VERSION ""

NS_ :

BS_:

BU_: VMCU TPM RCIOM FCIOM FAS ECUspare4 EBS EAS CCIOM BPMU APM

BO_ 1995 XCP_FA_22_Chassi: 8 RCIOM
 SG_ XCP_FA_22 : 0|64@1+ (1,0) [0|0] "" Vector__XXX

BO_ 1994 XCP_FA_21_Chassi: 8 FCIOM
 SG_ XCP_FA_21 : 0|64@1+ (1,0) [0|0] "" Vector__XXX

BO_ 1993 XCP_FA_20_Chassi: 8 CCIOM
 SG_ XCP_FA_20 : 0|64@1+ (1,0) [0|0] "" Vector__XXX

BO_ 1991 XCP_22_FA_Chassi: 8 Vector__XXX
 SG_ XCP_22_FA : 0|64@1+ (1,0) [0|0] ""  RCIOM

BO_ 1990 XCP_21_FA_Chassi: 8 Vector__XXX
 SG_ XCP_21_FA : 0|64@1+ (1,0) [0|0] ""  FCIOM

BO_ 1989 XCP_20_FA_Chassi: 8 Vector__XXX
 SG_ XCP_20_FA : 0|64@1+ (1,0) [0|0] ""  CCIOM

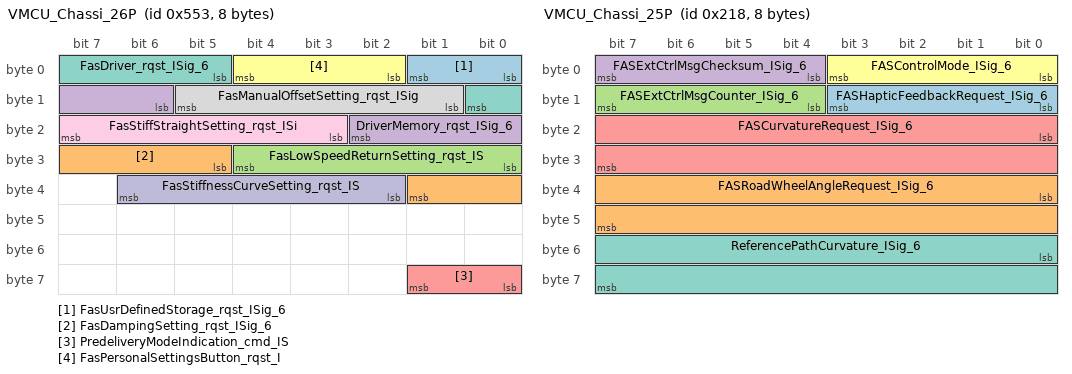
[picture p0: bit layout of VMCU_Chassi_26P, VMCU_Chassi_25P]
BO_ 1363 VMCU_Chassi_26P: 8 VMCU
 SG_ FasUsrDefinedStorage_rqst_ISig_6 : 0|2@1+ (1,0) [0|0] ""  FAS
 SG_ FasDampingSetting_rqst_ISig_6 : 29|5@1+ (1,-10) [-10|21] ""  FAS
 SG_ FasLowSpeedReturnSetting_rqst_IS : 24|5@1+ (1,-10) [-10|21] ""  FAS
 SG_ DriverMemory_rqst_ISig_6 : 14|5@1+ (1,0) [0|0] ""  FAS
 SG_ PredeliveryModeIndication_cmd_IS : 56|2@1+ (1,0) [0|0] ""  BPMU
 SG_ FasPersonalSettingsButton_rqst_I : 2|3@1+ (1,0) [0|0] ""  FAS
 SG_ FasDriver_rqst_ISig_6 : 5|4@1+ (1,0) [0|0] ""  FAS
 SG_ FasManualOffsetSetting_rqst_ISig : 9|5@1+ (1,-10) [-10|21] ""  FAS
 SG_ FasStiffStraightSetting_rqst_ISi : 19|5@1+ (1,-10) [-10|21] ""  FAS
 SG_ FasStiffnessCurveSetting_rqst_IS : 34|5@1+ (1,-10) [-10|21] ""  FAS

BO_ 536 VMCU_Chassi_25P: 8 VMCU
 SG_ FASHapticFeedbackRequest_ISig_6 : 8|4@1+ (1,0) [0|0] ""  FAS
 SG_ FASRoadWheelAngleRequest_ISig_6 : 32|16@1+ (5E-005,-1.6) [-1.6|1.67675] "rad"  FAS
 SG_ FASExtCtrlMsgCounter_ISig_6 : 12|4@1+ (1,0) [0|0] ""  FAS
 SG_ FASExtCtrlMsgChecksum_ISig_6 : 4|4@1+ (1,0) [0|0] ""  FAS
 SG_ FASCurvatureRequest_ISig_6 : 16|16@1+ (7.62939E-006,-0.2472) [-0.2472|0.25279207365] "per_meter"  FAS
 SG_ FASControlMode_ISig_6 : 0|4@1+ (0.1,0) [0|1.5] ""  FAS
 SG_ ReferencePathCurvature_ISig_6 : 48|16@1+ (7.62939E-006,-0.2472) [-0.2472|0.25279207365] "per_meter"  FAS

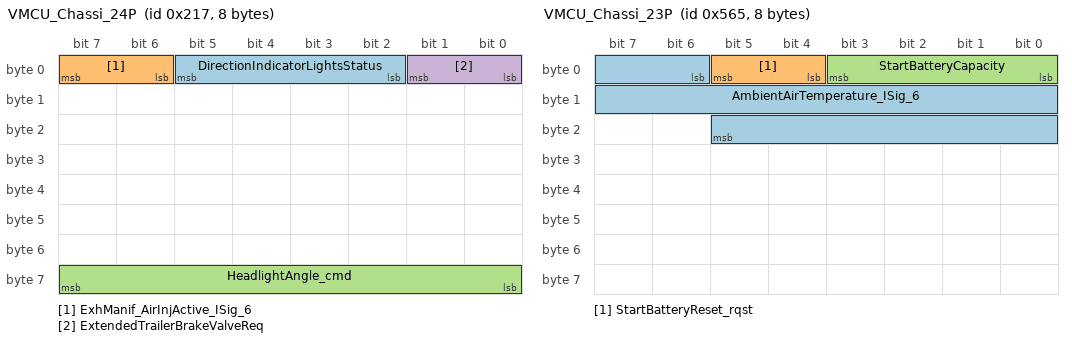
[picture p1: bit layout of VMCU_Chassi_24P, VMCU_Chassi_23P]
BO_ 535 VMCU_Chassi_24P: 8 VMCU
 SG_ DirectionIndicatorLightsStatus : 2|4@1+ (1,0) [0|0] ""  RCIOM,FCIOM
 SG_ ExhManif_AirInjActive_ISig_6 : 6|2@1+ (1,0) [0|0] ""  APM
 SG_ HeadlightAngle_cmd : 56|8@1+ (0.025,-4) [-4|2.375] "deg"  FCIOM
 SG_ ExtendedTrailerBrakeValveReq : 0|2@1+ (1,0) [0|0] ""  CCIOM

BO_ 1381 VMCU_Chassi_23P: 8 VMCU
 SG_ AmbientAirTemperature_ISig_6 : 6|16@1+ (0.03125,-273) [-273|1774.96875] "DegreeC"  BPMU,EAS,FCIOM,CCIOM,FAS,APM,TPM,RCIOM
 SG_ StartBatteryReset_rqst : 4|2@1+ (1,0) [0|0] ""  BPMU
 SG_ StartBatteryCapacity : 0|4@1+ (1,0) [0|0] ""  BPMU

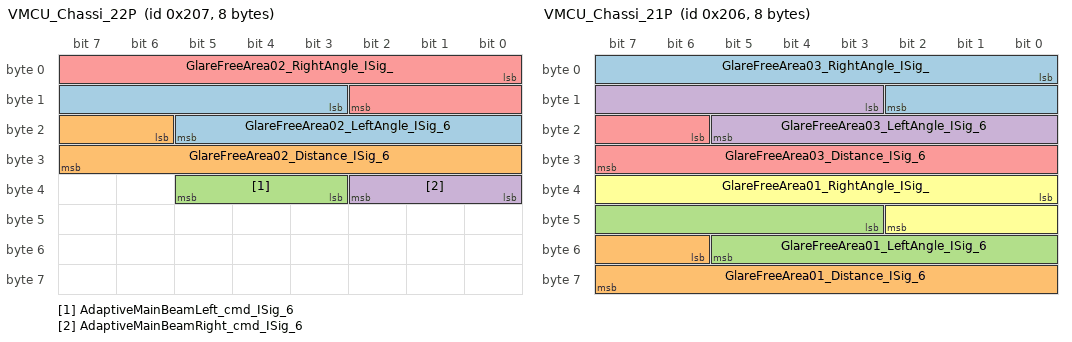
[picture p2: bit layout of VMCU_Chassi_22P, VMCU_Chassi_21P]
BO_ 519 VMCU_Chassi_22P: 8 VMCU
 SG_ GlareFreeArea02_LeftAngle_ISig_6 : 11|11@1+ (0.0494,-31.65) [-31.65|69.4718] "deg"  FCIOM
 SG_ GlareFreeArea02_Distance_ISig_6 : 22|10@1+ (0.5,0) [0|511.5] "m"  FCIOM
 SG_ AdaptiveMainBeamLeft_cmd_ISig_6 : 35|3@1+ (1,0) [0|0] ""  FCIOM
 SG_ AdaptiveMainBeamRight_cmd_ISig_6 : 32|3@1+ (1,0) [0|0] ""  FCIOM
 SG_ GlareFreeArea02_RightAngle_ISig_ : 0|11@1+ (0.0494,-31.65) [-31.65|69.4718] "deg"  FCIOM

BO_ 518 VMCU_Chassi_21P: 8 VMCU
 SG_ GlareFreeArea03_RightAngle_ISig_ : 0|11@1+ (0.0494,-31.65) [-31.65|69.4718] "deg"  FCIOM
 SG_ GlareFreeArea01_Distance_ISig_6 : 54|10@1+ (0.5,0) [0|511.5] "m"  FCIOM
 SG_ GlareFreeArea01_LeftAngle_ISig_6 : 43|11@1+ (0.0494,-31.65) [-31.65|69.4718] "deg"  FCIOM
 SG_ GlareFreeArea03_LeftAngle_ISig_6 : 11|11@1+ (0.0494,-31.65) [-31.65|69.4718] "deg"  FCIOM
 SG_ GlareFreeArea03_Distance_ISig_6 : 22|10@1+ (0.5,0) [0|511.5] "m"  FCIOM
 SG_ GlareFreeArea01_RightAngle_ISig_ : 32|11@1+ (0.0494,-31.65) [-31.65|69.4718] "deg"  FCIOM

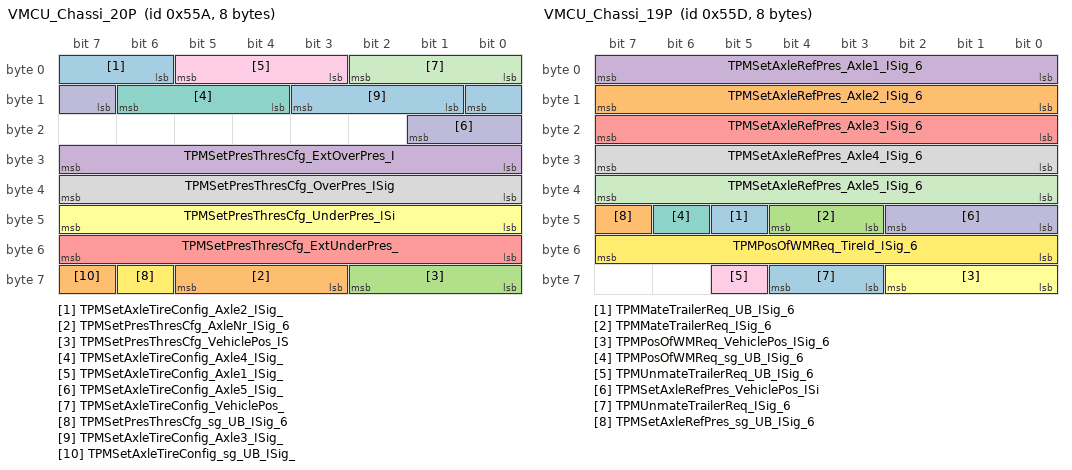
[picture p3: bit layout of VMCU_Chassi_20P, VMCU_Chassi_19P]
BO_ 1370 VMCU_Chassi_20P: 8 VMCU
 SG_ TPMSetAxleTireConfig_Axle2_ISig_ : 6|3@1+ (1,0) [0|0] ""  TPM
 SG_ TPMSetPresThresCfg_AxleNr_ISig_6 : 59|3@1+ (1,0) [0|0] ""  TPM
 SG_ TPMSetPresThresCfg_VehiclePos_IS : 56|3@1+ (1,0) [0|0] ""  TPM
 SG_ TPMSetPresThresCfg_ExtOverPres_I : 24|8@1+ (1,-125) [-125|130] "Percent"  TPM
 SG_ TPMSetPresThresCfg_ExtUnderPres_ : 48|8@1+ (1,-125) [-125|130] "Percent"  TPM
 SG_ TPMSetPresThresCfg_UnderPres_ISi : 40|8@1+ (1,-125) [-125|130] "Percent"  TPM
 SG_ TPMSetAxleTireConfig_Axle4_ISig_ : 12|3@1+ (1,0) [0|0] ""  TPM
 SG_ TPMSetPresThresCfg_OverPres_ISig : 32|8@1+ (1,-125) [-125|130] "Percent"  TPM
 SG_ TPMSetAxleTireConfig_Axle1_ISig_ : 3|3@1+ (1,0) [0|0] ""  TPM
 SG_ TPMSetAxleTireConfig_Axle5_ISig_ : 15|3@1+ (1,0) [0|0] ""  TPM
 SG_ TPMSetAxleTireConfig_VehiclePos_ : 0|3@1+ (1,0) [0|0] ""  TPM
 SG_ TPMSetPresThresCfg_sg_UB_ISig_6 : 62|1@1+ (1,0) [0|0] ""  TPM
 SG_ TPMSetAxleTireConfig_Axle3_ISig_ : 9|3@1+ (1,0) [0|0] ""  TPM
 SG_ TPMSetAxleTireConfig_sg_UB_ISig_ : 63|1@1+ (1,0) [0|0] ""  TPM

BO_ 1373 VMCU_Chassi_19P: 8 VMCU
 SG_ TPMMateTrailerReq_UB_ISig_6 : 45|1@1+ (1,0) [0|0] ""  TPM
 SG_ TPMSetAxleRefPres_Axle2_ISig_6 : 8|8@1+ (10,0) [0|2550] "kPa"  TPM
 SG_ TPMMateTrailerReq_ISig_6 : 43|2@1+ (1,0) [0|0] ""  TPM
 SG_ TPMSetAxleRefPres_Axle1_ISig_6 : 0|8@1+ (10,0) [0|2550] "kPa"  TPM
 SG_ TPMSetAxleRefPres_Axle3_ISig_6 : 16|8@1+ (10,0) [0|2550] "kPa"  TPM
 SG_ TPMPosOfWMReq_VehiclePos_ISig_6 : 56|3@1+ (1,0) [0|0] ""  TPM
 SG_ TPMPosOfWMReq_sg_UB_ISig_6 : 46|1@1+ (1,0) [0|0] ""  TPM
 SG_ TPMSetAxleRefPres_Axle4_ISig_6 : 24|8@1+ (10,0) [0|2550] "kPa"  TPM
 SG_ TPMUnmateTrailerReq_UB_ISig_6 : 61|1@1+ (1,0) [0|0] ""  TPM
 SG_ TPMSetAxleRefPres_VehiclePos_ISi : 40|3@1+ (1,0) [0|0] ""  TPM
 SG_ TPMSetAxleRefPres_Axle5_ISig_6 : 32|8@1+ (10,0) [0|2550] "kPa"  TPM
 SG_ TPMPosOfWMReq_TireId_ISig_6 : 48|8@1+ (1,0) [0|255] "NotApplicable"  TPM
 SG_ TPMUnmateTrailerReq_ISig_6 : 59|2@1+ (1,0) [0|0] ""  TPM
 SG_ TPMSetAxleRefPres_sg_UB_ISig_6 : 47|1@1+ (1,0) [0|0] ""  TPM

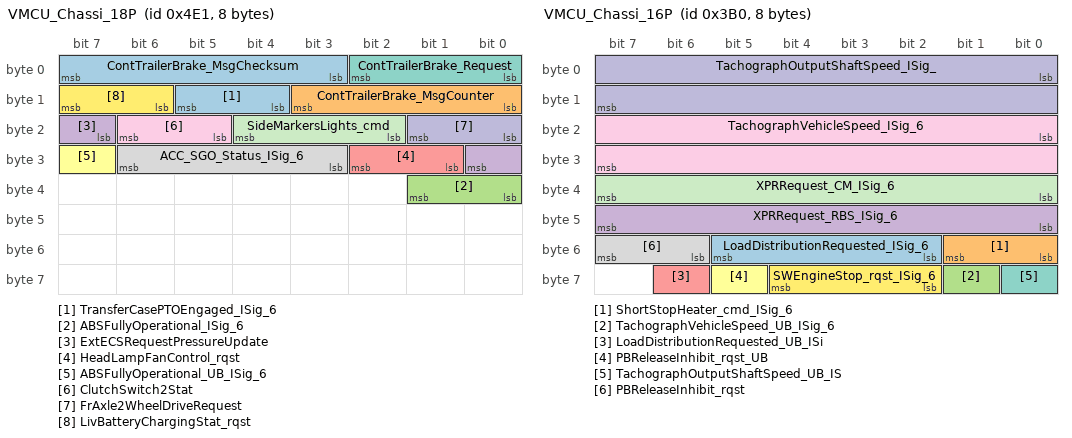
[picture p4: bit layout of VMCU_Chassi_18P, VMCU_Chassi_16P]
BO_ 1249 VMCU_Chassi_18P: 8 VMCU
 SG_ TransferCasePTOEngaged_ISig_6 : 12|2@1+ (1,0) [0|0] ""  RCIOM
 SG_ ContTrailerBrake_MsgCounter : 8|4@1+ (1,0) [0|15] "Count"  EBS
 SG_ ABSFullyOperational_ISig_6 : 32|2@1+ (1,0) [0|0] ""  APM
 SG_ ExtECSRequestPressureUpdate : 23|2@1+ (1,0) [0|0] ""  RCIOM
 SG_ HeadLampFanControl_rqst : 25|2@1+ (1,0) [0|0] ""  FCIOM
 SG_ ABSFullyOperational_UB_ISig_6 : 31|1@1+ (1,0) [0|0] ""  APM
 SG_ ContTrailerBrake_Request : 0|3@1+ (1,0) [0|0] ""  EBS
 SG_ ACC_SGO_Status_ISig_6 : 27|4@1+ (1,0) [0|0] ""  FAS
 SG_ ClutchSwitch2Stat : 21|2@1+ (1,0) [0|0] ""  CCIOM
 SG_ FrAxle2WheelDriveRequest : 16|2@1+ (1,0) [0|0] ""  CCIOM
 SG_ SideMarkersLights_cmd : 18|3@1+ (1,0) [0|0] ""  CCIOM
 SG_ LivBatteryChargingStat_rqst : 14|2@1+ (1,0) [0|0] ""  CCIOM
 SG_ ContTrailerBrake_MsgChecksum : 3|5@1+ (1,0) [0|31] ""  EBS

BO_ 1338 VMCU_Chassi_17S: 8 VMCU
 SG_ TransmEngineCrankEnable2_ISig_6 : 2|2@1+ (1,0) [0|0] ""  CCIOM
 SG_ TransmEngineCrankEnable_ISig_6 : 0|2@1+ (1,0) [0|0] ""  CCIOM

BO_ 944 VMCU_Chassi_16P: 8 VMCU
 SG_ LoadDistributionRequested_ISig_6 : 50|4@1+ (1,0) [0|0] ""  RCIOM
 SG_ ShortStopHeater_cmd_ISig_6 : 48|2@1+ (1,0) [0|0] ""  CCIOM
 SG_ TachographVehicleSpeed_UB_ISig_6 : 57|1@1+ (1,0) [0|0] ""  APM
 SG_ XPRRequest_RBS_ISig_6 : 40|8@1+ (1,0) [0|255] "NotApplicable"  APM
 SG_ LoadDistributionRequested_UB_ISi : 62|1@1+ (1,0) [0|0] ""  RCIOM
 SG_ PBReleaseInhibit_rqst_UB : 61|1@1+ (1,0) [0|0] ""  APM
 SG_ TachographOutputShaftSpeed_UB_IS : 56|1@1+ (1,0) [0|0] ""  APM
 SG_ PBReleaseInhibit_rqst : 54|2@1+ (1,0) [0|0] ""  APM
 SG_ TachographVehicleSpeed_ISig_6 : 16|16@1+ (0.00390625,0) [0|255.99609375] "Km_per_h"  APM
 SG_ TachographOutputShaftSpeed_ISig_ : 0|16@1+ (0.125,0) [0|8191.875] "rpm"  APM
 SG_ XPRRequest_CM_ISig_6 : 32|8@1+ (1,0) [0|255] "NotApplicable"  APM
 SG_ SWEngineStop_rqst_ISig_6 : 58|3@1+ (1,0) [0|0] ""  APM

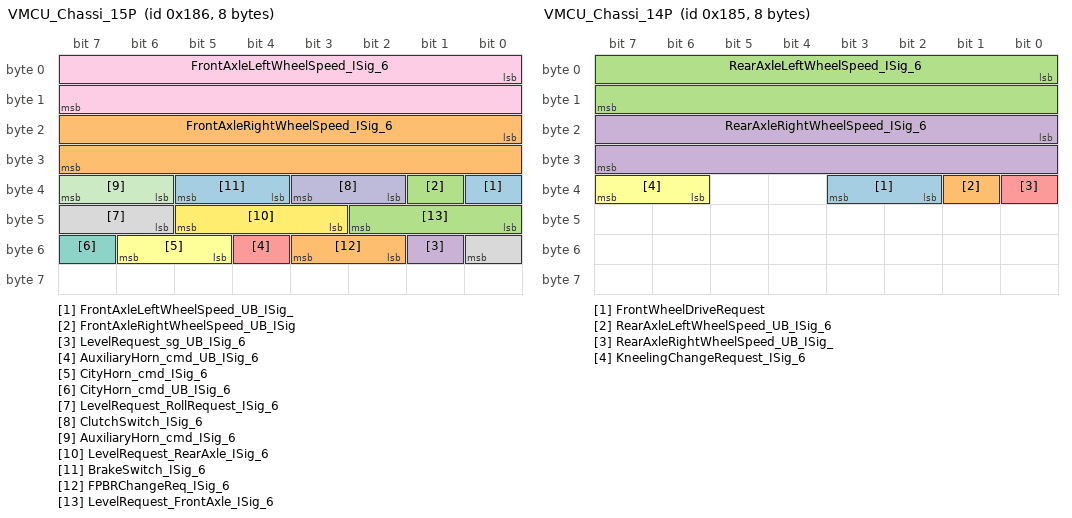
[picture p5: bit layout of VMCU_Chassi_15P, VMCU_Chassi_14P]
BO_ 390 VMCU_Chassi_15P: 8 VMCU
 SG_ FrontAxleLeftWheelSpeed_UB_ISig_ : 32|1@1+ (1,0) [0|0] ""  FAS,EAS,CCIOM
 SG_ FrontAxleRightWheelSpeed_ISig_6 : 16|16@1+ (0.00390625,0) [0|255.99609375] "Km_per_h"  CCIOM,EAS,FAS
 SG_ FrontAxleRightWheelSpeed_UB_ISig : 33|1@1+ (1,0) [0|0] ""  EAS,FAS,CCIOM
 SG_ LevelRequest_sg_UB_ISig_6 : 49|1@1+ (1,0) [0|0] ""  RCIOM
 SG_ AuxiliaryHorn_cmd_UB_ISig_6 : 52|1@1+ (1,0) [0|0] ""  FCIOM
 SG_ CityHorn_cmd_ISig_6 : 53|2@1+ (1,0) [0|0] ""  FCIOM
 SG_ CityHorn_cmd_UB_ISig_6 : 55|1@1+ (1,0) [0|0] ""  FCIOM
 SG_ LevelRequest_RollRequest_ISig_6 : 46|3@1+ (1,0) [0|0] ""  RCIOM
 SG_ FrontAxleLeftWheelSpeed_ISig_6 : 0|16@1+ (0.00390625,0) [0|255.99609375] "Km_per_h"  EAS,FAS,CCIOM
 SG_ ClutchSwitch_ISig_6 : 34|2@1+ (1,0) [0|0] ""  APM
 SG_ AuxiliaryHorn_cmd_ISig_6 : 38|2@1+ (1,0) [0|0] ""  FCIOM
 SG_ LevelRequest_RearAxle_ISig_6 : 43|3@1+ (1,0) [0|0] ""  RCIOM
 SG_ BrakeSwitch_ISig_6 : 36|2@1+ (1,0) [0|0] ""  CCIOM,APM
 SG_ FPBRChangeReq_ISig_6 : 50|2@1+ (1,0) [0|0] ""  RCIOM
 SG_ LevelRequest_FrontAxle_ISig_6 : 40|3@1+ (1,0) [0|0] ""  RCIOM

BO_ 389 VMCU_Chassi_14P: 8 VMCU
 SG_ FrontWheelDriveRequest : 34|2@1+ (1,0) [0|0] ""  CCIOM
 SG_ RearAxleLeftWheelSpeed_UB_ISig_6 : 33|1@1+ (1,0) [0|0] ""  RCIOM,CCIOM,EAS
 SG_ RearAxleLeftWheelSpeed_ISig_6 : 0|16@1+ (0.00390625,0) [0|255.99609375] "Km_per_h"  CCIOM,EAS,RCIOM
 SG_ RearAxleRightWheelSpeed_ISig_6 : 16|16@1+ (0.00390625,0) [0|255.99609375] "Km_per_h"  CCIOM,EAS,RCIOM
 SG_ RearAxleRightWheelSpeed_UB_ISig_ : 32|1@1+ (1,0) [0|0] ""  RCIOM,EAS,CCIOM
 SG_ KneelingChangeRequest_ISig_6 : 38|2@1+ (1,0) [0|0] ""  RCIOM

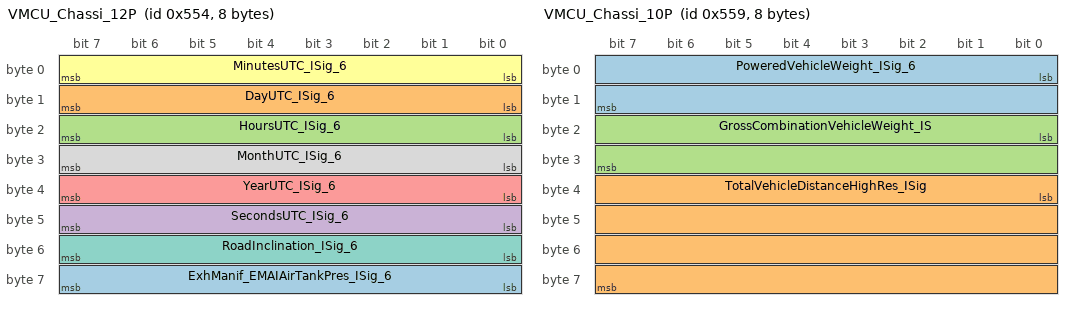
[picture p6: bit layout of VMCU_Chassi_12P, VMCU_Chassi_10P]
BO_ 1364 VMCU_Chassi_12P: 8 VMCU
 SG_ ExhManif_EMAIAirTankPres_ISig_6 : 56|8@1+ (8,0) [0|2040] "kPa"  APM
 SG_ DayUTC_ISig_6 : 8|8@1+ (0.25,0) [0|63.75] "Days"  APM,RCIOM,EAS,FAS,BPMU,FCIOM,TPM,CCIOM
 SG_ HoursUTC_ISig_6 : 16|8@1+ (1,0) [0|255] "h"  FAS,EAS,TPM,RCIOM,BPMU,CCIOM,APM,FCIOM
 SG_ SecondsUTC_ISig_6 : 40|8@1+ (0.25,0) [0|63.75] "s"  FAS,FCIOM,APM,BPMU,CCIOM,RCIOM,EAS,TPM
 SG_ YearUTC_ISig_6 : 32|8@1+ (1,1985) [1985|2240] "Years"  FAS,CCIOM,APM,RCIOM,EAS,BPMU,TPM,FCIOM
 SG_ MinutesUTC_ISig_6 : 0|8@1+ (1,0) [0|255] "min"  EAS,CCIOM,TPM,APM,RCIOM,BPMU,FCIOM,FAS
 SG_ RoadInclination_ISig_6 : 48|8@1+ (0.2,-25) [-25|26] "Percent"  RCIOM
 SG_ MonthUTC_ISig_6 : 24|8@1+ (1,0) [0|255] "Months"  CCIOM,EAS,TPM,FAS,APM,FCIOM,RCIOM,BPMU

BO_ 826 VMCU_Chassi_11P: 8 VMCU
 SG_ LampCheck_rqst_ISig_6 : 51|2@1+ (1,0) [0|0] ""  RCIOM
 SG_ PercentClutchSlip_ISig_6 : 32|8@1+ (0.4,0) [0|102] "Percent"  APM
 SG_ ChassisInstepLight_cmd : 8|2@1+ (1,0) [0|0] ""  FCIOM
 SG_ LiftAxle1DirectControl_UB_ISig_6 : 63|1@1+ (1,0) [0|0] ""  RCIOM
 SG_ RangeInhibit : 14|2@1+ (1,0) [0|0] ""  CCIOM
 SG_ ActualDrvlnRetdrPercentTorque_IS : 24|8@1+ (1,-125) [-125|130] "Percent"  APM,RCIOM
 SG_ LiftAxle1DirectControl_ISig_6 : 60|3@1+ (1,0) [0|0] ""  RCIOM
 SG_ TrailerBrakeNoEbs_stat : 22|2@1+ (1,0) [0|0] ""  RCIOM
 SG_ LEDAnimation_cmd : 53|3@1+ (1,0) [0|0] ""  FCIOM
 SG_ DoorsAjar_stat_ISig_6 : 43|3@1+ (1,0) [0|0] ""  CCIOM,APM
 SG_ BBSlidable5thWheelCmd : 1|2@1+ (1,0) [0|0] ""  CCIOM
 SG_ LampCheck_cmd_ISig_6 : 46|2@1+ (1,0) [0|0] ""  FCIOM
 SG_ BlackOutandConvoyMode_rqst_ISig_ : 40|3@1+ (1,0) [0|0] ""  CCIOM,RCIOM
 SG_ AreaInhibit : 10|2@1+ (1,0) [0|0] ""  CCIOM
 SG_ MaintBatteryReset : 20|2@1+ (1,0) [0|0] ""  CCIOM
 SG_ ECSStandByRequest_ISig_6 : 48|3@1+ (1,0) [0|0] ""  RCIOM
 SG_ DoorsAjar_stat_UB_ISig_6 : 7|1@1+ (1,0) [0|0] ""  CCIOM,APM
 SG_ PloughLampModeStatus_ISig_6 : 56|2@1+ (1,0) [0|0] ""  FCIOM
 SG_ VIN_rqst_ISig_6 : 0|1@1+ (1,0) [0|0] ""  APM
 SG_ BBContUnlockCmd : 12|2@1+ (1,0) [0|0] ""  CCIOM
 SG_ EngineActiveStatus_ISig_6 : 3|4@1+ (1,0) [0|0] ""  CCIOM
 SG_ BatteryCapacity_ISig_6 : 16|4@1+ (1,0) [0|0] ""  CCIOM

BO_ 1369 VMCU_Chassi_10P: 8 VMCU
 SG_ PoweredVehicleWeight_ISig_6 : 0|16@1+ (10,0) [0|655350] "kg"  APM
 SG_ TotalVehicleDistanceHighRes_ISig : 32|32@1+ (5,0) [0|21474836475] "m"  TPM,RCIOM,APM,BPMU,EAS,FAS,FCIOM,CCIOM
 SG_ GrossCombinationVehicleWeight_IS : 16|16@1+ (10,0) [0|655350] "kg"  APM

BO_ 946 VMCU_Chassi_09P: 8 VMCU
 SG_ TransferCaseOrSplitboxPTOMode_IS : 2|2@1+ (1,0) [0|0] ""  RCIOM
 SG_ EPBHillHolderMode_ISig_6 : 32|3@1+ (1,0) [0|0] ""  APM
 SG_ VehicleDistanceRollingCounter : 40|16@1+ (0.03125,0) [0|2047.96875] "m"  RCIOM,EBS
 SG_ RrInterAxlDiffLockActvnDrvrReq_U : 62|1@1+ (1,0) [0|0] ""  RCIOM
 SG_ Pto4Status_ISig_6 : 10|2@1+ (1,0) [0|0] ""  RCIOM
 SG_ CartridgeChangedDrvrReset_rqst : 4|2@1+ (1,0) [0|0] ""  CCIOM,APM
 SG_ Pto2Status_ISig_6 : 24|2@1+ (1,0) [0|0] ""  RCIOM
 SG_ AcceleratorPedalQuality_ISig_6 : 28|2@1+ (1,0) [0|0] ""  APM
 SG_ Pto2DrivingRequest : 6|2@1+ (1,0) [0|0] ""  CCIOM
 SG_ Pto3Status_ISig_6 : 14|2@1+ (1,0) [0|0] ""  RCIOM
 SG_ ReducedLoadMode_stat_ISig_6 : 30|2@1+ (1,0) [0|0] ""  CCIOM
 SG_ RearAxleDiffLockActvnDrvrReq_UB_ : 61|1@1+ (1,0) [0|0] ""  RCIOM
 SG_ RearAxleDiffLockActvnDrvrReq_ISi : 18|2@1+ (1,0) [0|0] ""  RCIOM
 SG_ RrInterAxlDiffLockActvnFuncReq : 26|2@1+ (1,0) [0|0] ""  RCIOM
 SG_ Pto1DrivingRequest : 12|2@1+ (1,0) [0|0] ""  CCIOM
 SG_ EngineStopRequest_ISig_6 : 56|2@1+ (1,0) [0|0] ""  APM
 SG_ AcceleratorPedalStatus_ISig_6 : 37|3@1+ (1,0) [0|0] ""  APM
 SG_ XBRActiveControlMode_ISig_6 : 20|4@1+ (1,0) [0|0] ""  APM
 SG_ RearAxleDiffLockActvnFuncReq_ISi : 16|2@1+ (1,0) [0|0] ""  RCIOM
 SG_ RrInterAxlDiffLockActvnDrvrReq_I : 8|2@1+ (1,0) [0|0] ""  RCIOM
 SG_ KeyPosition_ISig_6 : 58|3@1+ (1,0) [0|0] ""  APM
 SG_ RearAxleDiffLockActvnFuncReq_UB_ : 63|1@1+ (1,0) [0|0] ""  RCIOM
 SG_ Pto1Status_ISig_6 : 0|2@1+ (1,0) [0|0] ""  RCIOM

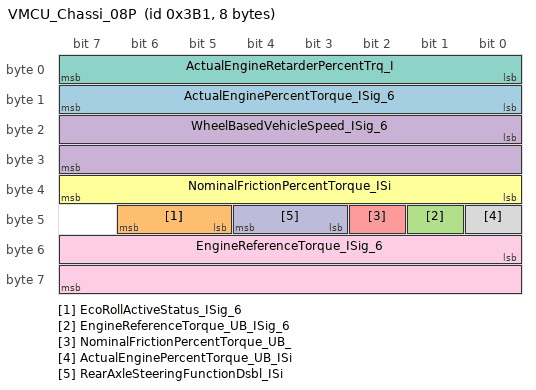
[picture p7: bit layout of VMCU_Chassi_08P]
BO_ 945 VMCU_Chassi_08P: 8 VMCU
 SG_ ActualEnginePercentTorque_ISig_6 : 8|8@1+ (1,-125) [-125|130] "Percent"  RCIOM,APM,FAS,CCIOM
 SG_ EcoRollActiveStatus_ISig_6 : 45|2@1+ (1,0) [0|0] ""  CCIOM
 SG_ EngineReferenceTorque_UB_ISig_6 : 41|1@1+ (1,0) [0|0] ""  FAS
 SG_ WheelBasedVehicleSpeed_ISig_6 : 16|16@1+ (0.00390625,0) [0|255.99609375] "Km_per_h"  CCIOM,FAS,TPM,EAS,RCIOM,APM
 SG_ NominalFrictionPercentTorque_UB_ : 42|1@1+ (1,0) [0|0] ""  APM
 SG_ NominalFrictionPercentTorque_ISi : 32|8@1+ (1,-125) [-125|130] "Percent"  APM
 SG_ ActualEngineRetarderPercentTrq_I : 0|8@1+ (1,-125) [-125|130] "Percent"  RCIOM
 SG_ ActualEnginePercentTorque_UB_ISi : 40|1@1+ (1,0) [0|0] ""  APM,FAS,RCIOM,CCIOM
 SG_ EngineReferenceTorque_ISig_6 : 48|16@1+ (1,0) [0|65535] "Nm"  FAS
 SG_ RearAxleSteeringFunctionDsbl_ISi : 43|2@1+ (1,0) [0|0] ""  EAS

CM_ "COM_MATRIX_T2_1.9.0";
CM_ BO_ 1995 "XCP interface RCIOM";
CM_ BO_ 1994 "XCP interface FCIOM";
CM_ BO_ 1993 "XCP interface CCIOM";
CM_ BO_ 1991 "XCP interface RCIOM";
CM_ BO_ 1990 "XCP interface FCIOM";
CM_ BO_ 1989 "XCP interface CCIOM";
CM_ SG_ 1363 FasDampingSetting_rqst_ISig_6 "21-29 spare
30 Error
31 NotAvailbale";
CM_ SG_ 1363 FasLowSpeedReturnSetting_rqst_IS "21-29 spare
30 Error
31 NotAvailbale";
CM_ SG_ 1363 FasManualOffsetSetting_rqst_ISig "21-29 spare
30 Error
31 NotAvailbale";
CM_ SG_ 1363 FasStiffStraightSetting_rqst_ISi "21-29 spare
30 Error
31 NotAvailbale";
CM_ SG_ 1363 FasStiffnessCurveSetting_rqst_IS "21-29 spare
30 Error
31 NotAvailbale";
CM_ SG_ 1381 AmbientAirTemperature_ISig_6 "65024 - 65279 Error ; 65280 - 65535 Not available";
CM_ BO_ 519 "Sporadic defined on this net, but periodic in reality since triggered every 20ms due to cyclic on BB2";
CM_ BO_ 518 "Sporadic defined on this net, but periodic in reality since triggered every 20ms due to cyclic on BB2";
CM_ SG_ 944 TachographVehicleSpeed_ISig_6 "65024 - 65279 Error ; 65280 - 65535 Not available";
CM_ SG_ 944 TachographOutputShaftSpeed_ISig_ "65024 - 65279 Error ; 65280 - 65535 Not available";
CM_ SG_ 390 FrontAxleRightWheelSpeed_ISig_6 "65024 - 65279 Error ; 65280 - 65535 Not available";
CM_ SG_ 390 FrontAxleLeftWheelSpeed_ISig_6 "65024 - 65279 Error ; 65280 - 65535 Not available";
CM_ SG_ 389 RearAxleLeftWheelSpeed_ISig_6 "65024 - 65279 Error ; 65280 - 65535 Not available";
CM_ SG_ 389 RearAxleRightWheelSpeed_ISig_6 "65024 - 65279 Error ; 65280 - 65535 Not available";
CM_ SG_ 1364 DayUTC_ISig_6 "254 Error ; 255 Not available";
CM_ SG_ 1364 HoursUTC_ISig_6 "254 Error ; 255 Not available";
CM_ SG_ 1364 SecondsUTC_ISig_6 "254 Error ; 255 Not available";
CM_ SG_ 1364 YearUTC_ISig_6 "254 Error ; 255 Not available";
CM_ SG_ 1364 MinutesUTC_ISig_6 "254 Error ; 255 Not available";
CM_ SG_ 1364 RoadInclination_ISig_6 "254 Error ; 255 Not available";
CM_ SG_ 1364 MonthUTC_ISig_6 "254 Error ; 255 Not available";
CM_ SG_ 826 PercentClutchSlip_ISig_6 "254 Error ; 255 Not available";
CM_ SG_ 826 ActualDrvlnRetdrPercentTorque_IS "254 Error ; 255 Not available";
CM_ SG_ 1369 PoweredVehicleWeight_ISig_6 "65024 - 65279 Error ; 65280 - 65535 Not available";
CM_ SG_ 1369 TotalVehicleDistanceHighRes_ISig "4261412864 - 4278190079 Error ; 4278190080 - 4294967295 Not available";
CM_ SG_ 1369 GrossCombinationVehicleWeight_IS "65024 - 65279 Error ; 65280 - 65535 Not available";
CM_ SG_ 945 ActualEnginePercentTorque_ISig_6 "254 Error ; 255 Not available";
CM_ SG_ 945 WheelBasedVehicleSpeed_ISig_6 "65024 - 65279 Error ; 65280 - 65535 Not available";
CM_ SG_ 945 NominalFrictionPercentTorque_ISi "254 Error ; 255 Not available";
CM_ SG_ 945 ActualEngineRetarderPercentTrq_I "254 Error ; 255 Not available";
CM_ SG_ 945 EngineReferenceTorque_ISig_6 "65024 - 65279 Error ; 65280 - 65535 Not available";
BA_DEF_ BO_  "GenMsgStartDelayTime" INT 0 0;
BA_DEF_ BO_  "GenMsgDelayTime" INT 0 0;
BA_DEF_ BO_  "GenMsgCycleTime" INT 0 0;
BA_DEF_ BO_  "GenMsgSendType" ENUM  "Cyclic","NotUsed","NotUsed","NotUsed","NotUsed","NotUsed","NotUsed","IfActive","NoMsgSendType","NotUsed";
BA_DEF_ SG_  "GenSigStartValue" INT 0 0;
BA_DEF_ SG_  "GenSigInactiveValue" INT 0 0;
BA_DEF_ SG_  "GenSigCycleTimeActive" INT 0 0;
BA_DEF_ SG_  "GenSigCycleTime" INT 0 0;
BA_DEF_ SG_  "GenSigSendType" ENUM  "Cyclic","OnWrite","OnWriteWithRepetition","OnChange","OnChangeWithRepetition","IfActive","IfActiveWithRepetition","NoSigSendType","NotUsed","NotUsed","NotUsed","NotUsed","NotUsed";
BA_DEF_  "Baudrate" INT 0 1000000;
BA_DEF_  "BusType" STRING ;
BA_DEF_  "NmType" STRING ;
BA_DEF_  "Manufacturer" STRING ;
BA_DEF_  "VersionYear" INT 0 99;
BA_DEF_  "VersionNumber" INT 0 99;
BA_DEF_  "VersionMonth" INT 1 12;
BA_DEF_  "VersionDay" INT 1 31;
BA_DEF_ BO_  "VFrameFormat" ENUM  "StandardCAN","ExtendedCAN","reserved","J1939PG";
BA_DEF_ BU_  "TpOwnSystemEcuNumber" HEX 0 255;
BA_DEF_ SG_  "SigType" ENUM  "Default","Range","RangeSigned","ASCII","Discrete","Control","ReferencePGN","DTC","StringDelimiter","StringLength","StringLengthControl";
BA_DEF_ SG_  "SeToolVersion_SIGNAL" STRING ;
BA_DEF_ SG_  "SeToolUniqueID_SIGNAL" STRING ;
BA_DEF_ SG_  "SeToolName_SIGNAL" STRING ;
BA_DEF_ SG_  "SeToolItemID_SIGNAL" STRING ;
BA_DEF_ SG_  "SeToolAncestorID_SIGNAL" STRING ;
BA_DEF_ SG_  "Platform_VMCU1_Sig" ENUM  "No","Yes";
BA_DEF_ BU_  "NmStationAddress" INT 0 255;
BA_DEF_  "NmAsrWaitBusSleepTime" INT 0 65535;
BA_DEF_  "NmAsrTimeoutTime" INT 0 65535;
BA_DEF_  "NmAsrRepeatMessageTime" INT 0 65535;
BA_DEF_ BU_  "NmAsrNodeIdentifier" HEX 0 253;
BA_DEF_ BU_  "NmAsrNode" ENUM  "No","Yes";
BA_DEF_  "NmAsrMessageCount" INT 1 256;
BA_DEF_ BO_  "NmAsrMessage" ENUM  "No","Yes";
BA_DEF_  "NmAsrCanMsgCycleTime" INT 0 65535;
BA_DEF_  "NmAsrBaseAddress" HEX 0 536870911;
BA_DEF_ SG_  "NeedsUpdateBit" ENUM  "No","Yes";
BA_DEF_ SG_  "MmAnSignal" ENUM  "No","Yes";
BA_DEF_ BU_  "IsOBDrelevant" ENUM  "No","Yes";
BA_DEF_ SG_  "GenSigMaxLatency" INT 0 65535;
BA_DEF_ SG_  "GenSigILSupport" ENUM  "Yes","No";
BA_DEF_ BO_  "GenMsgRequestable" INT 0 1;
BA_DEF_ BO_  "GenMsgILSupport" ENUM  "No","Yes";
BA_DEF_ BO_  "DiagUUDTResponse" ENUM  "No","Yes";
BA_DEF_ BO_  "DiagState" ENUM  "No","Yes";
BA_DEF_ BO_  "DiagResponse" ENUM  "No","Yes";
BA_DEF_ BO_  "DiagRequest" ENUM  "No","Yes";
BA_DEF_ BO_  "DiagConnection" HEX 0 65535;
BA_DEF_  "DBName" STRING ;
BA_DEF_ BO_  "CanTpFcFrameId" HEX 0 2147483647;
BA_DEF_ BO_  "CanTpBs" INT 0 255;
BA_DEF_ SG_  "SystemSignalLongSymbol" STRING ;
BA_DEF_REL_ BU_SG_REL_  "GenSigTimeoutTime" INT 0 65535;
BA_DEF_REL_ BU_SG_REL_  "GenSigFirstTimeoutTime" INT 0 65535;
BA_DEF_DEF_  "GenMsgStartDelayTime" 0;
BA_DEF_DEF_  "GenMsgDelayTime" 0;
BA_DEF_DEF_  "GenMsgCycleTime" 0;
BA_DEF_DEF_  "GenMsgSendType" "Cyclic";
BA_DEF_DEF_  "GenSigStartValue" 0;
BA_DEF_DEF_  "GenSigInactiveValue" 0;
BA_DEF_DEF_  "GenSigCycleTimeActive" 0;
BA_DEF_DEF_  "GenSigCycleTime" 0;
BA_DEF_DEF_  "GenSigSendType" "Cyclic";
BA_DEF_DEF_  "Baudrate" 500000;
BA_DEF_DEF_  "BusType" "";
BA_DEF_DEF_  "NmType" "";
BA_DEF_DEF_  "Manufacturer" "VOLVO_AB";
BA_DEF_DEF_  "VersionYear" 0;
BA_DEF_DEF_  "VersionNumber" 0;
BA_DEF_DEF_  "VersionMonth" 1;
BA_DEF_DEF_  "VersionDay" 1;
BA_DEF_DEF_  "VFrameFormat" "ExtendedCAN";
BA_DEF_DEF_  "TpOwnSystemEcuNumber" 0;
BA_DEF_DEF_  "SigType" "Default";
BA_DEF_DEF_  "SeToolVersion_SIGNAL" "";
BA_DEF_DEF_  "SeToolUniqueID_SIGNAL" "";
BA_DEF_DEF_  "SeToolName_SIGNAL" "";
BA_DEF_DEF_  "SeToolItemID_SIGNAL" "";
BA_DEF_DEF_  "SeToolAncestorID_SIGNAL" "";
BA_DEF_DEF_  "Platform_VMCU1_Sig" "No";
BA_DEF_DEF_  "NmStationAddress" 254;
BA_DEF_DEF_  "NmAsrWaitBusSleepTime" 750;
BA_DEF_DEF_  "NmAsrTimeoutTime" 5000;
BA_DEF_DEF_  "NmAsrRepeatMessageTime" 300;
BA_DEF_DEF_  "NmAsrNodeIdentifier" 0;
BA_DEF_DEF_  "NmAsrNode" "Yes";
BA_DEF_DEF_  "NmAsrMessageCount" 256;
BA_DEF_DEF_  "NmAsrMessage" "No";
BA_DEF_DEF_  "NmAsrCanMsgCycleTime" 200;
BA_DEF_DEF_  "NmAsrBaseAddress" 486506496;
BA_DEF_DEF_  "NeedsUpdateBit" "No";
BA_DEF_DEF_  "MmAnSignal" "No";
BA_DEF_DEF_  "IsOBDrelevant" "No";
BA_DEF_DEF_  "GenSigMaxLatency" 0;
BA_DEF_DEF_  "GenSigILSupport" "Yes";
BA_DEF_DEF_  "GenMsgRequestable" 1;
BA_DEF_DEF_  "GenMsgILSupport" "Yes";
BA_DEF_DEF_  "DiagUUDTResponse" "No";
BA_DEF_DEF_  "DiagState" "No";
BA_DEF_DEF_  "DiagResponse" "No";
BA_DEF_DEF_  "DiagRequest" "No";
BA_DEF_DEF_  "DiagConnection" 0;
BA_DEF_DEF_  "DBName" "";
BA_DEF_DEF_  "CanTpFcFrameId" 2147483647;
BA_DEF_DEF_  "CanTpBs" 255;
BA_DEF_DEF_REL_ "GenSigTimeoutTime" 0;
BA_DEF_DEF_REL_ "GenSigFirstTimeoutTime" 0;
BA_DEF_DEF_  "SystemSignalLongSymbol" "";
BA_ "NmType" "NmAsr";
BA_ "BusType" "CAN";
BA_ "VersionDay" 21;
BA_ "VersionMonth" 8;
BA_ "VersionNumber" 1;
BA_ "VersionYear" 18;
BA_ "DBName" "ChassisSubnet";
BA_ "IsOBDrelevant" BU_ VMCU 1;
BA_ "TpOwnSystemEcuNumber" BU_ VMCU 36;
BA_ "NmAsrNodeIdentifier" BU_ VMCU 36;
BA_ "TpOwnSystemEcuNumber" BU_ TPM 37;
BA_ "NmAsrNodeIdentifier" BU_ TPM 37;
BA_ "TpOwnSystemEcuNumber" BU_ RCIOM 34;
BA_ "NmAsrNodeIdentifier" BU_ RCIOM 34;
BA_ "TpOwnSystemEcuNumber" BU_ FCIOM 33;
BA_ "NmAsrNodeIdentifier" BU_ FCIOM 33;
BA_ "TpOwnSystemEcuNumber" BU_ FAS 48;
BA_ "NmAsrNodeIdentifier" BU_ FAS 48;
BA_ "TpOwnSystemEcuNumber" BU_ EBS 40;
BA_ "NmAsrNodeIdentifier" BU_ EBS 40;
BA_ "TpOwnSystemEcuNumber" BU_ EAS 49;
BA_ "NmAsrNodeIdentifier" BU_ EAS 49;
BA_ "TpOwnSystemEcuNumber" BU_ CCIOM 32;
BA_ "NmAsrNodeIdentifier" BU_ CCIOM 32;
BA_ "TpOwnSystemEcuNumber" BU_ BPMU 26;
BA_ "NmAsrNodeIdentifier" BU_ BPMU 26;
BA_ "TpOwnSystemEcuNumber" BU_ APM 35;
BA_ "NmAsrNodeIdentifier" BU_ APM 35;
BA_ "GenMsgILSupport" BO_ 1995 0;
BA_ "VFrameFormat" BO_ 1995 0;
BA_ "GenMsgSendType" BO_ 1995 8;
BA_ "GenMsgILSupport" BO_ 1994 0;
BA_ "VFrameFormat" BO_ 1994 0;
BA_ "GenMsgSendType" BO_ 1994 8;
BA_ "GenMsgILSupport" BO_ 1993 0;
BA_ "VFrameFormat" BO_ 1993 0;
BA_ "GenMsgSendType" BO_ 1993 8;
BA_ "GenMsgILSupport" BO_ 1991 0;
BA_ "VFrameFormat" BO_ 1991 0;
BA_ "GenMsgILSupport" BO_ 1990 0;
BA_ "VFrameFormat" BO_ 1990 0;
BA_ "GenMsgILSupport" BO_ 1989 0;
BA_ "VFrameFormat" BO_ 1989 0;
BA_ "VFrameFormat" BO_ 1363 0;
BA_ "GenMsgCycleTime" BO_ 1363 1000;
BA_ "GenMsgStartDelayTime" BO_ 1363 55;
BA_ "VFrameFormat" BO_ 536 0;
BA_ "GenMsgCycleTime" BO_ 536 20;
BA_ "GenMsgStartDelayTime" BO_ 536 10;
BA_ "VFrameFormat" BO_ 535 0;
BA_ "GenMsgCycleTime" BO_ 535 30;
BA_ "GenMsgStartDelayTime" BO_ 535 20;
BA_ "VFrameFormat" BO_ 1381 0;
BA_ "GenMsgCycleTime" BO_ 1381 500;
BA_ "GenMsgStartDelayTime" BO_ 1381 65;
BA_ "VFrameFormat" BO_ 519 0;
BA_ "GenMsgSendType" BO_ 519 8;
BA_ "VFrameFormat" BO_ 518 0;
BA_ "GenMsgSendType" BO_ 518 8;
BA_ "VFrameFormat" BO_ 1370 0;
BA_ "GenMsgCycleTime" BO_ 1370 500;
BA_ "GenMsgStartDelayTime" BO_ 1370 180;
BA_ "VFrameFormat" BO_ 1373 0;
BA_ "GenMsgCycleTime" BO_ 1373 500;
BA_ "GenMsgStartDelayTime" BO_ 1373 165;
BA_ "VFrameFormat" BO_ 1249 0;
BA_ "GenMsgCycleTime" BO_ 1249 100;
BA_ "GenMsgStartDelayTime" BO_ 1249 10;
BA_ "VFrameFormat" BO_ 1338 0;
BA_ "GenMsgSendType" BO_ 1338 8;
BA_ "GenMsgDelayTime" BO_ 1338 80;
BA_ "VFrameFormat" BO_ 944 0;
BA_ "GenMsgCycleTime" BO_ 944 50;
BA_ "VFrameFormat" BO_ 390 0;
BA_ "GenMsgCycleTime" BO_ 390 10;
BA_ "GenMsgStartDelayTime" BO_ 390 5;
BA_ "VFrameFormat" BO_ 389 0;
BA_ "GenMsgCycleTime" BO_ 389 10;
BA_ "GenMsgStartDelayTime" BO_ 389 5;
BA_ "VFrameFormat" BO_ 1364 0;
BA_ "GenMsgCycleTime" BO_ 1364 250;
BA_ "GenMsgStartDelayTime" BO_ 1364 50;
BA_ "VFrameFormat" BO_ 826 0;
BA_ "GenMsgCycleTime" BO_ 826 30;
BA_ "GenMsgStartDelayTime" BO_ 826 5;
BA_ "VFrameFormat" BO_ 1369 0;
BA_ "GenMsgCycleTime" BO_ 1369 500;
BA_ "GenMsgStartDelayTime" BO_ 1369 135;
BA_ "VFrameFormat" BO_ 946 0;
BA_ "GenMsgCycleTime" BO_ 946 50;
BA_ "GenMsgStartDelayTime" BO_ 946 40;
BA_ "VFrameFormat" BO_ 945 0;
BA_ "GenMsgCycleTime" BO_ 945 50;
BA_ "GenMsgStartDelayTime" BO_ 945 15;
BA_ "GenSigSendType" SG_ 1995 XCP_FA_22 7;
BA_ "GenSigSendType" SG_ 1994 XCP_FA_21 7;
BA_ "GenSigSendType" SG_ 1993 XCP_FA_20 7;
BA_ "GenSigSendType" SG_ 1991 XCP_22_FA 7;
BA_ "GenSigSendType" SG_ 1990 XCP_21_FA 7;
BA_ "GenSigSendType" SG_ 1989 XCP_20_FA 7;
BA_ "GenSigCycleTime" SG_ 1363 FasUsrDefinedStorage_rqst_ISig_6 100;
BA_ "GenSigCycleTimeActive" SG_ 1363 FasUsrDefinedStorage_rqst_ISig_6 100;
BA_ "GenSigStartValue" SG_ 1363 FasUsrDefinedStorage_rqst_ISig_6 3;
BA_ "GenSigMaxLatency" SG_ 1363 FasUsrDefinedStorage_rqst_ISig_6 998;
BA_ "GenSigCycleTime" SG_ 1363 FasDampingSetting_rqst_ISig_6 100;
BA_ "GenSigCycleTimeActive" SG_ 1363 FasDampingSetting_rqst_ISig_6 100;
BA_ "GenSigStartValue" SG_ 1363 FasDampingSetting_rqst_ISig_6 31;
BA_ "GenSigMaxLatency" SG_ 1363 FasDampingSetting_rqst_ISig_6 998;
BA_ "GenSigCycleTime" SG_ 1363 FasLowSpeedReturnSetting_rqst_IS 100;
BA_ "GenSigCycleTimeActive" SG_ 1363 FasLowSpeedReturnSetting_rqst_IS 100;
BA_ "GenSigStartValue" SG_ 1363 FasLowSpeedReturnSetting_rqst_IS 31;
BA_ "GenSigMaxLatency" SG_ 1363 FasLowSpeedReturnSetting_rqst_IS 998;
BA_ "SystemSignalLongSymbol" SG_ 1363 FasLowSpeedReturnSetting_rqst_IS "FasLowSpeedReturnSetting_rqst_ISig_6";
BA_ "GenSigCycleTime" SG_ 1363 DriverMemory_rqst_ISig_6 100;
BA_ "GenSigCycleTimeActive" SG_ 1363 DriverMemory_rqst_ISig_6 100;
BA_ "GenSigStartValue" SG_ 1363 DriverMemory_rqst_ISig_6 31;
BA_ "GenSigMaxLatency" SG_ 1363 DriverMemory_rqst_ISig_6 998;
BA_ "GenSigCycleTime" SG_ 1363 PredeliveryModeIndication_cmd_IS 100;
BA_ "GenSigCycleTimeActive" SG_ 1363 PredeliveryModeIndication_cmd_IS 100;
BA_ "GenSigStartValue" SG_ 1363 PredeliveryModeIndication_cmd_IS 3;
BA_ "SystemSignalLongSymbol" SG_ 1363 PredeliveryModeIndication_cmd_IS "PredeliveryModeIndication_cmd_ISig_6";
BA_ "GenSigCycleTime" SG_ 1363 FasPersonalSettingsButton_rqst_I 100;
BA_ "GenSigCycleTimeActive" SG_ 1363 FasPersonalSettingsButton_rqst_I 100;
BA_ "GenSigStartValue" SG_ 1363 FasPersonalSettingsButton_rqst_I 7;
BA_ "GenSigMaxLatency" SG_ 1363 FasPersonalSettingsButton_rqst_I 998;
BA_ "SystemSignalLongSymbol" SG_ 1363 FasPersonalSettingsButton_rqst_I "FasPersonalSettingsButton_rqst_ISig_6";
BA_ "GenSigCycleTime" SG_ 1363 FasDriver_rqst_ISig_6 100;
BA_ "GenSigCycleTimeActive" SG_ 1363 FasDriver_rqst_ISig_6 100;
BA_ "GenSigStartValue" SG_ 1363 FasDriver_rqst_ISig_6 15;
BA_ "GenSigMaxLatency" SG_ 1363 FasDriver_rqst_ISig_6 998;
BA_ "GenSigCycleTime" SG_ 1363 FasManualOffsetSetting_rqst_ISig 100;
BA_ "GenSigCycleTimeActive" SG_ 1363 FasManualOffsetSetting_rqst_ISig 100;
BA_ "GenSigStartValue" SG_ 1363 FasManualOffsetSetting_rqst_ISig 31;
BA_ "GenSigMaxLatency" SG_ 1363 FasManualOffsetSetting_rqst_ISig 998;
BA_ "SystemSignalLongSymbol" SG_ 1363 FasManualOffsetSetting_rqst_ISig "FasManualOffsetSetting_rqst_ISig_6";
BA_ "GenSigCycleTime" SG_ 1363 FasStiffStraightSetting_rqst_ISi 100;
BA_ "GenSigCycleTimeActive" SG_ 1363 FasStiffStraightSetting_rqst_ISi 100;
BA_ "GenSigStartValue" SG_ 1363 FasStiffStraightSetting_rqst_ISi 31;
BA_ "GenSigMaxLatency" SG_ 1363 FasStiffStraightSetting_rqst_ISi 998;
BA_ "SystemSignalLongSymbol" SG_ 1363 FasStiffStraightSetting_rqst_ISi "FasStiffStraightSetting_rqst_ISig_6";
BA_ "GenSigCycleTime" SG_ 1363 FasStiffnessCurveSetting_rqst_IS 100;
BA_ "GenSigCycleTimeActive" SG_ 1363 FasStiffnessCurveSetting_rqst_IS 100;
BA_ "GenSigStartValue" SG_ 1363 FasStiffnessCurveSetting_rqst_IS 31;
BA_ "GenSigMaxLatency" SG_ 1363 FasStiffnessCurveSetting_rqst_IS 998;
BA_ "SystemSignalLongSymbol" SG_ 1363 FasStiffnessCurveSetting_rqst_IS "FasStiffnessCurveSetting_rqst_ISig_6";
BA_ "GenSigCycleTime" SG_ 536 FASHapticFeedbackRequest_ISig_6 100;
BA_ "GenSigCycleTimeActive" SG_ 536 FASHapticFeedbackRequest_ISig_6 100;
BA_ "GenSigStartValue" SG_ 536 FASHapticFeedbackRequest_ISig_6 15;
BA_ "GenSigMaxLatency" SG_ 536 FASHapticFeedbackRequest_ISig_6 25;
BA_ "GenSigCycleTime" SG_ 536 FASRoadWheelAngleRequest_ISig_6 100;
BA_ "GenSigCycleTimeActive" SG_ 536 FASRoadWheelAngleRequest_ISig_6 100;
BA_ "GenSigStartValue" SG_ 536 FASRoadWheelAngleRequest_ISig_6 65535;
BA_ "GenSigMaxLatency" SG_ 536 FASRoadWheelAngleRequest_ISig_6 25;
BA_ "GenSigCycleTime" SG_ 536 FASExtCtrlMsgCounter_ISig_6 100;
BA_ "GenSigCycleTimeActive" SG_ 536 FASExtCtrlMsgCounter_ISig_6 100;
BA_ "GenSigMaxLatency" SG_ 536 FASExtCtrlMsgCounter_ISig_6 25;
BA_ "GenSigCycleTime" SG_ 536 FASExtCtrlMsgChecksum_ISig_6 100;
BA_ "GenSigCycleTimeActive" SG_ 536 FASExtCtrlMsgChecksum_ISig_6 100;
BA_ "GenSigMaxLatency" SG_ 536 FASExtCtrlMsgChecksum_ISig_6 25;
BA_ "GenSigCycleTime" SG_ 536 FASCurvatureRequest_ISig_6 100;
BA_ "GenSigCycleTimeActive" SG_ 536 FASCurvatureRequest_ISig_6 100;
BA_ "GenSigStartValue" SG_ 536 FASCurvatureRequest_ISig_6 65535;
BA_ "GenSigMaxLatency" SG_ 536 FASCurvatureRequest_ISig_6 25;
BA_ "GenSigCycleTime" SG_ 536 FASControlMode_ISig_6 100;
BA_ "GenSigCycleTimeActive" SG_ 536 FASControlMode_ISig_6 100;
BA_ "GenSigStartValue" SG_ 536 FASControlMode_ISig_6 15;
BA_ "GenSigMaxLatency" SG_ 536 FASControlMode_ISig_6 25;
BA_ "GenSigCycleTime" SG_ 536 ReferencePathCurvature_ISig_6 100;
BA_ "GenSigCycleTimeActive" SG_ 536 ReferencePathCurvature_ISig_6 100;
BA_ "GenSigStartValue" SG_ 536 ReferencePathCurvature_ISig_6 65535;
BA_ "GenSigMaxLatency" SG_ 536 ReferencePathCurvature_ISig_6 25;
BA_ "GenSigCycleTime" SG_ 535 DirectionIndicatorLightsStatus 100;
BA_ "GenSigCycleTimeActive" SG_ 535 DirectionIndicatorLightsStatus 100;
BA_ "GenSigStartValue" SG_ 535 DirectionIndicatorLightsStatus 15;
BA_ "GenSigMaxLatency" SG_ 535 DirectionIndicatorLightsStatus 25;
BA_ "GenSigCycleTime" SG_ 535 ExhManif_AirInjActive_ISig_6 100;
BA_ "GenSigCycleTimeActive" SG_ 535 ExhManif_AirInjActive_ISig_6 100;
BA_ "GenSigStartValue" SG_ 535 ExhManif_AirInjActive_ISig_6 3;
BA_ "GenSigCycleTime" SG_ 535 HeadlightAngle_cmd 100;
BA_ "GenSigCycleTimeActive" SG_ 535 HeadlightAngle_cmd 100;
BA_ "GenSigStartValue" SG_ 535 HeadlightAngle_cmd 255;
BA_ "GenSigCycleTime" SG_ 535 ExtendedTrailerBrakeValveReq 100;
BA_ "GenSigCycleTimeActive" SG_ 535 ExtendedTrailerBrakeValveReq 100;
BA_ "GenSigStartValue" SG_ 535 ExtendedTrailerBrakeValveReq 3;
BA_ "GenSigMaxLatency" SG_ 535 ExtendedTrailerBrakeValveReq 35;
BA_ "GenSigCycleTime" SG_ 1381 AmbientAirTemperature_ISig_6 100;
BA_ "GenSigCycleTimeActive" SG_ 1381 AmbientAirTemperature_ISig_6 100;
BA_ "GenSigStartValue" SG_ 1381 AmbientAirTemperature_ISig_6 65535;
BA_ "GenSigMaxLatency" SG_ 1381 AmbientAirTemperature_ISig_6 59;
BA_ "Platform_VMCU1_Sig" SG_ 1381 AmbientAirTemperature_ISig_6 1;
BA_ "SeToolAncestorID_SIGNAL" SG_ 1381 AmbientAirTemperature_ISig_6 "x0000001D040FEBC8";
BA_ "SeToolItemID_SIGNAL" SG_ 1381 AmbientAirTemperature_ISig_6 "x0000001D040FEBC8";
BA_ "SeToolName_SIGNAL" SG_ 1381 AmbientAirTemperature_ISig_6 "AmbientAirTemperature";
BA_ "SeToolVersion_SIGNAL" SG_ 1381 AmbientAirTemperature_ISig_6 "1";
BA_ "GenSigCycleTime" SG_ 1381 StartBatteryReset_rqst 100;
BA_ "GenSigCycleTimeActive" SG_ 1381 StartBatteryReset_rqst 100;
BA_ "GenSigStartValue" SG_ 1381 StartBatteryReset_rqst 3;
BA_ "Platform_VMCU1_Sig" SG_ 1381 StartBatteryReset_rqst 1;
BA_ "GenSigCycleTime" SG_ 1381 StartBatteryCapacity 100;
BA_ "GenSigCycleTimeActive" SG_ 1381 StartBatteryCapacity 100;
BA_ "GenSigStartValue" SG_ 1381 StartBatteryCapacity 15;
BA_ "Platform_VMCU1_Sig" SG_ 1381 StartBatteryCapacity 1;
BA_ "GenSigSendType" SG_ 519 GlareFreeArea02_LeftAngle_ISig_6 1;
BA_ "GenSigStartValue" SG_ 519 GlareFreeArea02_LeftAngle_ISig_6 2047;
BA_ "Platform_VMCU1_Sig" SG_ 519 GlareFreeArea02_LeftAngle_ISig_6 1;
BA_ "GenSigSendType" SG_ 519 GlareFreeArea02_Distance_ISig_6 1;
BA_ "GenSigStartValue" SG_ 519 GlareFreeArea02_Distance_ISig_6 1023;
BA_ "Platform_VMCU1_Sig" SG_ 519 GlareFreeArea02_Distance_ISig_6 1;
BA_ "GenSigSendType" SG_ 519 AdaptiveMainBeamLeft_cmd_ISig_6 1;
BA_ "GenSigStartValue" SG_ 519 AdaptiveMainBeamLeft_cmd_ISig_6 7;
BA_ "Platform_VMCU1_Sig" SG_ 519 AdaptiveMainBeamLeft_cmd_ISig_6 1;
BA_ "GenSigSendType" SG_ 519 AdaptiveMainBeamRight_cmd_ISig_6 1;
BA_ "GenSigStartValue" SG_ 519 AdaptiveMainBeamRight_cmd_ISig_6 7;
BA_ "Platform_VMCU1_Sig" SG_ 519 AdaptiveMainBeamRight_cmd_ISig_6 1;
BA_ "GenSigSendType" SG_ 519 GlareFreeArea02_RightAngle_ISig_ 1;
BA_ "GenSigStartValue" SG_ 519 GlareFreeArea02_RightAngle_ISig_ 2047;
BA_ "Platform_VMCU1_Sig" SG_ 519 GlareFreeArea02_RightAngle_ISig_ 1;
BA_ "SystemSignalLongSymbol" SG_ 519 GlareFreeArea02_RightAngle_ISig_ "GlareFreeArea02_RightAngle_ISig_6";
BA_ "GenSigSendType" SG_ 518 GlareFreeArea03_RightAngle_ISig_ 1;
BA_ "GenSigStartValue" SG_ 518 GlareFreeArea03_RightAngle_ISig_ 2047;
BA_ "Platform_VMCU1_Sig" SG_ 518 GlareFreeArea03_RightAngle_ISig_ 1;
BA_ "SystemSignalLongSymbol" SG_ 518 GlareFreeArea03_RightAngle_ISig_ "GlareFreeArea03_RightAngle_ISig_6";
BA_ "GenSigSendType" SG_ 518 GlareFreeArea01_Distance_ISig_6 1;
BA_ "GenSigStartValue" SG_ 518 GlareFreeArea01_Distance_ISig_6 1023;
BA_ "Platform_VMCU1_Sig" SG_ 518 GlareFreeArea01_Distance_ISig_6 1;
BA_ "GenSigSendType" SG_ 518 GlareFreeArea01_LeftAngle_ISig_6 1;
BA_ "GenSigStartValue" SG_ 518 GlareFreeArea01_LeftAngle_ISig_6 2047;
BA_ "Platform_VMCU1_Sig" SG_ 518 GlareFreeArea01_LeftAngle_ISig_6 1;
BA_ "GenSigSendType" SG_ 518 GlareFreeArea03_LeftAngle_ISig_6 1;
BA_ "GenSigStartValue" SG_ 518 GlareFreeArea03_LeftAngle_ISig_6 2047;
BA_ "Platform_VMCU1_Sig" SG_ 518 GlareFreeArea03_LeftAngle_ISig_6 1;
BA_ "GenSigSendType" SG_ 518 GlareFreeArea03_Distance_ISig_6 1;
BA_ "GenSigStartValue" SG_ 518 GlareFreeArea03_Distance_ISig_6 1023;
BA_ "Platform_VMCU1_Sig" SG_ 518 GlareFreeArea03_Distance_ISig_6 1;
BA_ "GenSigSendType" SG_ 518 GlareFreeArea01_RightAngle_ISig_ 1;
BA_ "GenSigStartValue" SG_ 518 GlareFreeArea01_RightAngle_ISig_ 2047;
BA_ "Platform_VMCU1_Sig" SG_ 518 GlareFreeArea01_RightAngle_ISig_ 1;
BA_ "SystemSignalLongSymbol" SG_ 518 GlareFreeArea01_RightAngle_ISig_ "GlareFreeArea01_RightAngle_ISig_6";
BA_ "GenSigCycleTime" SG_ 1370 TPMSetAxleTireConfig_Axle2_ISig_ 100;
BA_ "GenSigCycleTimeActive" SG_ 1370 TPMSetAxleTireConfig_Axle2_ISig_ 100;
BA_ "GenSigStartValue" SG_ 1370 TPMSetAxleTireConfig_Axle2_ISig_ 7;
BA_ "NeedsUpdateBit" SG_ 1370 TPMSetAxleTireConfig_Axle2_ISig_ 1;
BA_ "Platform_VMCU1_Sig" SG_ 1370 TPMSetAxleTireConfig_Axle2_ISig_ 1;
BA_ "SystemSignalLongSymbol" SG_ 1370 TPMSetAxleTireConfig_Axle2_ISig_ "TPMSetAxleTireConfig_Axle2_ISig_6";
BA_ "GenSigCycleTime" SG_ 1370 TPMSetPresThresCfg_AxleNr_ISig_6 100;
BA_ "GenSigCycleTimeActive" SG_ 1370 TPMSetPresThresCfg_AxleNr_ISig_6 100;
BA_ "GenSigStartValue" SG_ 1370 TPMSetPresThresCfg_AxleNr_ISig_6 7;
BA_ "NeedsUpdateBit" SG_ 1370 TPMSetPresThresCfg_AxleNr_ISig_6 1;
BA_ "Platform_VMCU1_Sig" SG_ 1370 TPMSetPresThresCfg_AxleNr_ISig_6 1;
BA_ "GenSigCycleTime" SG_ 1370 TPMSetPresThresCfg_VehiclePos_IS 100;
BA_ "GenSigCycleTimeActive" SG_ 1370 TPMSetPresThresCfg_VehiclePos_IS 100;
BA_ "GenSigStartValue" SG_ 1370 TPMSetPresThresCfg_VehiclePos_IS 7;
BA_ "NeedsUpdateBit" SG_ 1370 TPMSetPresThresCfg_VehiclePos_IS 1;
BA_ "Platform_VMCU1_Sig" SG_ 1370 TPMSetPresThresCfg_VehiclePos_IS 1;
BA_ "SystemSignalLongSymbol" SG_ 1370 TPMSetPresThresCfg_VehiclePos_IS "TPMSetPresThresCfg_VehiclePos_ISig_6";
BA_ "GenSigCycleTime" SG_ 1370 TPMSetPresThresCfg_ExtOverPres_I 100;
BA_ "GenSigCycleTimeActive" SG_ 1370 TPMSetPresThresCfg_ExtOverPres_I 100;
BA_ "GenSigStartValue" SG_ 1370 TPMSetPresThresCfg_ExtOverPres_I 255;
BA_ "NeedsUpdateBit" SG_ 1370 TPMSetPresThresCfg_ExtOverPres_I 1;
BA_ "Platform_VMCU1_Sig" SG_ 1370 TPMSetPresThresCfg_ExtOverPres_I 1;
BA_ "SystemSignalLongSymbol" SG_ 1370 TPMSetPresThresCfg_ExtOverPres_I "TPMSetPresThresCfg_ExtOverPres_ISig_6";
BA_ "GenSigCycleTime" SG_ 1370 TPMSetPresThresCfg_ExtUnderPres_ 100;
BA_ "GenSigCycleTimeActive" SG_ 1370 TPMSetPresThresCfg_ExtUnderPres_ 100;
BA_ "GenSigStartValue" SG_ 1370 TPMSetPresThresCfg_ExtUnderPres_ 255;
BA_ "NeedsUpdateBit" SG_ 1370 TPMSetPresThresCfg_ExtUnderPres_ 1;
BA_ "Platform_VMCU1_Sig" SG_ 1370 TPMSetPresThresCfg_ExtUnderPres_ 1;
BA_ "SystemSignalLongSymbol" SG_ 1370 TPMSetPresThresCfg_ExtUnderPres_ "TPMSetPresThresCfg_ExtUnderPres_ISig_6";
BA_ "GenSigCycleTime" SG_ 1370 TPMSetPresThresCfg_UnderPres_ISi 100;
BA_ "GenSigCycleTimeActive" SG_ 1370 TPMSetPresThresCfg_UnderPres_ISi 100;
BA_ "GenSigStartValue" SG_ 1370 TPMSetPresThresCfg_UnderPres_ISi 255;
BA_ "NeedsUpdateBit" SG_ 1370 TPMSetPresThresCfg_UnderPres_ISi 1;
BA_ "Platform_VMCU1_Sig" SG_ 1370 TPMSetPresThresCfg_UnderPres_ISi 1;
BA_ "SystemSignalLongSymbol" SG_ 1370 TPMSetPresThresCfg_UnderPres_ISi "TPMSetPresThresCfg_UnderPres_ISig_6";
BA_ "GenSigCycleTime" SG_ 1370 TPMSetAxleTireConfig_Axle4_ISig_ 100;
BA_ "GenSigCycleTimeActive" SG_ 1370 TPMSetAxleTireConfig_Axle4_ISig_ 100;
BA_ "GenSigStartValue" SG_ 1370 TPMSetAxleTireConfig_Axle4_ISig_ 7;
BA_ "NeedsUpdateBit" SG_ 1370 TPMSetAxleTireConfig_Axle4_ISig_ 1;
BA_ "Platform_VMCU1_Sig" SG_ 1370 TPMSetAxleTireConfig_Axle4_ISig_ 1;
BA_ "SystemSignalLongSymbol" SG_ 1370 TPMSetAxleTireConfig_Axle4_ISig_ "TPMSetAxleTireConfig_Axle4_ISig_6";
BA_ "GenSigCycleTime" SG_ 1370 TPMSetPresThresCfg_OverPres_ISig 100;
BA_ "GenSigCycleTimeActive" SG_ 1370 TPMSetPresThresCfg_OverPres_ISig 100;
BA_ "GenSigStartValue" SG_ 1370 TPMSetPresThresCfg_OverPres_ISig 255;
BA_ "NeedsUpdateBit" SG_ 1370 TPMSetPresThresCfg_OverPres_ISig 1;
BA_ "Platform_VMCU1_Sig" SG_ 1370 TPMSetPresThresCfg_OverPres_ISig 1;
BA_ "SystemSignalLongSymbol" SG_ 1370 TPMSetPresThresCfg_OverPres_ISig "TPMSetPresThresCfg_OverPres_ISig_6";
BA_ "GenSigCycleTime" SG_ 1370 TPMSetAxleTireConfig_Axle1_ISig_ 100;
BA_ "GenSigCycleTimeActive" SG_ 1370 TPMSetAxleTireConfig_Axle1_ISig_ 100;
BA_ "GenSigStartValue" SG_ 1370 TPMSetAxleTireConfig_Axle1_ISig_ 7;
BA_ "NeedsUpdateBit" SG_ 1370 TPMSetAxleTireConfig_Axle1_ISig_ 1;
BA_ "Platform_VMCU1_Sig" SG_ 1370 TPMSetAxleTireConfig_Axle1_ISig_ 1;
BA_ "SystemSignalLongSymbol" SG_ 1370 TPMSetAxleTireConfig_Axle1_ISig_ "TPMSetAxleTireConfig_Axle1_ISig_6";
BA_ "GenSigCycleTime" SG_ 1370 TPMSetAxleTireConfig_Axle5_ISig_ 100;
BA_ "GenSigCycleTimeActive" SG_ 1370 TPMSetAxleTireConfig_Axle5_ISig_ 100;
BA_ "GenSigStartValue" SG_ 1370 TPMSetAxleTireConfig_Axle5_ISig_ 7;
BA_ "NeedsUpdateBit" SG_ 1370 TPMSetAxleTireConfig_Axle5_ISig_ 1;
BA_ "Platform_VMCU1_Sig" SG_ 1370 TPMSetAxleTireConfig_Axle5_ISig_ 1;
BA_ "SystemSignalLongSymbol" SG_ 1370 TPMSetAxleTireConfig_Axle5_ISig_ "TPMSetAxleTireConfig_Axle5_ISig_6";
BA_ "GenSigCycleTime" SG_ 1370 TPMSetAxleTireConfig_VehiclePos_ 100;
BA_ "GenSigCycleTimeActive" SG_ 1370 TPMSetAxleTireConfig_VehiclePos_ 100;
BA_ "GenSigStartValue" SG_ 1370 TPMSetAxleTireConfig_VehiclePos_ 7;
BA_ "NeedsUpdateBit" SG_ 1370 TPMSetAxleTireConfig_VehiclePos_ 1;
BA_ "Platform_VMCU1_Sig" SG_ 1370 TPMSetAxleTireConfig_VehiclePos_ 1;
BA_ "SystemSignalLongSymbol" SG_ 1370 TPMSetAxleTireConfig_VehiclePos_ "TPMSetAxleTireConfig_VehiclePos_ISig_6";
BA_ "GenSigSendType" SG_ 1370 TPMSetPresThresCfg_sg_UB_ISig_6 7;
BA_ "GenSigCycleTime" SG_ 1370 TPMSetPresThresCfg_sg_UB_ISig_6 100;
BA_ "GenSigCycleTimeActive" SG_ 1370 TPMSetPresThresCfg_sg_UB_ISig_6 100;
BA_ "Platform_VMCU1_Sig" SG_ 1370 TPMSetPresThresCfg_sg_UB_ISig_6 1;
BA_ "GenSigCycleTime" SG_ 1370 TPMSetAxleTireConfig_Axle3_ISig_ 100;
BA_ "GenSigCycleTimeActive" SG_ 1370 TPMSetAxleTireConfig_Axle3_ISig_ 100;
BA_ "GenSigStartValue" SG_ 1370 TPMSetAxleTireConfig_Axle3_ISig_ 7;
BA_ "NeedsUpdateBit" SG_ 1370 TPMSetAxleTireConfig_Axle3_ISig_ 1;
BA_ "Platform_VMCU1_Sig" SG_ 1370 TPMSetAxleTireConfig_Axle3_ISig_ 1;
BA_ "SystemSignalLongSymbol" SG_ 1370 TPMSetAxleTireConfig_Axle3_ISig_ "TPMSetAxleTireConfig_Axle3_ISig_6";
BA_ "GenSigSendType" SG_ 1370 TPMSetAxleTireConfig_sg_UB_ISig_ 7;
BA_ "GenSigCycleTime" SG_ 1370 TPMSetAxleTireConfig_sg_UB_ISig_ 100;
BA_ "GenSigCycleTimeActive" SG_ 1370 TPMSetAxleTireConfig_sg_UB_ISig_ 100;
BA_ "Platform_VMCU1_Sig" SG_ 1370 TPMSetAxleTireConfig_sg_UB_ISig_ 1;
BA_ "SystemSignalLongSymbol" SG_ 1370 TPMSetAxleTireConfig_sg_UB_ISig_ "TPMSetAxleTireConfig_sg_UB_ISig_6";
BA_ "GenSigSendType" SG_ 1373 TPMMateTrailerReq_UB_ISig_6 7;
BA_ "GenSigCycleTime" SG_ 1373 TPMMateTrailerReq_UB_ISig_6 100;
BA_ "GenSigCycleTimeActive" SG_ 1373 TPMMateTrailerReq_UB_ISig_6 100;
BA_ "Platform_VMCU1_Sig" SG_ 1373 TPMMateTrailerReq_UB_ISig_6 1;
BA_ "GenSigCycleTime" SG_ 1373 TPMSetAxleRefPres_Axle2_ISig_6 100;
BA_ "GenSigCycleTimeActive" SG_ 1373 TPMSetAxleRefPres_Axle2_ISig_6 100;
BA_ "GenSigStartValue" SG_ 1373 TPMSetAxleRefPres_Axle2_ISig_6 255;
BA_ "NeedsUpdateBit" SG_ 1373 TPMSetAxleRefPres_Axle2_ISig_6 1;
BA_ "Platform_VMCU1_Sig" SG_ 1373 TPMSetAxleRefPres_Axle2_ISig_6 1;
BA_ "GenSigCycleTime" SG_ 1373 TPMMateTrailerReq_ISig_6 100;
BA_ "GenSigCycleTimeActive" SG_ 1373 TPMMateTrailerReq_ISig_6 100;
BA_ "GenSigStartValue" SG_ 1373 TPMMateTrailerReq_ISig_6 3;
BA_ "NeedsUpdateBit" SG_ 1373 TPMMateTrailerReq_ISig_6 1;
BA_ "Platform_VMCU1_Sig" SG_ 1373 TPMMateTrailerReq_ISig_6 1;
BA_ "GenSigCycleTime" SG_ 1373 TPMSetAxleRefPres_Axle1_ISig_6 100;
BA_ "GenSigCycleTimeActive" SG_ 1373 TPMSetAxleRefPres_Axle1_ISig_6 100;
BA_ "GenSigStartValue" SG_ 1373 TPMSetAxleRefPres_Axle1_ISig_6 255;
BA_ "NeedsUpdateBit" SG_ 1373 TPMSetAxleRefPres_Axle1_ISig_6 1;
BA_ "Platform_VMCU1_Sig" SG_ 1373 TPMSetAxleRefPres_Axle1_ISig_6 1;
BA_ "GenSigCycleTime" SG_ 1373 TPMSetAxleRefPres_Axle3_ISig_6 100;
BA_ "GenSigCycleTimeActive" SG_ 1373 TPMSetAxleRefPres_Axle3_ISig_6 100;
BA_ "GenSigStartValue" SG_ 1373 TPMSetAxleRefPres_Axle3_ISig_6 255;
BA_ "NeedsUpdateBit" SG_ 1373 TPMSetAxleRefPres_Axle3_ISig_6 1;
BA_ "Platform_VMCU1_Sig" SG_ 1373 TPMSetAxleRefPres_Axle3_ISig_6 1;
BA_ "GenSigCycleTime" SG_ 1373 TPMPosOfWMReq_VehiclePos_ISig_6 100;
BA_ "GenSigCycleTimeActive" SG_ 1373 TPMPosOfWMReq_VehiclePos_ISig_6 100;
BA_ "GenSigStartValue" SG_ 1373 TPMPosOfWMReq_VehiclePos_ISig_6 7;
BA_ "NeedsUpdateBit" SG_ 1373 TPMPosOfWMReq_VehiclePos_ISig_6 1;
BA_ "Platform_VMCU1_Sig" SG_ 1373 TPMPosOfWMReq_VehiclePos_ISig_6 1;
BA_ "GenSigSendType" SG_ 1373 TPMPosOfWMReq_sg_UB_ISig_6 7;
BA_ "GenSigCycleTime" SG_ 1373 TPMPosOfWMReq_sg_UB_ISig_6 100;
BA_ "GenSigCycleTimeActive" SG_ 1373 TPMPosOfWMReq_sg_UB_ISig_6 100;
BA_ "Platform_VMCU1_Sig" SG_ 1373 TPMPosOfWMReq_sg_UB_ISig_6 1;
BA_ "GenSigCycleTime" SG_ 1373 TPMSetAxleRefPres_Axle4_ISig_6 100;
BA_ "GenSigCycleTimeActive" SG_ 1373 TPMSetAxleRefPres_Axle4_ISig_6 100;
BA_ "GenSigStartValue" SG_ 1373 TPMSetAxleRefPres_Axle4_ISig_6 255;
BA_ "NeedsUpdateBit" SG_ 1373 TPMSetAxleRefPres_Axle4_ISig_6 1;
BA_ "Platform_VMCU1_Sig" SG_ 1373 TPMSetAxleRefPres_Axle4_ISig_6 1;
BA_ "GenSigSendType" SG_ 1373 TPMUnmateTrailerReq_UB_ISig_6 7;
BA_ "GenSigCycleTime" SG_ 1373 TPMUnmateTrailerReq_UB_ISig_6 100;
BA_ "GenSigCycleTimeActive" SG_ 1373 TPMUnmateTrailerReq_UB_ISig_6 100;
BA_ "Platform_VMCU1_Sig" SG_ 1373 TPMUnmateTrailerReq_UB_ISig_6 1;
BA_ "GenSigCycleTime" SG_ 1373 TPMSetAxleRefPres_VehiclePos_ISi 100;
BA_ "GenSigCycleTimeActive" SG_ 1373 TPMSetAxleRefPres_VehiclePos_ISi 100;
BA_ "GenSigStartValue" SG_ 1373 TPMSetAxleRefPres_VehiclePos_ISi 7;
BA_ "NeedsUpdateBit" SG_ 1373 TPMSetAxleRefPres_VehiclePos_ISi 1;
BA_ "Platform_VMCU1_Sig" SG_ 1373 TPMSetAxleRefPres_VehiclePos_ISi 1;
BA_ "SystemSignalLongSymbol" SG_ 1373 TPMSetAxleRefPres_VehiclePos_ISi "TPMSetAxleRefPres_VehiclePos_ISig_6";
BA_ "GenSigCycleTime" SG_ 1373 TPMSetAxleRefPres_Axle5_ISig_6 100;
BA_ "GenSigCycleTimeActive" SG_ 1373 TPMSetAxleRefPres_Axle5_ISig_6 100;
BA_ "GenSigStartValue" SG_ 1373 TPMSetAxleRefPres_Axle5_ISig_6 255;
BA_ "NeedsUpdateBit" SG_ 1373 TPMSetAxleRefPres_Axle5_ISig_6 1;
BA_ "Platform_VMCU1_Sig" SG_ 1373 TPMSetAxleRefPres_Axle5_ISig_6 1;
BA_ "GenSigCycleTime" SG_ 1373 TPMPosOfWMReq_TireId_ISig_6 100;
BA_ "GenSigCycleTimeActive" SG_ 1373 TPMPosOfWMReq_TireId_ISig_6 100;
BA_ "NeedsUpdateBit" SG_ 1373 TPMPosOfWMReq_TireId_ISig_6 1;
BA_ "Platform_VMCU1_Sig" SG_ 1373 TPMPosOfWMReq_TireId_ISig_6 1;
BA_ "GenSigCycleTime" SG_ 1373 TPMUnmateTrailerReq_ISig_6 100;
BA_ "GenSigCycleTimeActive" SG_ 1373 TPMUnmateTrailerReq_ISig_6 100;
BA_ "GenSigStartValue" SG_ 1373 TPMUnmateTrailerReq_ISig_6 3;
BA_ "NeedsUpdateBit" SG_ 1373 TPMUnmateTrailerReq_ISig_6 1;
BA_ "Platform_VMCU1_Sig" SG_ 1373 TPMUnmateTrailerReq_ISig_6 1;
BA_ "GenSigSendType" SG_ 1373 TPMSetAxleRefPres_sg_UB_ISig_6 7;
BA_ "GenSigCycleTime" SG_ 1373 TPMSetAxleRefPres_sg_UB_ISig_6 100;
BA_ "GenSigCycleTimeActive" SG_ 1373 TPMSetAxleRefPres_sg_UB_ISig_6 100;
BA_ "Platform_VMCU1_Sig" SG_ 1373 TPMSetAxleRefPres_sg_UB_ISig_6 1;
BA_ "GenSigCycleTime" SG_ 1249 TransferCasePTOEngaged_ISig_6 100;
BA_ "GenSigCycleTimeActive" SG_ 1249 TransferCasePTOEngaged_ISig_6 100;
BA_ "GenSigStartValue" SG_ 1249 TransferCasePTOEngaged_ISig_6 3;
BA_ "Platform_VMCU1_Sig" SG_ 1249 TransferCasePTOEngaged_ISig_6 1;
BA_ "GenSigCycleTime" SG_ 1249 ContTrailerBrake_MsgCounter 100;
BA_ "GenSigCycleTimeActive" SG_ 1249 ContTrailerBrake_MsgCounter 100;
BA_ "GenSigStartValue" SG_ 1249 ContTrailerBrake_MsgCounter 15;
BA_ "Platform_VMCU1_Sig" SG_ 1249 ContTrailerBrake_MsgCounter 1;
BA_ "GenSigCycleTime" SG_ 1249 ABSFullyOperational_ISig_6 100;
BA_ "GenSigCycleTimeActive" SG_ 1249 ABSFullyOperational_ISig_6 100;
BA_ "GenSigStartValue" SG_ 1249 ABSFullyOperational_ISig_6 3;
BA_ "NeedsUpdateBit" SG_ 1249 ABSFullyOperational_ISig_6 1;
BA_ "SeToolAncestorID_SIGNAL" SG_ 1249 ABSFullyOperational_ISig_6 "x0000001D0410DB72";
BA_ "SeToolItemID_SIGNAL" SG_ 1249 ABSFullyOperational_ISig_6 "x0000001D0410DB72";
BA_ "SeToolName_SIGNAL" SG_ 1249 ABSFullyOperational_ISig_6 "ABSFullyOperational";
BA_ "SeToolVersion_SIGNAL" SG_ 1249 ABSFullyOperational_ISig_6 "1";
BA_ "GenSigCycleTime" SG_ 1249 ExtECSRequestPressureUpdate 100;
BA_ "GenSigCycleTimeActive" SG_ 1249 ExtECSRequestPressureUpdate 100;
BA_ "GenSigStartValue" SG_ 1249 ExtECSRequestPressureUpdate 3;
BA_ "GenSigCycleTime" SG_ 1249 HeadLampFanControl_rqst 100;
BA_ "GenSigCycleTimeActive" SG_ 1249 HeadLampFanControl_rqst 100;
BA_ "GenSigStartValue" SG_ 1249 HeadLampFanControl_rqst 3;
BA_ "GenSigSendType" SG_ 1249 ABSFullyOperational_UB_ISig_6 7;
BA_ "GenSigCycleTime" SG_ 1249 ContTrailerBrake_Request 100;
BA_ "GenSigCycleTimeActive" SG_ 1249 ContTrailerBrake_Request 100;
BA_ "GenSigStartValue" SG_ 1249 ContTrailerBrake_Request 7;
BA_ "Platform_VMCU1_Sig" SG_ 1249 ContTrailerBrake_Request 1;
BA_ "GenSigCycleTime" SG_ 1249 ACC_SGO_Status_ISig_6 100;
BA_ "GenSigCycleTimeActive" SG_ 1249 ACC_SGO_Status_ISig_6 100;
BA_ "GenSigStartValue" SG_ 1249 ACC_SGO_Status_ISig_6 15;
BA_ "GenSigCycleTime" SG_ 1249 ClutchSwitch2Stat 100;
BA_ "GenSigCycleTimeActive" SG_ 1249 ClutchSwitch2Stat 100;
BA_ "GenSigStartValue" SG_ 1249 ClutchSwitch2Stat 3;
BA_ "Platform_VMCU1_Sig" SG_ 1249 ClutchSwitch2Stat 1;
BA_ "GenSigCycleTime" SG_ 1249 FrAxle2WheelDriveRequest 100;
BA_ "GenSigCycleTimeActive" SG_ 1249 FrAxle2WheelDriveRequest 100;
BA_ "GenSigStartValue" SG_ 1249 FrAxle2WheelDriveRequest 3;
BA_ "Platform_VMCU1_Sig" SG_ 1249 FrAxle2WheelDriveRequest 1;
BA_ "GenSigCycleTime" SG_ 1249 SideMarkersLights_cmd 100;
BA_ "GenSigCycleTimeActive" SG_ 1249 SideMarkersLights_cmd 100;
BA_ "GenSigStartValue" SG_ 1249 SideMarkersLights_cmd 7;
BA_ "Platform_VMCU1_Sig" SG_ 1249 SideMarkersLights_cmd 1;
BA_ "GenSigCycleTime" SG_ 1249 LivBatteryChargingStat_rqst 100;
BA_ "GenSigCycleTimeActive" SG_ 1249 LivBatteryChargingStat_rqst 100;
BA_ "GenSigStartValue" SG_ 1249 LivBatteryChargingStat_rqst 3;
BA_ "GenSigCycleTime" SG_ 1249 ContTrailerBrake_MsgChecksum 100;
BA_ "GenSigCycleTimeActive" SG_ 1249 ContTrailerBrake_MsgChecksum 100;
BA_ "GenSigStartValue" SG_ 1249 ContTrailerBrake_MsgChecksum 31;
BA_ "Platform_VMCU1_Sig" SG_ 1249 ContTrailerBrake_MsgChecksum 1;
BA_ "GenSigSendType" SG_ 1338 TransmEngineCrankEnable2_ISig_6 1;
BA_ "GenSigStartValue" SG_ 1338 TransmEngineCrankEnable2_ISig_6 3;
BA_ "Platform_VMCU1_Sig" SG_ 1338 TransmEngineCrankEnable2_ISig_6 1;
BA_ "GenSigSendType" SG_ 1338 TransmEngineCrankEnable_ISig_6 1;
BA_ "GenSigStartValue" SG_ 1338 TransmEngineCrankEnable_ISig_6 3;
BA_ "GenSigMaxLatency" SG_ 1338 TransmEngineCrankEnable_ISig_6 24;
BA_ "Platform_VMCU1_Sig" SG_ 1338 TransmEngineCrankEnable_ISig_6 1;
BA_ "SeToolAncestorID_SIGNAL" SG_ 1338 TransmEngineCrankEnable_ISig_6 "x0000001D041FEE2F";
BA_ "SeToolItemID_SIGNAL" SG_ 1338 TransmEngineCrankEnable_ISig_6 "x0000001D041FEE2F";
BA_ "SeToolName_SIGNAL" SG_ 1338 TransmEngineCrankEnable_ISig_6 "TransmEngineCrankEnable";
BA_ "SeToolVersion_SIGNAL" SG_ 1338 TransmEngineCrankEnable_ISig_6 "1";
BA_ "GenSigCycleTime" SG_ 944 LoadDistributionRequested_ISig_6 100;
BA_ "GenSigCycleTimeActive" SG_ 944 LoadDistributionRequested_ISig_6 100;
BA_ "GenSigStartValue" SG_ 944 LoadDistributionRequested_ISig_6 15;
BA_ "NeedsUpdateBit" SG_ 944 LoadDistributionRequested_ISig_6 1;
BA_ "Platform_VMCU1_Sig" SG_ 944 LoadDistributionRequested_ISig_6 1;
BA_ "GenSigCycleTime" SG_ 944 ShortStopHeater_cmd_ISig_6 100;
BA_ "GenSigCycleTimeActive" SG_ 944 ShortStopHeater_cmd_ISig_6 100;
BA_ "GenSigStartValue" SG_ 944 ShortStopHeater_cmd_ISig_6 3;
BA_ "Platform_VMCU1_Sig" SG_ 944 ShortStopHeater_cmd_ISig_6 1;
BA_ "GenSigSendType" SG_ 944 TachographVehicleSpeed_UB_ISig_6 7;
BA_ "Platform_VMCU1_Sig" SG_ 944 TachographVehicleSpeed_UB_ISig_6 1;
BA_ "GenSigCycleTime" SG_ 944 XPRRequest_RBS_ISig_6 100;
BA_ "GenSigCycleTimeActive" SG_ 944 XPRRequest_RBS_ISig_6 100;
BA_ "GenSigStartValue" SG_ 944 XPRRequest_RBS_ISig_6 255;
BA_ "Platform_VMCU1_Sig" SG_ 944 XPRRequest_RBS_ISig_6 1;
BA_ "GenSigSendType" SG_ 944 LoadDistributionRequested_UB_ISi 7;
BA_ "Platform_VMCU1_Sig" SG_ 944 LoadDistributionRequested_UB_ISi 1;
BA_ "SystemSignalLongSymbol" SG_ 944 LoadDistributionRequested_UB_ISi "LoadDistributionRequested_UB_ISig_6";
BA_ "GenSigSendType" SG_ 944 PBReleaseInhibit_rqst_UB 7;
BA_ "Platform_VMCU1_Sig" SG_ 944 PBReleaseInhibit_rqst_UB 1;
BA_ "GenSigSendType" SG_ 944 TachographOutputShaftSpeed_UB_IS 7;
BA_ "Platform_VMCU1_Sig" SG_ 944 TachographOutputShaftSpeed_UB_IS 1;
BA_ "SystemSignalLongSymbol" SG_ 944 TachographOutputShaftSpeed_UB_IS "TachographOutputShaftSpeed_UB_ISig_6";
BA_ "GenSigCycleTime" SG_ 944 PBReleaseInhibit_rqst 100;
BA_ "GenSigCycleTimeActive" SG_ 944 PBReleaseInhibit_rqst 100;
BA_ "GenSigStartValue" SG_ 944 PBReleaseInhibit_rqst 3;
BA_ "NeedsUpdateBit" SG_ 944 PBReleaseInhibit_rqst 1;
BA_ "Platform_VMCU1_Sig" SG_ 944 PBReleaseInhibit_rqst 1;
BA_ "GenSigCycleTime" SG_ 944 TachographVehicleSpeed_ISig_6 100;
BA_ "GenSigCycleTimeActive" SG_ 944 TachographVehicleSpeed_ISig_6 100;
BA_ "GenSigStartValue" SG_ 944 TachographVehicleSpeed_ISig_6 65535;
BA_ "GenSigMaxLatency" SG_ 944 TachographVehicleSpeed_ISig_6 52;
BA_ "NeedsUpdateBit" SG_ 944 TachographVehicleSpeed_ISig_6 1;
BA_ "Platform_VMCU1_Sig" SG_ 944 TachographVehicleSpeed_ISig_6 1;
BA_ "SeToolAncestorID_SIGNAL" SG_ 944 TachographVehicleSpeed_ISig_6 "x0000001D0414CAF5";
BA_ "SeToolItemID_SIGNAL" SG_ 944 TachographVehicleSpeed_ISig_6 "x0000001D0414CAF5";
BA_ "SeToolName_SIGNAL" SG_ 944 TachographVehicleSpeed_ISig_6 "TachographVehicleSpeed";
BA_ "SeToolVersion_SIGNAL" SG_ 944 TachographVehicleSpeed_ISig_6 "1";
BA_ "GenSigCycleTime" SG_ 944 TachographOutputShaftSpeed_ISig_ 100;
BA_ "GenSigCycleTimeActive" SG_ 944 TachographOutputShaftSpeed_ISig_ 100;
BA_ "GenSigStartValue" SG_ 944 TachographOutputShaftSpeed_ISig_ 65535;
BA_ "GenSigMaxLatency" SG_ 944 TachographOutputShaftSpeed_ISig_ 52;
BA_ "NeedsUpdateBit" SG_ 944 TachographOutputShaftSpeed_ISig_ 1;
BA_ "Platform_VMCU1_Sig" SG_ 944 TachographOutputShaftSpeed_ISig_ 1;
BA_ "SeToolAncestorID_SIGNAL" SG_ 944 TachographOutputShaftSpeed_ISig_ "x0000001D041285E8";
BA_ "SeToolItemID_SIGNAL" SG_ 944 TachographOutputShaftSpeed_ISig_ "x0000001D041285E8";
BA_ "SeToolName_SIGNAL" SG_ 944 TachographOutputShaftSpeed_ISig_ "TachographOutputShaftSpeed";
BA_ "SeToolVersion_SIGNAL" SG_ 944 TachographOutputShaftSpeed_ISig_ "1";
BA_ "SystemSignalLongSymbol" SG_ 944 TachographOutputShaftSpeed_ISig_ "TachographOutputShaftSpeed_ISig_6";
BA_ "GenSigCycleTime" SG_ 944 XPRRequest_CM_ISig_6 100;
BA_ "GenSigCycleTimeActive" SG_ 944 XPRRequest_CM_ISig_6 100;
BA_ "GenSigStartValue" SG_ 944 XPRRequest_CM_ISig_6 255;
BA_ "Platform_VMCU1_Sig" SG_ 944 XPRRequest_CM_ISig_6 1;
BA_ "GenSigCycleTime" SG_ 944 SWEngineStop_rqst_ISig_6 100;
BA_ "GenSigCycleTimeActive" SG_ 944 SWEngineStop_rqst_ISig_6 100;
BA_ "GenSigStartValue" SG_ 944 SWEngineStop_rqst_ISig_6 7;
BA_ "Platform_VMCU1_Sig" SG_ 944 SWEngineStop_rqst_ISig_6 1;
BA_ "GenSigSendType" SG_ 390 FrontAxleLeftWheelSpeed_UB_ISig_ 7;
BA_ "Platform_VMCU1_Sig" SG_ 390 FrontAxleLeftWheelSpeed_UB_ISig_ 1;
BA_ "SystemSignalLongSymbol" SG_ 390 FrontAxleLeftWheelSpeed_UB_ISig_ "FrontAxleLeftWheelSpeed_UB_ISig_6";
BA_ "GenSigCycleTime" SG_ 390 FrontAxleRightWheelSpeed_ISig_6 100;
BA_ "GenSigCycleTimeActive" SG_ 390 FrontAxleRightWheelSpeed_ISig_6 100;
BA_ "GenSigStartValue" SG_ 390 FrontAxleRightWheelSpeed_ISig_6 65535;
BA_ "NeedsUpdateBit" SG_ 390 FrontAxleRightWheelSpeed_ISig_6 1;
BA_ "Platform_VMCU1_Sig" SG_ 390 FrontAxleRightWheelSpeed_ISig_6 1;
BA_ "SeToolAncestorID_SIGNAL" SG_ 390 FrontAxleRightWheelSpeed_ISig_6 "x0000001D0410DA6F";
BA_ "SeToolItemID_SIGNAL" SG_ 390 FrontAxleRightWheelSpeed_ISig_6 "x0000001D0410DA6F";
BA_ "SeToolName_SIGNAL" SG_ 390 FrontAxleRightWheelSpeed_ISig_6 "FrontAxleRightWheelSpeed";
BA_ "SeToolVersion_SIGNAL" SG_ 390 FrontAxleRightWheelSpeed_ISig_6 "1";
BA_ "GenSigSendType" SG_ 390 FrontAxleRightWheelSpeed_UB_ISig 7;
BA_ "Platform_VMCU1_Sig" SG_ 390 FrontAxleRightWheelSpeed_UB_ISig 1;
BA_ "SystemSignalLongSymbol" SG_ 390 FrontAxleRightWheelSpeed_UB_ISig "FrontAxleRightWheelSpeed_UB_ISig_6";
BA_ "GenSigSendType" SG_ 390 LevelRequest_sg_UB_ISig_6 7;
BA_ "Platform_VMCU1_Sig" SG_ 390 LevelRequest_sg_UB_ISig_6 1;
BA_ "GenSigSendType" SG_ 390 AuxiliaryHorn_cmd_UB_ISig_6 7;
BA_ "Platform_VMCU1_Sig" SG_ 390 AuxiliaryHorn_cmd_UB_ISig_6 1;
BA_ "GenSigCycleTime" SG_ 390 CityHorn_cmd_ISig_6 100;
BA_ "GenSigCycleTimeActive" SG_ 390 CityHorn_cmd_ISig_6 100;
BA_ "GenSigStartValue" SG_ 390 CityHorn_cmd_ISig_6 3;
BA_ "GenSigMaxLatency" SG_ 390 CityHorn_cmd_ISig_6 23;
BA_ "NeedsUpdateBit" SG_ 390 CityHorn_cmd_ISig_6 1;
BA_ "Platform_VMCU1_Sig" SG_ 390 CityHorn_cmd_ISig_6 1;
BA_ "SeToolAncestorID_SIGNAL" SG_ 390 CityHorn_cmd_ISig_6 "x0000001D040FCB08";
BA_ "SeToolItemID_SIGNAL" SG_ 390 CityHorn_cmd_ISig_6 "x0000001D042E3A55";
BA_ "SeToolName_SIGNAL" SG_ 390 CityHorn_cmd_ISig_6 "CityHorn_cmd";
BA_ "SeToolVersion_SIGNAL" SG_ 390 CityHorn_cmd_ISig_6 "2";
BA_ "GenSigSendType" SG_ 390 CityHorn_cmd_UB_ISig_6 7;
BA_ "Platform_VMCU1_Sig" SG_ 390 CityHorn_cmd_UB_ISig_6 1;
BA_ "GenSigCycleTime" SG_ 390 LevelRequest_RollRequest_ISig_6 100;
BA_ "GenSigCycleTimeActive" SG_ 390 LevelRequest_RollRequest_ISig_6 100;
BA_ "GenSigStartValue" SG_ 390 LevelRequest_RollRequest_ISig_6 7;
BA_ "NeedsUpdateBit" SG_ 390 LevelRequest_RollRequest_ISig_6 1;
BA_ "Platform_VMCU1_Sig" SG_ 390 LevelRequest_RollRequest_ISig_6 1;
BA_ "GenSigCycleTime" SG_ 390 FrontAxleLeftWheelSpeed_ISig_6 100;
BA_ "GenSigCycleTimeActive" SG_ 390 FrontAxleLeftWheelSpeed_ISig_6 100;
BA_ "GenSigStartValue" SG_ 390 FrontAxleLeftWheelSpeed_ISig_6 65535;
BA_ "NeedsUpdateBit" SG_ 390 FrontAxleLeftWheelSpeed_ISig_6 1;
BA_ "Platform_VMCU1_Sig" SG_ 390 FrontAxleLeftWheelSpeed_ISig_6 1;
BA_ "SeToolAncestorID_SIGNAL" SG_ 390 FrontAxleLeftWheelSpeed_ISig_6 "x0000001D0410DA66";
BA_ "SeToolItemID_SIGNAL" SG_ 390 FrontAxleLeftWheelSpeed_ISig_6 "x0000001D0410DA66";
BA_ "SeToolName_SIGNAL" SG_ 390 FrontAxleLeftWheelSpeed_ISig_6 "FrontAxleLeftWheelSpeed";
BA_ "SeToolVersion_SIGNAL" SG_ 390 FrontAxleLeftWheelSpeed_ISig_6 "1";
BA_ "GenSigCycleTime" SG_ 390 ClutchSwitch_ISig_6 100;
BA_ "GenSigCycleTimeActive" SG_ 390 ClutchSwitch_ISig_6 100;
BA_ "GenSigStartValue" SG_ 390 ClutchSwitch_ISig_6 3;
BA_ "GenSigMaxLatency" SG_ 390 ClutchSwitch_ISig_6 23;
BA_ "Platform_VMCU1_Sig" SG_ 390 ClutchSwitch_ISig_6 1;
BA_ "SeToolAncestorID_SIGNAL" SG_ 390 ClutchSwitch_ISig_6 "x0000001D0410BACB";
BA_ "SeToolItemID_SIGNAL" SG_ 390 ClutchSwitch_ISig_6 "x0000001D0410BACB";
BA_ "SeToolName_SIGNAL" SG_ 390 ClutchSwitch_ISig_6 "ClutchSwitch";
BA_ "SeToolVersion_SIGNAL" SG_ 390 ClutchSwitch_ISig_6 "1";
BA_ "GenSigCycleTime" SG_ 390 AuxiliaryHorn_cmd_ISig_6 100;
BA_ "GenSigCycleTimeActive" SG_ 390 AuxiliaryHorn_cmd_ISig_6 100;
BA_ "GenSigStartValue" SG_ 390 AuxiliaryHorn_cmd_ISig_6 3;
BA_ "GenSigMaxLatency" SG_ 390 AuxiliaryHorn_cmd_ISig_6 23;
BA_ "NeedsUpdateBit" SG_ 390 AuxiliaryHorn_cmd_ISig_6 1;
BA_ "Platform_VMCU1_Sig" SG_ 390 AuxiliaryHorn_cmd_ISig_6 1;
BA_ "SeToolAncestorID_SIGNAL" SG_ 390 AuxiliaryHorn_cmd_ISig_6 "x0000001D040FCAFD";
BA_ "SeToolItemID_SIGNAL" SG_ 390 AuxiliaryHorn_cmd_ISig_6 "x0000001D042E3A36";
BA_ "SeToolName_SIGNAL" SG_ 390 AuxiliaryHorn_cmd_ISig_6 "AuxiliaryHorn_cmd";
BA_ "SeToolVersion_SIGNAL" SG_ 390 AuxiliaryHorn_cmd_ISig_6 "2";
BA_ "GenSigCycleTime" SG_ 390 LevelRequest_RearAxle_ISig_6 100;
BA_ "GenSigCycleTimeActive" SG_ 390 LevelRequest_RearAxle_ISig_6 100;
BA_ "GenSigStartValue" SG_ 390 LevelRequest_RearAxle_ISig_6 7;
BA_ "NeedsUpdateBit" SG_ 390 LevelRequest_RearAxle_ISig_6 1;
BA_ "Platform_VMCU1_Sig" SG_ 390 LevelRequest_RearAxle_ISig_6 1;
BA_ "GenSigCycleTime" SG_ 390 BrakeSwitch_ISig_6 100;
BA_ "GenSigCycleTimeActive" SG_ 390 BrakeSwitch_ISig_6 100;
BA_ "GenSigStartValue" SG_ 390 BrakeSwitch_ISig_6 3;
BA_ "GenSigMaxLatency" SG_ 390 BrakeSwitch_ISig_6 23;
BA_ "Platform_VMCU1_Sig" SG_ 390 BrakeSwitch_ISig_6 1;
BA_ "SeToolAncestorID_SIGNAL" SG_ 390 BrakeSwitch_ISig_6 "x0000001D0410DBED";
BA_ "SeToolItemID_SIGNAL" SG_ 390 BrakeSwitch_ISig_6 "x0000001D0410DBED";
BA_ "SeToolName_SIGNAL" SG_ 390 BrakeSwitch_ISig_6 "BrakeSwitch";
BA_ "SeToolVersion_SIGNAL" SG_ 390 BrakeSwitch_ISig_6 "1";
BA_ "GenSigCycleTime" SG_ 390 FPBRChangeReq_ISig_6 100;
BA_ "GenSigCycleTimeActive" SG_ 390 FPBRChangeReq_ISig_6 100;
BA_ "GenSigStartValue" SG_ 390 FPBRChangeReq_ISig_6 3;
BA_ "Platform_VMCU1_Sig" SG_ 390 FPBRChangeReq_ISig_6 1;
BA_ "GenSigCycleTime" SG_ 390 LevelRequest_FrontAxle_ISig_6 100;
BA_ "GenSigCycleTimeActive" SG_ 390 LevelRequest_FrontAxle_ISig_6 100;
BA_ "GenSigStartValue" SG_ 390 LevelRequest_FrontAxle_ISig_6 7;
BA_ "NeedsUpdateBit" SG_ 390 LevelRequest_FrontAxle_ISig_6 1;
BA_ "Platform_VMCU1_Sig" SG_ 390 LevelRequest_FrontAxle_ISig_6 1;
BA_ "GenSigCycleTime" SG_ 389 FrontWheelDriveRequest 100;
BA_ "GenSigCycleTimeActive" SG_ 389 FrontWheelDriveRequest 100;
BA_ "GenSigStartValue" SG_ 389 FrontWheelDriveRequest 3;
BA_ "Platform_VMCU1_Sig" SG_ 389 FrontWheelDriveRequest 1;
BA_ "GenSigSendType" SG_ 389 RearAxleLeftWheelSpeed_UB_ISig_6 7;
BA_ "Platform_VMCU1_Sig" SG_ 389 RearAxleLeftWheelSpeed_UB_ISig_6 1;
BA_ "GenSigCycleTime" SG_ 389 RearAxleLeftWheelSpeed_ISig_6 100;
BA_ "GenSigCycleTimeActive" SG_ 389 RearAxleLeftWheelSpeed_ISig_6 100;
BA_ "GenSigStartValue" SG_ 389 RearAxleLeftWheelSpeed_ISig_6 65535;
BA_ "GenSigMaxLatency" SG_ 389 RearAxleLeftWheelSpeed_ISig_6 51;
BA_ "NeedsUpdateBit" SG_ 389 RearAxleLeftWheelSpeed_ISig_6 1;
BA_ "Platform_VMCU1_Sig" SG_ 389 RearAxleLeftWheelSpeed_ISig_6 1;
BA_ "SeToolAncestorID_SIGNAL" SG_ 389 RearAxleLeftWheelSpeed_ISig_6 "x0000001D0410DA87";
BA_ "SeToolItemID_SIGNAL" SG_ 389 RearAxleLeftWheelSpeed_ISig_6 "x0000001D0410DA87";
BA_ "SeToolName_SIGNAL" SG_ 389 RearAxleLeftWheelSpeed_ISig_6 "RearAxleLeftWheelSpeed";
BA_ "SeToolVersion_SIGNAL" SG_ 389 RearAxleLeftWheelSpeed_ISig_6 "1";
BA_ "GenSigCycleTime" SG_ 389 RearAxleRightWheelSpeed_ISig_6 100;
BA_ "GenSigCycleTimeActive" SG_ 389 RearAxleRightWheelSpeed_ISig_6 100;
BA_ "GenSigStartValue" SG_ 389 RearAxleRightWheelSpeed_ISig_6 65535;
BA_ "GenSigMaxLatency" SG_ 389 RearAxleRightWheelSpeed_ISig_6 51;
BA_ "NeedsUpdateBit" SG_ 389 RearAxleRightWheelSpeed_ISig_6 1;
BA_ "Platform_VMCU1_Sig" SG_ 389 RearAxleRightWheelSpeed_ISig_6 1;
BA_ "SeToolAncestorID_SIGNAL" SG_ 389 RearAxleRightWheelSpeed_ISig_6 "x0000001D0410DA80";
BA_ "SeToolItemID_SIGNAL" SG_ 389 RearAxleRightWheelSpeed_ISig_6 "x0000001D0410DA80";
BA_ "SeToolName_SIGNAL" SG_ 389 RearAxleRightWheelSpeed_ISig_6 "RearAxleRightWheelSpeed";
BA_ "SeToolVersion_SIGNAL" SG_ 389 RearAxleRightWheelSpeed_ISig_6 "1";
BA_ "GenSigSendType" SG_ 389 RearAxleRightWheelSpeed_UB_ISig_ 7;
BA_ "Platform_VMCU1_Sig" SG_ 389 RearAxleRightWheelSpeed_UB_ISig_ 1;
BA_ "SystemSignalLongSymbol" SG_ 389 RearAxleRightWheelSpeed_UB_ISig_ "RearAxleRightWheelSpeed_UB_ISig_6";
BA_ "GenSigCycleTime" SG_ 389 KneelingChangeRequest_ISig_6 100;
BA_ "GenSigCycleTimeActive" SG_ 389 KneelingChangeRequest_ISig_6 100;
BA_ "GenSigStartValue" SG_ 389 KneelingChangeRequest_ISig_6 3;
BA_ "Platform_VMCU1_Sig" SG_ 389 KneelingChangeRequest_ISig_6 1;
BA_ "GenSigCycleTime" SG_ 1364 ExhManif_EMAIAirTankPres_ISig_6 100;
BA_ "GenSigCycleTimeActive" SG_ 1364 ExhManif_EMAIAirTankPres_ISig_6 100;
BA_ "GenSigStartValue" SG_ 1364 ExhManif_EMAIAirTankPres_ISig_6 255;
BA_ "GenSigCycleTime" SG_ 1364 DayUTC_ISig_6 100;
BA_ "GenSigCycleTimeActive" SG_ 1364 DayUTC_ISig_6 100;
BA_ "GenSigStartValue" SG_ 1364 DayUTC_ISig_6 255;
BA_ "Platform_VMCU1_Sig" SG_ 1364 DayUTC_ISig_6 1;
BA_ "SeToolAncestorID_SIGNAL" SG_ 1364 DayUTC_ISig_6 "x0000001D0412FAC4";
BA_ "SeToolItemID_SIGNAL" SG_ 1364 DayUTC_ISig_6 "x0000001D041EBD81";
BA_ "SeToolName_SIGNAL" SG_ 1364 DayUTC_ISig_6 "DayUTC";
BA_ "SeToolVersion_SIGNAL" SG_ 1364 DayUTC_ISig_6 "2";
BA_ "GenSigCycleTime" SG_ 1364 HoursUTC_ISig_6 100;
BA_ "GenSigCycleTimeActive" SG_ 1364 HoursUTC_ISig_6 100;
BA_ "GenSigStartValue" SG_ 1364 HoursUTC_ISig_6 255;
BA_ "Platform_VMCU1_Sig" SG_ 1364 HoursUTC_ISig_6 1;
BA_ "SeToolAncestorID_SIGNAL" SG_ 1364 HoursUTC_ISig_6 "x0000001D0412FAC2";
BA_ "SeToolItemID_SIGNAL" SG_ 1364 HoursUTC_ISig_6 "x0000001D041EBD20";
BA_ "SeToolName_SIGNAL" SG_ 1364 HoursUTC_ISig_6 "HoursUTC";
BA_ "SeToolVersion_SIGNAL" SG_ 1364 HoursUTC_ISig_6 "2";
BA_ "GenSigCycleTime" SG_ 1364 SecondsUTC_ISig_6 100;
BA_ "GenSigCycleTimeActive" SG_ 1364 SecondsUTC_ISig_6 100;
BA_ "GenSigStartValue" SG_ 1364 SecondsUTC_ISig_6 255;
BA_ "Platform_VMCU1_Sig" SG_ 1364 SecondsUTC_ISig_6 1;
BA_ "SeToolAncestorID_SIGNAL" SG_ 1364 SecondsUTC_ISig_6 "x0000001D0412FABE";
BA_ "SeToolItemID_SIGNAL" SG_ 1364 SecondsUTC_ISig_6 "x0000001D041EBD32";
BA_ "SeToolName_SIGNAL" SG_ 1364 SecondsUTC_ISig_6 "SecondsUTC";
BA_ "SeToolVersion_SIGNAL" SG_ 1364 SecondsUTC_ISig_6 "2";
BA_ "GenSigCycleTime" SG_ 1364 YearUTC_ISig_6 100;
BA_ "GenSigCycleTimeActive" SG_ 1364 YearUTC_ISig_6 100;
BA_ "GenSigStartValue" SG_ 1364 YearUTC_ISig_6 255;
BA_ "Platform_VMCU1_Sig" SG_ 1364 YearUTC_ISig_6 1;
BA_ "SeToolAncestorID_SIGNAL" SG_ 1364 YearUTC_ISig_6 "x0000001D0412FACB";
BA_ "SeToolItemID_SIGNAL" SG_ 1364 YearUTC_ISig_6 "x0000001D041EBCEF";
BA_ "SeToolName_SIGNAL" SG_ 1364 YearUTC_ISig_6 "YearUTC";
BA_ "SeToolVersion_SIGNAL" SG_ 1364 YearUTC_ISig_6 "2";
BA_ "GenSigCycleTime" SG_ 1364 MinutesUTC_ISig_6 100;
BA_ "GenSigCycleTimeActive" SG_ 1364 MinutesUTC_ISig_6 100;
BA_ "GenSigStartValue" SG_ 1364 MinutesUTC_ISig_6 255;
BA_ "Platform_VMCU1_Sig" SG_ 1364 MinutesUTC_ISig_6 1;
BA_ "SeToolAncestorID_SIGNAL" SG_ 1364 MinutesUTC_ISig_6 "x0000001D0412FAC0";
BA_ "SeToolItemID_SIGNAL" SG_ 1364 MinutesUTC_ISig_6 "x0000001D041EBD29";
BA_ "SeToolName_SIGNAL" SG_ 1364 MinutesUTC_ISig_6 "MinutesUTC";
BA_ "SeToolVersion_SIGNAL" SG_ 1364 MinutesUTC_ISig_6 "2";
BA_ "GenSigCycleTime" SG_ 1364 RoadInclination_ISig_6 100;
BA_ "GenSigCycleTimeActive" SG_ 1364 RoadInclination_ISig_6 100;
BA_ "GenSigStartValue" SG_ 1364 RoadInclination_ISig_6 255;
BA_ "Platform_VMCU1_Sig" SG_ 1364 RoadInclination_ISig_6 1;
BA_ "SeToolAncestorID_SIGNAL" SG_ 1364 RoadInclination_ISig_6 "x0000001D043FA322";
BA_ "SeToolItemID_SIGNAL" SG_ 1364 RoadInclination_ISig_6 "x0000001D043FA322";
BA_ "SeToolName_SIGNAL" SG_ 1364 RoadInclination_ISig_6 "RoadInclination";
BA_ "SeToolVersion_SIGNAL" SG_ 1364 RoadInclination_ISig_6 "1";
BA_ "GenSigCycleTime" SG_ 1364 MonthUTC_ISig_6 100;
BA_ "GenSigCycleTimeActive" SG_ 1364 MonthUTC_ISig_6 100;
BA_ "GenSigStartValue" SG_ 1364 MonthUTC_ISig_6 255;
BA_ "Platform_VMCU1_Sig" SG_ 1364 MonthUTC_ISig_6 1;
BA_ "SeToolAncestorID_SIGNAL" SG_ 1364 MonthUTC_ISig_6 "x0000001D0412FAC9";
BA_ "SeToolItemID_SIGNAL" SG_ 1364 MonthUTC_ISig_6 "x0000001D041EBD16";
BA_ "SeToolName_SIGNAL" SG_ 1364 MonthUTC_ISig_6 "MonthUTC";
BA_ "SeToolVersion_SIGNAL" SG_ 1364 MonthUTC_ISig_6 "2";
BA_ "GenSigCycleTime" SG_ 826 LampCheck_rqst_ISig_6 100;
BA_ "GenSigCycleTimeActive" SG_ 826 LampCheck_rqst_ISig_6 100;
BA_ "GenSigStartValue" SG_ 826 LampCheck_rqst_ISig_6 3;
BA_ "Platform_VMCU1_Sig" SG_ 826 LampCheck_rqst_ISig_6 1;
BA_ "GenSigCycleTime" SG_ 826 PercentClutchSlip_ISig_6 100;
BA_ "GenSigCycleTimeActive" SG_ 826 PercentClutchSlip_ISig_6 100;
BA_ "GenSigStartValue" SG_ 826 PercentClutchSlip_ISig_6 255;
BA_ "GenSigMaxLatency" SG_ 826 PercentClutchSlip_ISig_6 35;
BA_ "Platform_VMCU1_Sig" SG_ 826 PercentClutchSlip_ISig_6 1;
BA_ "SeToolAncestorID_SIGNAL" SG_ 826 PercentClutchSlip_ISig_6 "x0000001D04174A3C";
BA_ "SeToolItemID_SIGNAL" SG_ 826 PercentClutchSlip_ISig_6 "x0000001D04174A3C";
BA_ "SeToolName_SIGNAL" SG_ 826 PercentClutchSlip_ISig_6 "PercentClutchSlip";
BA_ "SeToolVersion_SIGNAL" SG_ 826 PercentClutchSlip_ISig_6 "1";
BA_ "GenSigCycleTime" SG_ 826 ChassisInstepLight_cmd 100;
BA_ "GenSigCycleTimeActive" SG_ 826 ChassisInstepLight_cmd 100;
BA_ "GenSigStartValue" SG_ 826 ChassisInstepLight_cmd 3;
BA_ "GenSigMaxLatency" SG_ 826 ChassisInstepLight_cmd 35;
BA_ "Platform_VMCU1_Sig" SG_ 826 ChassisInstepLight_cmd 1;
BA_ "GenSigSendType" SG_ 826 LiftAxle1DirectControl_UB_ISig_6 7;
BA_ "Platform_VMCU1_Sig" SG_ 826 LiftAxle1DirectControl_UB_ISig_6 1;
BA_ "GenSigCycleTime" SG_ 826 RangeInhibit 100;
BA_ "GenSigCycleTimeActive" SG_ 826 RangeInhibit 100;
BA_ "GenSigStartValue" SG_ 826 RangeInhibit 3;
BA_ "GenSigMaxLatency" SG_ 826 RangeInhibit 35;
BA_ "Platform_VMCU1_Sig" SG_ 826 RangeInhibit 1;
BA_ "GenSigCycleTime" SG_ 826 ActualDrvlnRetdrPercentTorque_IS 100;
BA_ "GenSigCycleTimeActive" SG_ 826 ActualDrvlnRetdrPercentTorque_IS 100;
BA_ "GenSigStartValue" SG_ 826 ActualDrvlnRetdrPercentTorque_IS 255;
BA_ "GenSigMaxLatency" SG_ 826 ActualDrvlnRetdrPercentTorque_IS 35;
BA_ "Platform_VMCU1_Sig" SG_ 826 ActualDrvlnRetdrPercentTorque_IS 1;
BA_ "SeToolAncestorID_SIGNAL" SG_ 826 ActualDrvlnRetdrPercentTorque_IS "x0000001D0410CFDE";
BA_ "SeToolItemID_SIGNAL" SG_ 826 ActualDrvlnRetdrPercentTorque_IS "x0000001D0410CFDE";
BA_ "SeToolName_SIGNAL" SG_ 826 ActualDrvlnRetdrPercentTorque_IS "ActualDrivelineRetarderPercentTorque";
BA_ "SeToolVersion_SIGNAL" SG_ 826 ActualDrvlnRetdrPercentTorque_IS "1";
BA_ "SystemSignalLongSymbol" SG_ 826 ActualDrvlnRetdrPercentTorque_IS "ActualDrvlnRetdrPercentTorque_ISig_6";
BA_ "GenSigCycleTime" SG_ 826 LiftAxle1DirectControl_ISig_6 100;
BA_ "GenSigCycleTimeActive" SG_ 826 LiftAxle1DirectControl_ISig_6 100;
BA_ "GenSigStartValue" SG_ 826 LiftAxle1DirectControl_ISig_6 7;
BA_ "NeedsUpdateBit" SG_ 826 LiftAxle1DirectControl_ISig_6 1;
BA_ "Platform_VMCU1_Sig" SG_ 826 LiftAxle1DirectControl_ISig_6 1;
BA_ "GenSigCycleTime" SG_ 826 TrailerBrakeNoEbs_stat 100;
BA_ "GenSigCycleTimeActive" SG_ 826 TrailerBrakeNoEbs_stat 100;
BA_ "GenSigStartValue" SG_ 826 TrailerBrakeNoEbs_stat 3;
BA_ "GenSigMaxLatency" SG_ 826 TrailerBrakeNoEbs_stat 35;
BA_ "Platform_VMCU1_Sig" SG_ 826 TrailerBrakeNoEbs_stat 1;
BA_ "GenSigCycleTime" SG_ 826 LEDAnimation_cmd 100;
BA_ "GenSigCycleTimeActive" SG_ 826 LEDAnimation_cmd 100;
BA_ "GenSigInactiveValue" SG_ 826 LEDAnimation_cmd 7;
BA_ "GenSigStartValue" SG_ 826 LEDAnimation_cmd 7;
BA_ "Platform_VMCU1_Sig" SG_ 826 LEDAnimation_cmd 1;
BA_ "GenSigCycleTime" SG_ 826 DoorsAjar_stat_ISig_6 100;
BA_ "GenSigCycleTimeActive" SG_ 826 DoorsAjar_stat_ISig_6 100;
BA_ "GenSigInactiveValue" SG_ 826 DoorsAjar_stat_ISig_6 7;
BA_ "GenSigStartValue" SG_ 826 DoorsAjar_stat_ISig_6 7;
BA_ "NeedsUpdateBit" SG_ 826 DoorsAjar_stat_ISig_6 1;
BA_ "Platform_VMCU1_Sig" SG_ 826 DoorsAjar_stat_ISig_6 1;
BA_ "GenSigCycleTime" SG_ 826 BBSlidable5thWheelCmd 100;
BA_ "GenSigCycleTimeActive" SG_ 826 BBSlidable5thWheelCmd 100;
BA_ "GenSigStartValue" SG_ 826 BBSlidable5thWheelCmd 3;
BA_ "GenSigMaxLatency" SG_ 826 BBSlidable5thWheelCmd 35;
BA_ "Platform_VMCU1_Sig" SG_ 826 BBSlidable5thWheelCmd 1;
BA_ "GenSigCycleTime" SG_ 826 LampCheck_cmd_ISig_6 100;
BA_ "GenSigCycleTimeActive" SG_ 826 LampCheck_cmd_ISig_6 100;
BA_ "GenSigStartValue" SG_ 826 LampCheck_cmd_ISig_6 3;
BA_ "Platform_VMCU1_Sig" SG_ 826 LampCheck_cmd_ISig_6 1;
BA_ "GenSigCycleTime" SG_ 826 BlackOutandConvoyMode_rqst_ISig_ 100;
BA_ "GenSigCycleTimeActive" SG_ 826 BlackOutandConvoyMode_rqst_ISig_ 100;
BA_ "GenSigInactiveValue" SG_ 826 BlackOutandConvoyMode_rqst_ISig_ 7;
BA_ "GenSigStartValue" SG_ 826 BlackOutandConvoyMode_rqst_ISig_ 7;
BA_ "Platform_VMCU1_Sig" SG_ 826 BlackOutandConvoyMode_rqst_ISig_ 1;
BA_ "SystemSignalLongSymbol" SG_ 826 BlackOutandConvoyMode_rqst_ISig_ "BlackOutandConvoyMode_rqst_ISig_6";
BA_ "GenSigCycleTime" SG_ 826 AreaInhibit 100;
BA_ "GenSigCycleTimeActive" SG_ 826 AreaInhibit 100;
BA_ "GenSigStartValue" SG_ 826 AreaInhibit 3;
BA_ "GenSigMaxLatency" SG_ 826 AreaInhibit 35;
BA_ "Platform_VMCU1_Sig" SG_ 826 AreaInhibit 1;
BA_ "GenSigCycleTime" SG_ 826 MaintBatteryReset 100;
BA_ "GenSigCycleTimeActive" SG_ 826 MaintBatteryReset 100;
BA_ "GenSigStartValue" SG_ 826 MaintBatteryReset 3;
BA_ "GenSigMaxLatency" SG_ 826 MaintBatteryReset 35;
BA_ "Platform_VMCU1_Sig" SG_ 826 MaintBatteryReset 1;
BA_ "GenSigCycleTime" SG_ 826 ECSStandByRequest_ISig_6 100;
BA_ "GenSigCycleTimeActive" SG_ 826 ECSStandByRequest_ISig_6 100;
BA_ "GenSigInactiveValue" SG_ 826 ECSStandByRequest_ISig_6 7;
BA_ "GenSigStartValue" SG_ 826 ECSStandByRequest_ISig_6 7;
BA_ "Platform_VMCU1_Sig" SG_ 826 ECSStandByRequest_ISig_6 1;
BA_ "GenSigSendType" SG_ 826 DoorsAjar_stat_UB_ISig_6 7;
BA_ "Platform_VMCU1_Sig" SG_ 826 DoorsAjar_stat_UB_ISig_6 1;
BA_ "GenSigCycleTime" SG_ 826 PloughLampModeStatus_ISig_6 100;
BA_ "GenSigCycleTimeActive" SG_ 826 PloughLampModeStatus_ISig_6 100;
BA_ "GenSigStartValue" SG_ 826 PloughLampModeStatus_ISig_6 3;
BA_ "Platform_VMCU1_Sig" SG_ 826 PloughLampModeStatus_ISig_6 1;
BA_ "GenSigCycleTime" SG_ 826 VIN_rqst_ISig_6 100;
BA_ "GenSigCycleTimeActive" SG_ 826 VIN_rqst_ISig_6 100;
BA_ "GenSigMaxLatency" SG_ 826 VIN_rqst_ISig_6 35;
BA_ "Platform_VMCU1_Sig" SG_ 826 VIN_rqst_ISig_6 1;
BA_ "GenSigCycleTime" SG_ 826 BBContUnlockCmd 100;
BA_ "GenSigCycleTimeActive" SG_ 826 BBContUnlockCmd 100;
BA_ "GenSigStartValue" SG_ 826 BBContUnlockCmd 3;
BA_ "GenSigMaxLatency" SG_ 826 BBContUnlockCmd 35;
BA_ "Platform_VMCU1_Sig" SG_ 826 BBContUnlockCmd 1;
BA_ "GenSigCycleTime" SG_ 826 EngineActiveStatus_ISig_6 100;
BA_ "GenSigCycleTimeActive" SG_ 826 EngineActiveStatus_ISig_6 100;
BA_ "GenSigStartValue" SG_ 826 EngineActiveStatus_ISig_6 15;
BA_ "GenSigMaxLatency" SG_ 826 EngineActiveStatus_ISig_6 35;
BA_ "Platform_VMCU1_Sig" SG_ 826 EngineActiveStatus_ISig_6 1;
BA_ "SeToolAncestorID_SIGNAL" SG_ 826 EngineActiveStatus_ISig_6 "x0000001D0421DFD5";
BA_ "SeToolItemID_SIGNAL" SG_ 826 EngineActiveStatus_ISig_6 "x0000001D0421DFD5";
BA_ "SeToolName_SIGNAL" SG_ 826 EngineActiveStatus_ISig_6 "EngineActiveStatus";
BA_ "SeToolVersion_SIGNAL" SG_ 826 EngineActiveStatus_ISig_6 "1";
BA_ "GenSigCycleTime" SG_ 826 BatteryCapacity_ISig_6 100;
BA_ "GenSigCycleTimeActive" SG_ 826 BatteryCapacity_ISig_6 100;
BA_ "GenSigStartValue" SG_ 826 BatteryCapacity_ISig_6 15;
BA_ "Platform_VMCU1_Sig" SG_ 826 BatteryCapacity_ISig_6 1;
BA_ "GenSigCycleTime" SG_ 1369 PoweredVehicleWeight_ISig_6 100;
BA_ "GenSigCycleTimeActive" SG_ 1369 PoweredVehicleWeight_ISig_6 100;
BA_ "GenSigStartValue" SG_ 1369 PoweredVehicleWeight_ISig_6 65535;
BA_ "GenSigMaxLatency" SG_ 1369 PoweredVehicleWeight_ISig_6 511;
BA_ "Platform_VMCU1_Sig" SG_ 1369 PoweredVehicleWeight_ISig_6 1;
BA_ "SeToolAncestorID_SIGNAL" SG_ 1369 PoweredVehicleWeight_ISig_6 "x0000001D0412FC34";
BA_ "SeToolItemID_SIGNAL" SG_ 1369 PoweredVehicleWeight_ISig_6 "x0000001D0412FC34";
BA_ "SeToolName_SIGNAL" SG_ 1369 PoweredVehicleWeight_ISig_6 "PoweredVehicleWeight";
BA_ "SeToolVersion_SIGNAL" SG_ 1369 PoweredVehicleWeight_ISig_6 "1";
BA_ "GenSigCycleTime" SG_ 1369 TotalVehicleDistanceHighRes_ISig 100;
BA_ "GenSigCycleTimeActive" SG_ 1369 TotalVehicleDistanceHighRes_ISig 100;
BA_ "GenSigStartValue" SG_ 1369 TotalVehicleDistanceHighRes_ISig 4294967295;
BA_ "GenSigMaxLatency" SG_ 1369 TotalVehicleDistanceHighRes_ISig 511;
BA_ "Platform_VMCU1_Sig" SG_ 1369 TotalVehicleDistanceHighRes_ISig 1;
BA_ "SeToolAncestorID_SIGNAL" SG_ 1369 TotalVehicleDistanceHighRes_ISig "x0000001D04109E2B";
BA_ "SeToolItemID_SIGNAL" SG_ 1369 TotalVehicleDistanceHighRes_ISig "x0000001D04109E2B";
BA_ "SeToolName_SIGNAL" SG_ 1369 TotalVehicleDistanceHighRes_ISig "HighResolutionTotalVehicleDistance";
BA_ "SeToolVersion_SIGNAL" SG_ 1369 TotalVehicleDistanceHighRes_ISig "1";
BA_ "SystemSignalLongSymbol" SG_ 1369 TotalVehicleDistanceHighRes_ISig "TotalVehicleDistanceHighRes_ISig_6";
BA_ "GenSigCycleTime" SG_ 1369 GrossCombinationVehicleWeight_IS 100;
BA_ "GenSigCycleTimeActive" SG_ 1369 GrossCombinationVehicleWeight_IS 100;
BA_ "GenSigStartValue" SG_ 1369 GrossCombinationVehicleWeight_IS 65535;
BA_ "GenSigMaxLatency" SG_ 1369 GrossCombinationVehicleWeight_IS 511;
BA_ "Platform_VMCU1_Sig" SG_ 1369 GrossCombinationVehicleWeight_IS 1;
BA_ "SeToolAncestorID_SIGNAL" SG_ 1369 GrossCombinationVehicleWeight_IS "x0000001D0412FC36";
BA_ "SeToolItemID_SIGNAL" SG_ 1369 GrossCombinationVehicleWeight_IS "x0000001D0412FC36";
BA_ "SeToolName_SIGNAL" SG_ 1369 GrossCombinationVehicleWeight_IS "GrossCombinationVehicleWeight";
BA_ "SeToolVersion_SIGNAL" SG_ 1369 GrossCombinationVehicleWeight_IS "1";
BA_ "SystemSignalLongSymbol" SG_ 1369 GrossCombinationVehicleWeight_IS "GrossCombinationVehicleWeight_ISig_6";
BA_ "GenSigCycleTime" SG_ 946 TransferCaseOrSplitboxPTOMode_IS 100;
BA_ "GenSigCycleTimeActive" SG_ 946 TransferCaseOrSplitboxPTOMode_IS 100;
BA_ "GenSigStartValue" SG_ 946 TransferCaseOrSplitboxPTOMode_IS 3;
BA_ "GenSigMaxLatency" SG_ 946 TransferCaseOrSplitboxPTOMode_IS 55;
BA_ "Platform_VMCU1_Sig" SG_ 946 TransferCaseOrSplitboxPTOMode_IS 1;
BA_ "SeToolAncestorID_SIGNAL" SG_ 946 TransferCaseOrSplitboxPTOMode_IS "x0000001D0419DC89";
BA_ "SeToolItemID_SIGNAL" SG_ 946 TransferCaseOrSplitboxPTOMode_IS "x0000001D0419DC89";
BA_ "SeToolName_SIGNAL" SG_ 946 TransferCaseOrSplitboxPTOMode_IS "SplitBoxPtoStatus";
BA_ "SeToolVersion_SIGNAL" SG_ 946 TransferCaseOrSplitboxPTOMode_IS "1";
BA_ "SystemSignalLongSymbol" SG_ 946 TransferCaseOrSplitboxPTOMode_IS "TransferCaseOrSplitboxPTOMode_ISig_6";
BA_ "GenSigCycleTime" SG_ 946 EPBHillHolderMode_ISig_6 100;
BA_ "GenSigCycleTimeActive" SG_ 946 EPBHillHolderMode_ISig_6 100;
BA_ "GenSigStartValue" SG_ 946 EPBHillHolderMode_ISig_6 7;
BA_ "GenSigMaxLatency" SG_ 946 EPBHillHolderMode_ISig_6 55;
BA_ "Platform_VMCU1_Sig" SG_ 946 EPBHillHolderMode_ISig_6 1;
BA_ "SeToolAncestorID_SIGNAL" SG_ 946 EPBHillHolderMode_ISig_6 "x0000001D0410DBE4";
BA_ "SeToolItemID_SIGNAL" SG_ 946 EPBHillHolderMode_ISig_6 "x0000001D04295780";
BA_ "SeToolName_SIGNAL" SG_ 946 EPBHillHolderMode_ISig_6 "HillHolderMode";
BA_ "SeToolVersion_SIGNAL" SG_ 946 EPBHillHolderMode_ISig_6 "2";
BA_ "GenSigCycleTime" SG_ 946 VehicleDistanceRollingCounter 100;
BA_ "GenSigCycleTimeActive" SG_ 946 VehicleDistanceRollingCounter 100;
BA_ "GenSigStartValue" SG_ 946 VehicleDistanceRollingCounter 65535;
BA_ "Platform_VMCU1_Sig" SG_ 946 VehicleDistanceRollingCounter 1;
BA_ "GenSigSendType" SG_ 946 RrInterAxlDiffLockActvnDrvrReq_U 7;
BA_ "Platform_VMCU1_Sig" SG_ 946 RrInterAxlDiffLockActvnDrvrReq_U 1;
BA_ "SystemSignalLongSymbol" SG_ 946 RrInterAxlDiffLockActvnDrvrReq_U "RrInterAxlDiffLockActvnDrvrReq_UB_ISig_6";
BA_ "GenSigCycleTime" SG_ 946 Pto4Status_ISig_6 100;
BA_ "GenSigCycleTimeActive" SG_ 946 Pto4Status_ISig_6 100;
BA_ "GenSigStartValue" SG_ 946 Pto4Status_ISig_6 3;
BA_ "GenSigMaxLatency" SG_ 946 Pto4Status_ISig_6 55;
BA_ "Platform_VMCU1_Sig" SG_ 946 Pto4Status_ISig_6 1;
BA_ "SeToolAncestorID_SIGNAL" SG_ 946 Pto4Status_ISig_6 "x0000001D041534AC";
BA_ "SeToolItemID_SIGNAL" SG_ 946 Pto4Status_ISig_6 "x0000001D04321056";
BA_ "SeToolName_SIGNAL" SG_ 946 Pto4Status_ISig_6 "Pto4Status";
BA_ "SeToolVersion_SIGNAL" SG_ 946 Pto4Status_ISig_6 "3";
BA_ "GenSigCycleTime" SG_ 946 CartridgeChangedDrvrReset_rqst 100;
BA_ "GenSigCycleTimeActive" SG_ 946 CartridgeChangedDrvrReset_rqst 100;
BA_ "GenSigStartValue" SG_ 946 CartridgeChangedDrvrReset_rqst 3;
BA_ "GenSigMaxLatency" SG_ 946 CartridgeChangedDrvrReset_rqst 55;
BA_ "Platform_VMCU1_Sig" SG_ 946 CartridgeChangedDrvrReset_rqst 1;
BA_ "SeToolAncestorID_SIGNAL" SG_ 946 CartridgeChangedDrvrReset_rqst "x0000001D0414E3FB";
BA_ "SeToolItemID_SIGNAL" SG_ 946 CartridgeChangedDrvrReset_rqst "x0000001D04356DD7";
BA_ "SeToolName_SIGNAL" SG_ 946 CartridgeChangedDrvrReset_rqst "CartridgeChangedDriverReset_rqst";
BA_ "SeToolVersion_SIGNAL" SG_ 946 CartridgeChangedDrvrReset_rqst "2";
BA_ "GenSigCycleTime" SG_ 946 Pto2Status_ISig_6 100;
BA_ "GenSigCycleTimeActive" SG_ 946 Pto2Status_ISig_6 100;
BA_ "GenSigStartValue" SG_ 946 Pto2Status_ISig_6 3;
BA_ "GenSigMaxLatency" SG_ 946 Pto2Status_ISig_6 55;
BA_ "Platform_VMCU1_Sig" SG_ 946 Pto2Status_ISig_6 1;
BA_ "SeToolAncestorID_SIGNAL" SG_ 946 Pto2Status_ISig_6 "x0000001D041534A5";
BA_ "SeToolItemID_SIGNAL" SG_ 946 Pto2Status_ISig_6 "x0000001D04321002";
BA_ "SeToolName_SIGNAL" SG_ 946 Pto2Status_ISig_6 "Pto2Status";
BA_ "SeToolVersion_SIGNAL" SG_ 946 Pto2Status_ISig_6 "3";
BA_ "GenSigCycleTime" SG_ 946 AcceleratorPedalQuality_ISig_6 100;
BA_ "GenSigCycleTimeActive" SG_ 946 AcceleratorPedalQuality_ISig_6 100;
BA_ "GenSigStartValue" SG_ 946 AcceleratorPedalQuality_ISig_6 3;
BA_ "Platform_VMCU1_Sig" SG_ 946 AcceleratorPedalQuality_ISig_6 1;
BA_ "GenSigCycleTime" SG_ 946 Pto2DrivingRequest 100;
BA_ "GenSigCycleTimeActive" SG_ 946 Pto2DrivingRequest 100;
BA_ "GenSigStartValue" SG_ 946 Pto2DrivingRequest 3;
BA_ "GenSigMaxLatency" SG_ 946 Pto2DrivingRequest 55;
BA_ "Platform_VMCU1_Sig" SG_ 946 Pto2DrivingRequest 1;
BA_ "SeToolAncestorID_SIGNAL" SG_ 946 Pto2DrivingRequest "x0000001D041538FA";
BA_ "SeToolItemID_SIGNAL" SG_ 946 Pto2DrivingRequest "x0000001D041538FA";
BA_ "SeToolName_SIGNAL" SG_ 946 Pto2DrivingRequest "Pto2DrivingRequest";
BA_ "SeToolVersion_SIGNAL" SG_ 946 Pto2DrivingRequest "1";
BA_ "GenSigCycleTime" SG_ 946 Pto3Status_ISig_6 100;
BA_ "GenSigCycleTimeActive" SG_ 946 Pto3Status_ISig_6 100;
BA_ "GenSigStartValue" SG_ 946 Pto3Status_ISig_6 3;
BA_ "GenSigMaxLatency" SG_ 946 Pto3Status_ISig_6 55;
BA_ "Platform_VMCU1_Sig" SG_ 946 Pto3Status_ISig_6 1;
BA_ "SeToolAncestorID_SIGNAL" SG_ 946 Pto3Status_ISig_6 "x0000001D041534A7";
BA_ "SeToolItemID_SIGNAL" SG_ 946 Pto3Status_ISig_6 "x0000001D04321034";
BA_ "SeToolName_SIGNAL" SG_ 946 Pto3Status_ISig_6 "Pto3Status";
BA_ "SeToolVersion_SIGNAL" SG_ 946 Pto3Status_ISig_6 "3";
BA_ "GenSigCycleTime" SG_ 946 ReducedLoadMode_stat_ISig_6 100;
BA_ "GenSigCycleTimeActive" SG_ 946 ReducedLoadMode_stat_ISig_6 100;
BA_ "GenSigStartValue" SG_ 946 ReducedLoadMode_stat_ISig_6 3;
BA_ "Platform_VMCU1_Sig" SG_ 946 ReducedLoadMode_stat_ISig_6 1;
BA_ "GenSigSendType" SG_ 946 RearAxleDiffLockActvnDrvrReq_UB_ 7;
BA_ "Platform_VMCU1_Sig" SG_ 946 RearAxleDiffLockActvnDrvrReq_UB_ 1;
BA_ "SystemSignalLongSymbol" SG_ 946 RearAxleDiffLockActvnDrvrReq_UB_ "RearAxleDiffLockActvnDrvrReq_UB_ISig_6";
BA_ "GenSigCycleTime" SG_ 946 RearAxleDiffLockActvnDrvrReq_ISi 100;
BA_ "GenSigCycleTimeActive" SG_ 946 RearAxleDiffLockActvnDrvrReq_ISi 100;
BA_ "GenSigStartValue" SG_ 946 RearAxleDiffLockActvnDrvrReq_ISi 3;
BA_ "GenSigMaxLatency" SG_ 946 RearAxleDiffLockActvnDrvrReq_ISi 55;
BA_ "NeedsUpdateBit" SG_ 946 RearAxleDiffLockActvnDrvrReq_ISi 1;
BA_ "Platform_VMCU1_Sig" SG_ 946 RearAxleDiffLockActvnDrvrReq_ISi 1;
BA_ "SeToolAncestorID_SIGNAL" SG_ 946 RearAxleDiffLockActvnDrvrReq_ISi "x0000001D041287CE";
BA_ "SeToolItemID_SIGNAL" SG_ 946 RearAxleDiffLockActvnDrvrReq_ISi "x0000001D041287CE";
BA_ "SeToolName_SIGNAL" SG_ 946 RearAxleDiffLockActvnDrvrReq_ISi "RearAxleDiffLockActivationDriverRequest";
BA_ "SeToolVersion_SIGNAL" SG_ 946 RearAxleDiffLockActvnDrvrReq_ISi "1";
BA_ "SystemSignalLongSymbol" SG_ 946 RearAxleDiffLockActvnDrvrReq_ISi "RearAxleDiffLockActvnDrvrReq_ISig_6";
BA_ "GenSigCycleTime" SG_ 946 RrInterAxlDiffLockActvnFuncReq 100;
BA_ "GenSigCycleTimeActive" SG_ 946 RrInterAxlDiffLockActvnFuncReq 100;
BA_ "GenSigStartValue" SG_ 946 RrInterAxlDiffLockActvnFuncReq 3;
BA_ "GenSigCycleTime" SG_ 946 Pto1DrivingRequest 100;
BA_ "GenSigCycleTimeActive" SG_ 946 Pto1DrivingRequest 100;
BA_ "GenSigStartValue" SG_ 946 Pto1DrivingRequest 3;
BA_ "GenSigMaxLatency" SG_ 946 Pto1DrivingRequest 55;
BA_ "Platform_VMCU1_Sig" SG_ 946 Pto1DrivingRequest 1;
BA_ "SeToolAncestorID_SIGNAL" SG_ 946 Pto1DrivingRequest "x0000001D041538F8";
BA_ "SeToolItemID_SIGNAL" SG_ 946 Pto1DrivingRequest "x0000001D041538F8";
BA_ "SeToolName_SIGNAL" SG_ 946 Pto1DrivingRequest "Pto1DrivingRequest";
BA_ "SeToolVersion_SIGNAL" SG_ 946 Pto1DrivingRequest "1";
BA_ "GenSigCycleTime" SG_ 946 EngineStopRequest_ISig_6 100;
BA_ "GenSigCycleTimeActive" SG_ 946 EngineStopRequest_ISig_6 100;
BA_ "GenSigStartValue" SG_ 946 EngineStopRequest_ISig_6 3;
BA_ "Platform_VMCU1_Sig" SG_ 946 EngineStopRequest_ISig_6 1;
BA_ "SeToolAncestorID_SIGNAL" SG_ 946 EngineStopRequest_ISig_6 "x0000001D042883AC";
BA_ "SeToolItemID_SIGNAL" SG_ 946 EngineStopRequest_ISig_6 "x0000001D042883AC";
BA_ "SeToolName_SIGNAL" SG_ 946 EngineStopRequest_ISig_6 "EngineStopRequest";
BA_ "SeToolVersion_SIGNAL" SG_ 946 EngineStopRequest_ISig_6 "1";
BA_ "GenSigCycleTime" SG_ 946 AcceleratorPedalStatus_ISig_6 100;
BA_ "GenSigCycleTimeActive" SG_ 946 AcceleratorPedalStatus_ISig_6 100;
BA_ "GenSigStartValue" SG_ 946 AcceleratorPedalStatus_ISig_6 7;
BA_ "Platform_VMCU1_Sig" SG_ 946 AcceleratorPedalStatus_ISig_6 1;
BA_ "GenSigCycleTime" SG_ 946 XBRActiveControlMode_ISig_6 100;
BA_ "GenSigCycleTimeActive" SG_ 946 XBRActiveControlMode_ISig_6 100;
BA_ "GenSigStartValue" SG_ 946 XBRActiveControlMode_ISig_6 15;
BA_ "GenSigMaxLatency" SG_ 946 XBRActiveControlMode_ISig_6 55;
BA_ "Platform_VMCU1_Sig" SG_ 946 XBRActiveControlMode_ISig_6 1;
BA_ "SeToolAncestorID_SIGNAL" SG_ 946 XBRActiveControlMode_ISig_6 "x0000001D0415286A";
BA_ "SeToolItemID_SIGNAL" SG_ 946 XBRActiveControlMode_ISig_6 "x0000001D0415286A";
BA_ "SeToolName_SIGNAL" SG_ 946 XBRActiveControlMode_ISig_6 "XBRActiveControlMode";
BA_ "SeToolVersion_SIGNAL" SG_ 946 XBRActiveControlMode_ISig_6 "1";
BA_ "GenSigCycleTime" SG_ 946 RearAxleDiffLockActvnFuncReq_ISi 100;
BA_ "GenSigCycleTimeActive" SG_ 946 RearAxleDiffLockActvnFuncReq_ISi 100;
BA_ "GenSigStartValue" SG_ 946 RearAxleDiffLockActvnFuncReq_ISi 3;
BA_ "GenSigMaxLatency" SG_ 946 RearAxleDiffLockActvnFuncReq_ISi 55;
BA_ "NeedsUpdateBit" SG_ 946 RearAxleDiffLockActvnFuncReq_ISi 1;
BA_ "Platform_VMCU1_Sig" SG_ 946 RearAxleDiffLockActvnFuncReq_ISi 1;
BA_ "SeToolAncestorID_SIGNAL" SG_ 946 RearAxleDiffLockActvnFuncReq_ISi "x0000001D0412880F";
BA_ "SeToolItemID_SIGNAL" SG_ 946 RearAxleDiffLockActvnFuncReq_ISi "x0000001D0412880F";
BA_ "SeToolName_SIGNAL" SG_ 946 RearAxleDiffLockActvnFuncReq_ISi "RearAxleDiffLockActivationFunctionRequest";
BA_ "SeToolVersion_SIGNAL" SG_ 946 RearAxleDiffLockActvnFuncReq_ISi "1";
BA_ "SystemSignalLongSymbol" SG_ 946 RearAxleDiffLockActvnFuncReq_ISi "RearAxleDiffLockActvnFuncReq_ISig_6";
BA_ "GenSigCycleTime" SG_ 946 RrInterAxlDiffLockActvnDrvrReq_I 100;
BA_ "GenSigCycleTimeActive" SG_ 946 RrInterAxlDiffLockActvnDrvrReq_I 100;
BA_ "GenSigStartValue" SG_ 946 RrInterAxlDiffLockActvnDrvrReq_I 3;
BA_ "GenSigMaxLatency" SG_ 946 RrInterAxlDiffLockActvnDrvrReq_I 55;
BA_ "NeedsUpdateBit" SG_ 946 RrInterAxlDiffLockActvnDrvrReq_I 1;
BA_ "Platform_VMCU1_Sig" SG_ 946 RrInterAxlDiffLockActvnDrvrReq_I 1;
BA_ "SeToolAncestorID_SIGNAL" SG_ 946 RrInterAxlDiffLockActvnDrvrReq_I "x0000001D041287CC";
BA_ "SeToolItemID_SIGNAL" SG_ 946 RrInterAxlDiffLockActvnDrvrReq_I "x0000001D041287CC";
BA_ "SeToolName_SIGNAL" SG_ 946 RrInterAxlDiffLockActvnDrvrReq_I "RearInteraxleDiffLockActivationDriverRequest";
BA_ "SeToolVersion_SIGNAL" SG_ 946 RrInterAxlDiffLockActvnDrvrReq_I "1";
BA_ "SystemSignalLongSymbol" SG_ 946 RrInterAxlDiffLockActvnDrvrReq_I "RrInterAxlDiffLockActvnDrvrReq_ISig_6";
BA_ "GenSigCycleTime" SG_ 946 KeyPosition_ISig_6 100;
BA_ "GenSigCycleTimeActive" SG_ 946 KeyPosition_ISig_6 100;
BA_ "GenSigStartValue" SG_ 946 KeyPosition_ISig_6 7;
BA_ "Platform_VMCU1_Sig" SG_ 946 KeyPosition_ISig_6 1;
BA_ "SeToolAncestorID_SIGNAL" SG_ 946 KeyPosition_ISig_6 "x0000001D0410D5F7";
BA_ "SeToolItemID_SIGNAL" SG_ 946 KeyPosition_ISig_6 "x0000001D0410D5F7";
BA_ "SeToolName_SIGNAL" SG_ 946 KeyPosition_ISig_6 "KeyPosition";
BA_ "SeToolVersion_SIGNAL" SG_ 946 KeyPosition_ISig_6 "1";
BA_ "GenSigSendType" SG_ 946 RearAxleDiffLockActvnFuncReq_UB_ 7;
BA_ "Platform_VMCU1_Sig" SG_ 946 RearAxleDiffLockActvnFuncReq_UB_ 1;
BA_ "SystemSignalLongSymbol" SG_ 946 RearAxleDiffLockActvnFuncReq_UB_ "RearAxleDiffLockActvnFuncReq_UB_ISig_6";
BA_ "GenSigCycleTime" SG_ 946 Pto1Status_ISig_6 100;
BA_ "GenSigCycleTimeActive" SG_ 946 Pto1Status_ISig_6 100;
BA_ "GenSigStartValue" SG_ 946 Pto1Status_ISig_6 3;
BA_ "GenSigMaxLatency" SG_ 946 Pto1Status_ISig_6 55;
BA_ "Platform_VMCU1_Sig" SG_ 946 Pto1Status_ISig_6 1;
BA_ "SeToolAncestorID_SIGNAL" SG_ 946 Pto1Status_ISig_6 "x0000001D041534A3";
BA_ "SeToolItemID_SIGNAL" SG_ 946 Pto1Status_ISig_6 "x0000001D04320FF9";
BA_ "SeToolName_SIGNAL" SG_ 946 Pto1Status_ISig_6 "Pto1Status";
BA_ "SeToolVersion_SIGNAL" SG_ 946 Pto1Status_ISig_6 "3";
BA_ "GenSigCycleTime" SG_ 945 ActualEnginePercentTorque_ISig_6 100;
BA_ "GenSigCycleTimeActive" SG_ 945 ActualEnginePercentTorque_ISig_6 100;
BA_ "GenSigStartValue" SG_ 945 ActualEnginePercentTorque_ISig_6 255;
BA_ "GenSigMaxLatency" SG_ 945 ActualEnginePercentTorque_ISig_6 54;
BA_ "NeedsUpdateBit" SG_ 945 ActualEnginePercentTorque_ISig_6 1;
BA_ "Platform_VMCU1_Sig" SG_ 945 ActualEnginePercentTorque_ISig_6 1;
BA_ "SeToolAncestorID_SIGNAL" SG_ 945 ActualEnginePercentTorque_ISig_6 "x0000001D0410CDD5";
BA_ "SeToolItemID_SIGNAL" SG_ 945 ActualEnginePercentTorque_ISig_6 "x0000001D0410CDD5";
BA_ "SeToolName_SIGNAL" SG_ 945 ActualEnginePercentTorque_ISig_6 "ActualEngine-PercentTorque";
BA_ "SeToolVersion_SIGNAL" SG_ 945 ActualEnginePercentTorque_ISig_6 "1";
BA_ "GenSigCycleTime" SG_ 945 EcoRollActiveStatus_ISig_6 100;
BA_ "GenSigCycleTimeActive" SG_ 945 EcoRollActiveStatus_ISig_6 100;
BA_ "GenSigStartValue" SG_ 945 EcoRollActiveStatus_ISig_6 3;
BA_ "Platform_VMCU1_Sig" SG_ 945 EcoRollActiveStatus_ISig_6 1;
BA_ "SeToolAncestorID_SIGNAL" SG_ 945 EcoRollActiveStatus_ISig_6 "x0000001D043EEFC6";
BA_ "SeToolItemID_SIGNAL" SG_ 945 EcoRollActiveStatus_ISig_6 "x0000001D043EEFC6";
BA_ "SeToolName_SIGNAL" SG_ 945 EcoRollActiveStatus_ISig_6 "Eco-RollActiveStatus";
BA_ "SeToolVersion_SIGNAL" SG_ 945 EcoRollActiveStatus_ISig_6 "1";
BA_ "GenSigSendType" SG_ 945 EngineReferenceTorque_UB_ISig_6 7;
BA_ "Platform_VMCU1_Sig" SG_ 945 EngineReferenceTorque_UB_ISig_6 1;
BA_ "GenSigCycleTime" SG_ 945 WheelBasedVehicleSpeed_ISig_6 100;
BA_ "GenSigCycleTimeActive" SG_ 945 WheelBasedVehicleSpeed_ISig_6 100;
BA_ "GenSigStartValue" SG_ 945 WheelBasedVehicleSpeed_ISig_6 65535;
BA_ "GenSigMaxLatency" SG_ 945 WheelBasedVehicleSpeed_ISig_6 54;
BA_ "Platform_VMCU1_Sig" SG_ 945 WheelBasedVehicleSpeed_ISig_6 1;
BA_ "SeToolAncestorID_SIGNAL" SG_ 945 WheelBasedVehicleSpeed_ISig_6 "x0000001D040FEBD2";
BA_ "SeToolItemID_SIGNAL" SG_ 945 WheelBasedVehicleSpeed_ISig_6 "x0000001D040FEBD2";
BA_ "SeToolName_SIGNAL" SG_ 945 WheelBasedVehicleSpeed_ISig_6 "Wheel-BasedVehicleSpeed";
BA_ "SeToolVersion_SIGNAL" SG_ 945 WheelBasedVehicleSpeed_ISig_6 "1";
BA_ "GenSigSendType" SG_ 945 NominalFrictionPercentTorque_UB_ 7;
BA_ "Platform_VMCU1_Sig" SG_ 945 NominalFrictionPercentTorque_UB_ 1;
BA_ "SystemSignalLongSymbol" SG_ 945 NominalFrictionPercentTorque_UB_ "NominalFrictionPercentTorque_UB_ISig_6";
BA_ "GenSigCycleTime" SG_ 945 NominalFrictionPercentTorque_ISi 100;
BA_ "GenSigCycleTimeActive" SG_ 945 NominalFrictionPercentTorque_ISi 100;
BA_ "GenSigStartValue" SG_ 945 NominalFrictionPercentTorque_ISi 255;
BA_ "GenSigMaxLatency" SG_ 945 NominalFrictionPercentTorque_ISi 35;
BA_ "NeedsUpdateBit" SG_ 945 NominalFrictionPercentTorque_ISi 1;
BA_ "Platform_VMCU1_Sig" SG_ 945 NominalFrictionPercentTorque_ISi 1;
BA_ "SeToolAncestorID_SIGNAL" SG_ 945 NominalFrictionPercentTorque_ISi "x0000001D0410CF68";
BA_ "SeToolItemID_SIGNAL" SG_ 945 NominalFrictionPercentTorque_ISi "x0000001D04295709";
BA_ "SeToolName_SIGNAL" SG_ 945 NominalFrictionPercentTorque_ISi "NominalFrictionPercentTorque";
BA_ "SeToolVersion_SIGNAL" SG_ 945 NominalFrictionPercentTorque_ISi "2";
BA_ "SystemSignalLongSymbol" SG_ 945 NominalFrictionPercentTorque_ISi "NominalFrictionPercentTorque_ISig_6";
BA_ "GenSigCycleTime" SG_ 945 ActualEngineRetarderPercentTrq_I 100;
BA_ "GenSigCycleTimeActive" SG_ 945 ActualEngineRetarderPercentTrq_I 100;
BA_ "GenSigStartValue" SG_ 945 ActualEngineRetarderPercentTrq_I 255;
BA_ "GenSigMaxLatency" SG_ 945 ActualEngineRetarderPercentTrq_I 54;
BA_ "Platform_VMCU1_Sig" SG_ 945 ActualEngineRetarderPercentTrq_I 1;
BA_ "SeToolAncestorID_SIGNAL" SG_ 945 ActualEngineRetarderPercentTrq_I "x0000001D0410BAE1";
BA_ "SeToolItemID_SIGNAL" SG_ 945 ActualEngineRetarderPercentTrq_I "x0000001D043C302E";
BA_ "SeToolName_SIGNAL" SG_ 945 ActualEngineRetarderPercentTrq_I "ActualEngineRetarderPercentTorque";
BA_ "SeToolVersion_SIGNAL" SG_ 945 ActualEngineRetarderPercentTrq_I "2";
BA_ "SystemSignalLongSymbol" SG_ 945 ActualEngineRetarderPercentTrq_I "ActualEngineRetarderPercentTrq_ISig_6";
BA_ "GenSigSendType" SG_ 945 ActualEnginePercentTorque_UB_ISi 7;
BA_ "Platform_VMCU1_Sig" SG_ 945 ActualEnginePercentTorque_UB_ISi 1;
BA_ "SystemSignalLongSymbol" SG_ 945 ActualEnginePercentTorque_UB_ISi "ActualEnginePercentTorque_UB_ISig_6";
BA_ "GenSigCycleTime" SG_ 945 EngineReferenceTorque_ISig_6 100;
BA_ "GenSigCycleTimeActive" SG_ 945 EngineReferenceTorque_ISig_6 100;
BA_ "GenSigStartValue" SG_ 945 EngineReferenceTorque_ISig_6 65535;
BA_ "NeedsUpdateBit" SG_ 945 EngineReferenceTorque_ISig_6 1;
BA_ "Platform_VMCU1_Sig" SG_ 945 EngineReferenceTorque_ISig_6 1;
BA_ "SeToolAncestorID_SIGNAL" SG_ 945 EngineReferenceTorque_ISig_6 "x0000001D041286BC";
BA_ "SeToolItemID_SIGNAL" SG_ 945 EngineReferenceTorque_ISig_6 "x0000001D041286BC";
BA_ "SeToolName_SIGNAL" SG_ 945 EngineReferenceTorque_ISig_6 "EngineReferenceTorque";
BA_ "SeToolVersion_SIGNAL" SG_ 945 EngineReferenceTorque_ISig_6 "1";
BA_ "GenSigCycleTime" SG_ 945 RearAxleSteeringFunctionDsbl_ISi 100;
BA_ "GenSigCycleTimeActive" SG_ 945 RearAxleSteeringFunctionDsbl_ISi 100;
BA_ "GenSigStartValue" SG_ 945 RearAxleSteeringFunctionDsbl_ISi 3;
BA_ "Platform_VMCU1_Sig" SG_ 945 RearAxleSteeringFunctionDsbl_ISi 1;
BA_ "SystemSignalLongSymbol" SG_ 945 RearAxleSteeringFunctionDsbl_ISi "RearAxleSteeringFunctionDsbl_ISig_6";
BA_REL_ "GenSigFirstTimeoutTime" BU_SG_REL_ FAS SG_ 1363 FasUsrDefinedStorage_rqst_ISig_6 24000;
BA_REL_ "GenSigTimeoutTime" BU_SG_REL_ FAS SG_ 1363 FasUsrDefinedStorage_rqst_ISig_6 6000;
BA_REL_ "GenSigFirstTimeoutTime" BU_SG_REL_ FAS SG_ 1363 FasDampingSetting_rqst_ISig_6 24000;
BA_REL_ "GenSigTimeoutTime" BU_SG_REL_ FAS SG_ 1363 FasDampingSetting_rqst_ISig_6 6000;
BA_REL_ "GenSigFirstTimeoutTime" BU_SG_REL_ FAS SG_ 1363 FasLowSpeedReturnSetting_rqst_IS 24000;
BA_REL_ "GenSigTimeoutTime" BU_SG_REL_ FAS SG_ 1363 FasLowSpeedReturnSetting_rqst_IS 6000;
BA_REL_ "GenSigFirstTimeoutTime" BU_SG_REL_ FAS SG_ 1363 DriverMemory_rqst_ISig_6 24000;
BA_REL_ "GenSigTimeoutTime" BU_SG_REL_ FAS SG_ 1363 DriverMemory_rqst_ISig_6 6000;
BA_REL_ "GenSigFirstTimeoutTime" BU_SG_REL_ BPMU SG_ 1363 PredeliveryModeIndication_cmd_IS 24000;
BA_REL_ "GenSigTimeoutTime" BU_SG_REL_ BPMU SG_ 1363 PredeliveryModeIndication_cmd_IS 6000;
BA_REL_ "GenSigFirstTimeoutTime" BU_SG_REL_ FAS SG_ 1363 FasPersonalSettingsButton_rqst_I 24000;
BA_REL_ "GenSigTimeoutTime" BU_SG_REL_ FAS SG_ 1363 FasPersonalSettingsButton_rqst_I 6000;
BA_REL_ "GenSigFirstTimeoutTime" BU_SG_REL_ FAS SG_ 1363 FasDriver_rqst_ISig_6 24000;
BA_REL_ "GenSigTimeoutTime" BU_SG_REL_ FAS SG_ 1363 FasDriver_rqst_ISig_6 6000;
BA_REL_ "GenSigFirstTimeoutTime" BU_SG_REL_ FAS SG_ 1363 FasManualOffsetSetting_rqst_ISig 24000;
BA_REL_ "GenSigTimeoutTime" BU_SG_REL_ FAS SG_ 1363 FasManualOffsetSetting_rqst_ISig 6000;
BA_REL_ "GenSigFirstTimeoutTime" BU_SG_REL_ FAS SG_ 1363 FasStiffStraightSetting_rqst_ISi 24000;
BA_REL_ "GenSigTimeoutTime" BU_SG_REL_ FAS SG_ 1363 FasStiffStraightSetting_rqst_ISi 6000;
BA_REL_ "GenSigFirstTimeoutTime" BU_SG_REL_ FAS SG_ 1363 FasStiffnessCurveSetting_rqst_IS 24000;
BA_REL_ "GenSigTimeoutTime" BU_SG_REL_ FAS SG_ 1363 FasStiffnessCurveSetting_rqst_IS 6000;
BA_REL_ "GenSigFirstTimeoutTime" BU_SG_REL_ FAS SG_ 536 FASHapticFeedbackRequest_ISig_6 3000;
BA_REL_ "GenSigTimeoutTime" BU_SG_REL_ FAS SG_ 536 FASHapticFeedbackRequest_ISig_6 120;
BA_REL_ "GenSigFirstTimeoutTime" BU_SG_REL_ FAS SG_ 536 FASRoadWheelAngleRequest_ISig_6 3000;
BA_REL_ "GenSigTimeoutTime" BU_SG_REL_ FAS SG_ 536 FASRoadWheelAngleRequest_ISig_6 120;
BA_REL_ "GenSigFirstTimeoutTime" BU_SG_REL_ FAS SG_ 536 FASExtCtrlMsgCounter_ISig_6 3000;
BA_REL_ "GenSigTimeoutTime" BU_SG_REL_ FAS SG_ 536 FASExtCtrlMsgCounter_ISig_6 120;
BA_REL_ "GenSigFirstTimeoutTime" BU_SG_REL_ FAS SG_ 536 FASExtCtrlMsgChecksum_ISig_6 3000;
BA_REL_ "GenSigTimeoutTime" BU_SG_REL_ FAS SG_ 536 FASExtCtrlMsgChecksum_ISig_6 120;
BA_REL_ "GenSigFirstTimeoutTime" BU_SG_REL_ FAS SG_ 536 FASCurvatureRequest_ISig_6 3000;
BA_REL_ "GenSigTimeoutTime" BU_SG_REL_ FAS SG_ 536 FASCurvatureRequest_ISig_6 120;
BA_REL_ "GenSigFirstTimeoutTime" BU_SG_REL_ FAS SG_ 536 FASControlMode_ISig_6 3000;
BA_REL_ "GenSigTimeoutTime" BU_SG_REL_ FAS SG_ 536 FASControlMode_ISig_6 120;
BA_REL_ "GenSigFirstTimeoutTime" BU_SG_REL_ FAS SG_ 536 ReferencePathCurvature_ISig_6 3000;
BA_REL_ "GenSigTimeoutTime" BU_SG_REL_ FAS SG_ 536 ReferencePathCurvature_ISig_6 120;
BA_REL_ "GenSigFirstTimeoutTime" BU_SG_REL_ RCIOM SG_ 535 DirectionIndicatorLightsStatus 3000;
BA_REL_ "GenSigTimeoutTime" BU_SG_REL_ RCIOM SG_ 535 DirectionIndicatorLightsStatus 180;
BA_REL_ "GenSigFirstTimeoutTime" BU_SG_REL_ FCIOM SG_ 535 DirectionIndicatorLightsStatus 3000;
BA_REL_ "GenSigTimeoutTime" BU_SG_REL_ FCIOM SG_ 535 DirectionIndicatorLightsStatus 180;
BA_REL_ "GenSigFirstTimeoutTime" BU_SG_REL_ APM SG_ 535 ExhManif_AirInjActive_ISig_6 3000;
BA_REL_ "GenSigTimeoutTime" BU_SG_REL_ APM SG_ 535 ExhManif_AirInjActive_ISig_6 180;
BA_REL_ "GenSigFirstTimeoutTime" BU_SG_REL_ FCIOM SG_ 535 HeadlightAngle_cmd 3000;
BA_REL_ "GenSigTimeoutTime" BU_SG_REL_ FCIOM SG_ 535 HeadlightAngle_cmd 180;
BA_REL_ "GenSigFirstTimeoutTime" BU_SG_REL_ CCIOM SG_ 535 ExtendedTrailerBrakeValveReq 3000;
BA_REL_ "GenSigTimeoutTime" BU_SG_REL_ CCIOM SG_ 535 ExtendedTrailerBrakeValveReq 180;
BA_REL_ "GenSigFirstTimeoutTime" BU_SG_REL_ BPMU SG_ 1381 AmbientAirTemperature_ISig_6 12000;
BA_REL_ "GenSigTimeoutTime" BU_SG_REL_ BPMU SG_ 1381 AmbientAirTemperature_ISig_6 3000;
BA_REL_ "GenSigFirstTimeoutTime" BU_SG_REL_ EAS SG_ 1381 AmbientAirTemperature_ISig_6 12000;
BA_REL_ "GenSigTimeoutTime" BU_SG_REL_ EAS SG_ 1381 AmbientAirTemperature_ISig_6 6000;
BA_REL_ "GenSigFirstTimeoutTime" BU_SG_REL_ FCIOM SG_ 1381 AmbientAirTemperature_ISig_6 12000;
BA_REL_ "GenSigTimeoutTime" BU_SG_REL_ FCIOM SG_ 1381 AmbientAirTemperature_ISig_6 6000;
BA_REL_ "GenSigFirstTimeoutTime" BU_SG_REL_ CCIOM SG_ 1381 AmbientAirTemperature_ISig_6 12000;
BA_REL_ "GenSigTimeoutTime" BU_SG_REL_ CCIOM SG_ 1381 AmbientAirTemperature_ISig_6 3000;
BA_REL_ "GenSigFirstTimeoutTime" BU_SG_REL_ FAS SG_ 1381 AmbientAirTemperature_ISig_6 12000;
BA_REL_ "GenSigTimeoutTime" BU_SG_REL_ FAS SG_ 1381 AmbientAirTemperature_ISig_6 3000;
BA_REL_ "GenSigFirstTimeoutTime" BU_SG_REL_ APM SG_ 1381 AmbientAirTemperature_ISig_6 12000;
BA_REL_ "GenSigTimeoutTime" BU_SG_REL_ APM SG_ 1381 AmbientAirTemperature_ISig_6 3000;
BA_REL_ "GenSigFirstTimeoutTime" BU_SG_REL_ TPM SG_ 1381 AmbientAirTemperature_ISig_6 12000;
BA_REL_ "GenSigTimeoutTime" BU_SG_REL_ TPM SG_ 1381 AmbientAirTemperature_ISig_6 3000;
BA_REL_ "GenSigFirstTimeoutTime" BU_SG_REL_ RCIOM SG_ 1381 AmbientAirTemperature_ISig_6 12000;
BA_REL_ "GenSigTimeoutTime" BU_SG_REL_ RCIOM SG_ 1381 AmbientAirTemperature_ISig_6 6000;
BA_REL_ "GenSigFirstTimeoutTime" BU_SG_REL_ BPMU SG_ 1381 StartBatteryReset_rqst 12000;
BA_REL_ "GenSigTimeoutTime" BU_SG_REL_ BPMU SG_ 1381 StartBatteryReset_rqst 3000;
BA_REL_ "GenSigFirstTimeoutTime" BU_SG_REL_ BPMU SG_ 1381 StartBatteryCapacity 12000;
BA_REL_ "GenSigTimeoutTime" BU_SG_REL_ BPMU SG_ 1381 StartBatteryCapacity 3000;
BA_REL_ "GenSigFirstTimeoutTime" BU_SG_REL_ FCIOM SG_ 519 GlareFreeArea02_LeftAngle_ISig_6 3000;
BA_REL_ "GenSigTimeoutTime" BU_SG_REL_ FCIOM SG_ 519 GlareFreeArea02_LeftAngle_ISig_6 120;
BA_REL_ "GenSigFirstTimeoutTime" BU_SG_REL_ FCIOM SG_ 519 GlareFreeArea02_Distance_ISig_6 3000;
BA_REL_ "GenSigTimeoutTime" BU_SG_REL_ FCIOM SG_ 519 GlareFreeArea02_Distance_ISig_6 120;
BA_REL_ "GenSigFirstTimeoutTime" BU_SG_REL_ FCIOM SG_ 519 AdaptiveMainBeamLeft_cmd_ISig_6 3000;
BA_REL_ "GenSigTimeoutTime" BU_SG_REL_ FCIOM SG_ 519 AdaptiveMainBeamLeft_cmd_ISig_6 120;
BA_REL_ "GenSigFirstTimeoutTime" BU_SG_REL_ FCIOM SG_ 519 AdaptiveMainBeamRight_cmd_ISig_6 3000;
BA_REL_ "GenSigTimeoutTime" BU_SG_REL_ FCIOM SG_ 519 AdaptiveMainBeamRight_cmd_ISig_6 120;
BA_REL_ "GenSigFirstTimeoutTime" BU_SG_REL_ FCIOM SG_ 519 GlareFreeArea02_RightAngle_ISig_ 3000;
BA_REL_ "GenSigTimeoutTime" BU_SG_REL_ FCIOM SG_ 519 GlareFreeArea02_RightAngle_ISig_ 120;
BA_REL_ "GenSigFirstTimeoutTime" BU_SG_REL_ FCIOM SG_ 518 GlareFreeArea03_RightAngle_ISig_ 3000;
BA_REL_ "GenSigTimeoutTime" BU_SG_REL_ FCIOM SG_ 518 GlareFreeArea03_RightAngle_ISig_ 120;
BA_REL_ "GenSigFirstTimeoutTime" BU_SG_REL_ FCIOM SG_ 518 GlareFreeArea01_Distance_ISig_6 3000;
BA_REL_ "GenSigTimeoutTime" BU_SG_REL_ FCIOM SG_ 518 GlareFreeArea01_Distance_ISig_6 120;
BA_REL_ "GenSigFirstTimeoutTime" BU_SG_REL_ FCIOM SG_ 518 GlareFreeArea01_LeftAngle_ISig_6 3000;
BA_REL_ "GenSigTimeoutTime" BU_SG_REL_ FCIOM SG_ 518 GlareFreeArea01_LeftAngle_ISig_6 120;
BA_REL_ "GenSigFirstTimeoutTime" BU_SG_REL_ FCIOM SG_ 518 GlareFreeArea03_LeftAngle_ISig_6 3000;
BA_REL_ "GenSigTimeoutTime" BU_SG_REL_ FCIOM SG_ 518 GlareFreeArea03_LeftAngle_ISig_6 120;
BA_REL_ "GenSigFirstTimeoutTime" BU_SG_REL_ FCIOM SG_ 518 GlareFreeArea03_Distance_ISig_6 3000;
BA_REL_ "GenSigTimeoutTime" BU_SG_REL_ FCIOM SG_ 518 GlareFreeArea03_Distance_ISig_6 120;
BA_REL_ "GenSigFirstTimeoutTime" BU_SG_REL_ FCIOM SG_ 518 GlareFreeArea01_RightAngle_ISig_ 3000;
BA_REL_ "GenSigTimeoutTime" BU_SG_REL_ FCIOM SG_ 518 GlareFreeArea01_RightAngle_ISig_ 120;
BA_REL_ "GenSigFirstTimeoutTime" BU_SG_REL_ TPM SG_ 1370 TPMSetAxleTireConfig_Axle2_ISig_ 12000;
BA_REL_ "GenSigTimeoutTime" BU_SG_REL_ TPM SG_ 1370 TPMSetAxleTireConfig_Axle2_ISig_ 3000;
BA_REL_ "GenSigFirstTimeoutTime" BU_SG_REL_ TPM SG_ 1370 TPMSetPresThresCfg_AxleNr_ISig_6 12000;
BA_REL_ "GenSigTimeoutTime" BU_SG_REL_ TPM SG_ 1370 TPMSetPresThresCfg_AxleNr_ISig_6 3000;
BA_REL_ "GenSigFirstTimeoutTime" BU_SG_REL_ TPM SG_ 1370 TPMSetPresThresCfg_VehiclePos_IS 12000;
BA_REL_ "GenSigTimeoutTime" BU_SG_REL_ TPM SG_ 1370 TPMSetPresThresCfg_VehiclePos_IS 3000;
BA_REL_ "GenSigFirstTimeoutTime" BU_SG_REL_ TPM SG_ 1370 TPMSetPresThresCfg_ExtOverPres_I 12000;
BA_REL_ "GenSigTimeoutTime" BU_SG_REL_ TPM SG_ 1370 TPMSetPresThresCfg_ExtOverPres_I 3000;
BA_REL_ "GenSigFirstTimeoutTime" BU_SG_REL_ TPM SG_ 1370 TPMSetPresThresCfg_ExtUnderPres_ 12000;
BA_REL_ "GenSigTimeoutTime" BU_SG_REL_ TPM SG_ 1370 TPMSetPresThresCfg_ExtUnderPres_ 3000;
BA_REL_ "GenSigFirstTimeoutTime" BU_SG_REL_ TPM SG_ 1370 TPMSetPresThresCfg_UnderPres_ISi 12000;
BA_REL_ "GenSigTimeoutTime" BU_SG_REL_ TPM SG_ 1370 TPMSetPresThresCfg_UnderPres_ISi 3000;
BA_REL_ "GenSigFirstTimeoutTime" BU_SG_REL_ TPM SG_ 1370 TPMSetAxleTireConfig_Axle4_ISig_ 12000;
BA_REL_ "GenSigTimeoutTime" BU_SG_REL_ TPM SG_ 1370 TPMSetAxleTireConfig_Axle4_ISig_ 3000;
BA_REL_ "GenSigFirstTimeoutTime" BU_SG_REL_ TPM SG_ 1370 TPMSetPresThresCfg_OverPres_ISig 12000;
BA_REL_ "GenSigTimeoutTime" BU_SG_REL_ TPM SG_ 1370 TPMSetPresThresCfg_OverPres_ISig 3000;
BA_REL_ "GenSigFirstTimeoutTime" BU_SG_REL_ TPM SG_ 1370 TPMSetAxleTireConfig_Axle1_ISig_ 12000;
BA_REL_ "GenSigTimeoutTime" BU_SG_REL_ TPM SG_ 1370 TPMSetAxleTireConfig_Axle1_ISig_ 3000;
BA_REL_ "GenSigFirstTimeoutTime" BU_SG_REL_ TPM SG_ 1370 TPMSetAxleTireConfig_Axle5_ISig_ 12000;
BA_REL_ "GenSigTimeoutTime" BU_SG_REL_ TPM SG_ 1370 TPMSetAxleTireConfig_Axle5_ISig_ 3000;
BA_REL_ "GenSigFirstTimeoutTime" BU_SG_REL_ TPM SG_ 1370 TPMSetAxleTireConfig_VehiclePos_ 12000;
BA_REL_ "GenSigTimeoutTime" BU_SG_REL_ TPM SG_ 1370 TPMSetAxleTireConfig_VehiclePos_ 3000;
BA_REL_ "GenSigFirstTimeoutTime" BU_SG_REL_ TPM SG_ 1370 TPMSetAxleTireConfig_Axle3_ISig_ 12000;
BA_REL_ "GenSigTimeoutTime" BU_SG_REL_ TPM SG_ 1370 TPMSetAxleTireConfig_Axle3_ISig_ 3000;
BA_REL_ "GenSigFirstTimeoutTime" BU_SG_REL_ TPM SG_ 1373 TPMSetAxleRefPres_Axle2_ISig_6 12000;
BA_REL_ "GenSigTimeoutTime" BU_SG_REL_ TPM SG_ 1373 TPMSetAxleRefPres_Axle2_ISig_6 3000;
BA_REL_ "GenSigFirstTimeoutTime" BU_SG_REL_ TPM SG_ 1373 TPMMateTrailerReq_ISig_6 12000;
BA_REL_ "GenSigTimeoutTime" BU_SG_REL_ TPM SG_ 1373 TPMMateTrailerReq_ISig_6 3000;
BA_REL_ "GenSigFirstTimeoutTime" BU_SG_REL_ TPM SG_ 1373 TPMSetAxleRefPres_Axle1_ISig_6 12000;
BA_REL_ "GenSigTimeoutTime" BU_SG_REL_ TPM SG_ 1373 TPMSetAxleRefPres_Axle1_ISig_6 3000;
BA_REL_ "GenSigFirstTimeoutTime" BU_SG_REL_ TPM SG_ 1373 TPMSetAxleRefPres_Axle3_ISig_6 12000;
BA_REL_ "GenSigTimeoutTime" BU_SG_REL_ TPM SG_ 1373 TPMSetAxleRefPres_Axle3_ISig_6 3000;
BA_REL_ "GenSigFirstTimeoutTime" BU_SG_REL_ TPM SG_ 1373 TPMPosOfWMReq_VehiclePos_ISig_6 12000;
BA_REL_ "GenSigTimeoutTime" BU_SG_REL_ TPM SG_ 1373 TPMPosOfWMReq_VehiclePos_ISig_6 3000;
BA_REL_ "GenSigFirstTimeoutTime" BU_SG_REL_ TPM SG_ 1373 TPMSetAxleRefPres_Axle4_ISig_6 12000;
BA_REL_ "GenSigTimeoutTime" BU_SG_REL_ TPM SG_ 1373 TPMSetAxleRefPres_Axle4_ISig_6 3000;
BA_REL_ "GenSigFirstTimeoutTime" BU_SG_REL_ TPM SG_ 1373 TPMSetAxleRefPres_VehiclePos_ISi 12000;
BA_REL_ "GenSigTimeoutTime" BU_SG_REL_ TPM SG_ 1373 TPMSetAxleRefPres_VehiclePos_ISi 3000;
BA_REL_ "GenSigFirstTimeoutTime" BU_SG_REL_ TPM SG_ 1373 TPMSetAxleRefPres_Axle5_ISig_6 12000;
BA_REL_ "GenSigTimeoutTime" BU_SG_REL_ TPM SG_ 1373 TPMSetAxleRefPres_Axle5_ISig_6 3000;
BA_REL_ "GenSigFirstTimeoutTime" BU_SG_REL_ TPM SG_ 1373 TPMPosOfWMReq_TireId_ISig_6 12000;
BA_REL_ "GenSigTimeoutTime" BU_SG_REL_ TPM SG_ 1373 TPMPosOfWMReq_TireId_ISig_6 3000;
BA_REL_ "GenSigFirstTimeoutTime" BU_SG_REL_ TPM SG_ 1373 TPMUnmateTrailerReq_ISig_6 12000;
BA_REL_ "GenSigTimeoutTime" BU_SG_REL_ TPM SG_ 1373 TPMUnmateTrailerReq_ISig_6 3000;
BA_REL_ "GenSigFirstTimeoutTime" BU_SG_REL_ RCIOM SG_ 1249 TransferCasePTOEngaged_ISig_6 3000;
BA_REL_ "GenSigTimeoutTime" BU_SG_REL_ RCIOM SG_ 1249 TransferCasePTOEngaged_ISig_6 600;
BA_REL_ "GenSigFirstTimeoutTime" BU_SG_REL_ EBS SG_ 1249 ContTrailerBrake_MsgCounter 3000;
BA_REL_ "GenSigTimeoutTime" BU_SG_REL_ EBS SG_ 1249 ContTrailerBrake_MsgCounter 600;
BA_REL_ "GenSigFirstTimeoutTime" BU_SG_REL_ APM SG_ 1249 ABSFullyOperational_ISig_6 3000;
BA_REL_ "GenSigTimeoutTime" BU_SG_REL_ APM SG_ 1249 ABSFullyOperational_ISig_6 600;
BA_REL_ "GenSigFirstTimeoutTime" BU_SG_REL_ RCIOM SG_ 1249 ExtECSRequestPressureUpdate 3000;
BA_REL_ "GenSigTimeoutTime" BU_SG_REL_ RCIOM SG_ 1249 ExtECSRequestPressureUpdate 600;
BA_REL_ "GenSigFirstTimeoutTime" BU_SG_REL_ FCIOM SG_ 1249 HeadLampFanControl_rqst 3000;
BA_REL_ "GenSigTimeoutTime" BU_SG_REL_ FCIOM SG_ 1249 HeadLampFanControl_rqst 600;
BA_REL_ "GenSigFirstTimeoutTime" BU_SG_REL_ EBS SG_ 1249 ContTrailerBrake_Request 3000;
BA_REL_ "GenSigTimeoutTime" BU_SG_REL_ EBS SG_ 1249 ContTrailerBrake_Request 600;
BA_REL_ "GenSigFirstTimeoutTime" BU_SG_REL_ FAS SG_ 1249 ACC_SGO_Status_ISig_6 3000;
BA_REL_ "GenSigTimeoutTime" BU_SG_REL_ FAS SG_ 1249 ACC_SGO_Status_ISig_6 600;
BA_REL_ "GenSigFirstTimeoutTime" BU_SG_REL_ CCIOM SG_ 1249 ClutchSwitch2Stat 3000;
BA_REL_ "GenSigTimeoutTime" BU_SG_REL_ CCIOM SG_ 1249 ClutchSwitch2Stat 600;
BA_REL_ "GenSigFirstTimeoutTime" BU_SG_REL_ CCIOM SG_ 1249 FrAxle2WheelDriveRequest 3000;
BA_REL_ "GenSigTimeoutTime" BU_SG_REL_ CCIOM SG_ 1249 FrAxle2WheelDriveRequest 600;
BA_REL_ "GenSigFirstTimeoutTime" BU_SG_REL_ CCIOM SG_ 1249 SideMarkersLights_cmd 3000;
BA_REL_ "GenSigTimeoutTime" BU_SG_REL_ CCIOM SG_ 1249 SideMarkersLights_cmd 600;
BA_REL_ "GenSigFirstTimeoutTime" BU_SG_REL_ CCIOM SG_ 1249 LivBatteryChargingStat_rqst 3000;
BA_REL_ "GenSigTimeoutTime" BU_SG_REL_ CCIOM SG_ 1249 LivBatteryChargingStat_rqst 600;
BA_REL_ "GenSigFirstTimeoutTime" BU_SG_REL_ EBS SG_ 1249 ContTrailerBrake_MsgChecksum 3000;
BA_REL_ "GenSigTimeoutTime" BU_SG_REL_ EBS SG_ 1249 ContTrailerBrake_MsgChecksum 600;
BA_REL_ "GenSigFirstTimeoutTime" BU_SG_REL_ CCIOM SG_ 1338 TransmEngineCrankEnable_ISig_6 3000;
BA_REL_ "GenSigTimeoutTime" BU_SG_REL_ CCIOM SG_ 1338 TransmEngineCrankEnable_ISig_6 600;
BA_REL_ "GenSigFirstTimeoutTime" BU_SG_REL_ RCIOM SG_ 944 LoadDistributionRequested_ISig_6 3000;
BA_REL_ "GenSigTimeoutTime" BU_SG_REL_ RCIOM SG_ 944 LoadDistributionRequested_ISig_6 500;
BA_REL_ "GenSigFirstTimeoutTime" BU_SG_REL_ CCIOM SG_ 944 ShortStopHeater_cmd_ISig_6 3000;
BA_REL_ "GenSigTimeoutTime" BU_SG_REL_ CCIOM SG_ 944 ShortStopHeater_cmd_ISig_6 300;
BA_REL_ "GenSigFirstTimeoutTime" BU_SG_REL_ APM SG_ 944 XPRRequest_RBS_ISig_6 3000;
BA_REL_ "GenSigTimeoutTime" BU_SG_REL_ APM SG_ 944 XPRRequest_RBS_ISig_6 300;
BA_REL_ "GenSigFirstTimeoutTime" BU_SG_REL_ APM SG_ 944 PBReleaseInhibit_rqst 3000;
BA_REL_ "GenSigTimeoutTime" BU_SG_REL_ APM SG_ 944 PBReleaseInhibit_rqst 500;
BA_REL_ "GenSigFirstTimeoutTime" BU_SG_REL_ APM SG_ 944 TachographVehicleSpeed_ISig_6 3000;
BA_REL_ "GenSigTimeoutTime" BU_SG_REL_ APM SG_ 944 TachographVehicleSpeed_ISig_6 500;
BA_REL_ "GenSigFirstTimeoutTime" BU_SG_REL_ APM SG_ 944 TachographOutputShaftSpeed_ISig_ 3000;
BA_REL_ "GenSigTimeoutTime" BU_SG_REL_ APM SG_ 944 TachographOutputShaftSpeed_ISig_ 500;
BA_REL_ "GenSigFirstTimeoutTime" BU_SG_REL_ APM SG_ 944 XPRRequest_CM_ISig_6 3000;
BA_REL_ "GenSigTimeoutTime" BU_SG_REL_ APM SG_ 944 XPRRequest_CM_ISig_6 300;
BA_REL_ "GenSigFirstTimeoutTime" BU_SG_REL_ APM SG_ 944 SWEngineStop_rqst_ISig_6 3000;
BA_REL_ "GenSigTimeoutTime" BU_SG_REL_ APM SG_ 944 SWEngineStop_rqst_ISig_6 300;
BA_REL_ "GenSigFirstTimeoutTime" BU_SG_REL_ CCIOM SG_ 390 FrontAxleRightWheelSpeed_ISig_6 3000;
BA_REL_ "GenSigTimeoutTime" BU_SG_REL_ CCIOM SG_ 390 FrontAxleRightWheelSpeed_ISig_6 500;
BA_REL_ "GenSigFirstTimeoutTime" BU_SG_REL_ EAS SG_ 390 FrontAxleRightWheelSpeed_ISig_6 3000;
BA_REL_ "GenSigTimeoutTime" BU_SG_REL_ EAS SG_ 390 FrontAxleRightWheelSpeed_ISig_6 500;
BA_REL_ "GenSigFirstTimeoutTime" BU_SG_REL_ FAS SG_ 390 FrontAxleRightWheelSpeed_ISig_6 3000;
BA_REL_ "GenSigTimeoutTime" BU_SG_REL_ FAS SG_ 390 FrontAxleRightWheelSpeed_ISig_6 500;
BA_REL_ "GenSigFirstTimeoutTime" BU_SG_REL_ FCIOM SG_ 390 CityHorn_cmd_ISig_6 3000;
BA_REL_ "GenSigTimeoutTime" BU_SG_REL_ FCIOM SG_ 390 CityHorn_cmd_ISig_6 500;
BA_REL_ "GenSigFirstTimeoutTime" BU_SG_REL_ RCIOM SG_ 390 LevelRequest_RollRequest_ISig_6 3000;
BA_REL_ "GenSigTimeoutTime" BU_SG_REL_ RCIOM SG_ 390 LevelRequest_RollRequest_ISig_6 500;
BA_REL_ "GenSigFirstTimeoutTime" BU_SG_REL_ EAS SG_ 390 FrontAxleLeftWheelSpeed_ISig_6 3000;
BA_REL_ "GenSigTimeoutTime" BU_SG_REL_ EAS SG_ 390 FrontAxleLeftWheelSpeed_ISig_6 500;
BA_REL_ "GenSigFirstTimeoutTime" BU_SG_REL_ FAS SG_ 390 FrontAxleLeftWheelSpeed_ISig_6 3000;
BA_REL_ "GenSigTimeoutTime" BU_SG_REL_ FAS SG_ 390 FrontAxleLeftWheelSpeed_ISig_6 500;
BA_REL_ "GenSigFirstTimeoutTime" BU_SG_REL_ CCIOM SG_ 390 FrontAxleLeftWheelSpeed_ISig_6 3000;
BA_REL_ "GenSigTimeoutTime" BU_SG_REL_ CCIOM SG_ 390 FrontAxleLeftWheelSpeed_ISig_6 500;
BA_REL_ "GenSigFirstTimeoutTime" BU_SG_REL_ APM SG_ 390 ClutchSwitch_ISig_6 3000;
BA_REL_ "GenSigTimeoutTime" BU_SG_REL_ APM SG_ 390 ClutchSwitch_ISig_6 60;
BA_REL_ "GenSigFirstTimeoutTime" BU_SG_REL_ FCIOM SG_ 390 AuxiliaryHorn_cmd_ISig_6 3000;
BA_REL_ "GenSigTimeoutTime" BU_SG_REL_ FCIOM SG_ 390 AuxiliaryHorn_cmd_ISig_6 500;
BA_REL_ "GenSigFirstTimeoutTime" BU_SG_REL_ RCIOM SG_ 390 LevelRequest_RearAxle_ISig_6 3000;
BA_REL_ "GenSigTimeoutTime" BU_SG_REL_ RCIOM SG_ 390 LevelRequest_RearAxle_ISig_6 500;
BA_REL_ "GenSigFirstTimeoutTime" BU_SG_REL_ CCIOM SG_ 390 BrakeSwitch_ISig_6 3000;
BA_REL_ "GenSigTimeoutTime" BU_SG_REL_ CCIOM SG_ 390 BrakeSwitch_ISig_6 60;
BA_REL_ "GenSigFirstTimeoutTime" BU_SG_REL_ APM SG_ 390 BrakeSwitch_ISig_6 3000;
BA_REL_ "GenSigTimeoutTime" BU_SG_REL_ APM SG_ 390 BrakeSwitch_ISig_6 60;
BA_REL_ "GenSigFirstTimeoutTime" BU_SG_REL_ RCIOM SG_ 390 FPBRChangeReq_ISig_6 3000;
BA_REL_ "GenSigTimeoutTime" BU_SG_REL_ RCIOM SG_ 390 FPBRChangeReq_ISig_6 60;
BA_REL_ "GenSigFirstTimeoutTime" BU_SG_REL_ RCIOM SG_ 390 LevelRequest_FrontAxle_ISig_6 3000;
BA_REL_ "GenSigTimeoutTime" BU_SG_REL_ RCIOM SG_ 390 LevelRequest_FrontAxle_ISig_6 500;
BA_REL_ "GenSigFirstTimeoutTime" BU_SG_REL_ CCIOM SG_ 389 FrontWheelDriveRequest 3000;
BA_REL_ "GenSigTimeoutTime" BU_SG_REL_ CCIOM SG_ 389 FrontWheelDriveRequest 60;
BA_REL_ "GenSigFirstTimeoutTime" BU_SG_REL_ CCIOM SG_ 389 RearAxleLeftWheelSpeed_ISig_6 3000;
BA_REL_ "GenSigTimeoutTime" BU_SG_REL_ CCIOM SG_ 389 RearAxleLeftWheelSpeed_ISig_6 500;
BA_REL_ "GenSigFirstTimeoutTime" BU_SG_REL_ EAS SG_ 389 RearAxleLeftWheelSpeed_ISig_6 3000;
BA_REL_ "GenSigTimeoutTime" BU_SG_REL_ EAS SG_ 389 RearAxleLeftWheelSpeed_ISig_6 500;
BA_REL_ "GenSigFirstTimeoutTime" BU_SG_REL_ RCIOM SG_ 389 RearAxleLeftWheelSpeed_ISig_6 3000;
BA_REL_ "GenSigTimeoutTime" BU_SG_REL_ RCIOM SG_ 389 RearAxleLeftWheelSpeed_ISig_6 500;
BA_REL_ "GenSigFirstTimeoutTime" BU_SG_REL_ CCIOM SG_ 389 RearAxleRightWheelSpeed_ISig_6 3000;
BA_REL_ "GenSigTimeoutTime" BU_SG_REL_ CCIOM SG_ 389 RearAxleRightWheelSpeed_ISig_6 500;
BA_REL_ "GenSigFirstTimeoutTime" BU_SG_REL_ EAS SG_ 389 RearAxleRightWheelSpeed_ISig_6 3000;
BA_REL_ "GenSigTimeoutTime" BU_SG_REL_ EAS SG_ 389 RearAxleRightWheelSpeed_ISig_6 500;
BA_REL_ "GenSigFirstTimeoutTime" BU_SG_REL_ RCIOM SG_ 389 RearAxleRightWheelSpeed_ISig_6 3000;
BA_REL_ "GenSigTimeoutTime" BU_SG_REL_ RCIOM SG_ 389 RearAxleRightWheelSpeed_ISig_6 500;
BA_REL_ "GenSigFirstTimeoutTime" BU_SG_REL_ RCIOM SG_ 389 KneelingChangeRequest_ISig_6 3000;
BA_REL_ "GenSigTimeoutTime" BU_SG_REL_ RCIOM SG_ 389 KneelingChangeRequest_ISig_6 120;
BA_REL_ "GenSigFirstTimeoutTime" BU_SG_REL_ APM SG_ 1364 ExhManif_EMAIAirTankPres_ISig_6 6000;
BA_REL_ "GenSigTimeoutTime" BU_SG_REL_ APM SG_ 1364 ExhManif_EMAIAirTankPres_ISig_6 1500;
BA_REL_ "GenSigFirstTimeoutTime" BU_SG_REL_ APM SG_ 1364 DayUTC_ISig_6 6000;
BA_REL_ "GenSigTimeoutTime" BU_SG_REL_ APM SG_ 1364 DayUTC_ISig_6 1500;
BA_REL_ "GenSigFirstTimeoutTime" BU_SG_REL_ RCIOM SG_ 1364 DayUTC_ISig_6 6000;
BA_REL_ "GenSigTimeoutTime" BU_SG_REL_ RCIOM SG_ 1364 DayUTC_ISig_6 1500;
BA_REL_ "GenSigFirstTimeoutTime" BU_SG_REL_ EAS SG_ 1364 DayUTC_ISig_6 6000;
BA_REL_ "GenSigTimeoutTime" BU_SG_REL_ EAS SG_ 1364 DayUTC_ISig_6 1500;
BA_REL_ "GenSigFirstTimeoutTime" BU_SG_REL_ FAS SG_ 1364 DayUTC_ISig_6 6000;
BA_REL_ "GenSigTimeoutTime" BU_SG_REL_ FAS SG_ 1364 DayUTC_ISig_6 1500;
BA_REL_ "GenSigFirstTimeoutTime" BU_SG_REL_ BPMU SG_ 1364 DayUTC_ISig_6 6000;
BA_REL_ "GenSigTimeoutTime" BU_SG_REL_ BPMU SG_ 1364 DayUTC_ISig_6 1500;
BA_REL_ "GenSigFirstTimeoutTime" BU_SG_REL_ FCIOM SG_ 1364 DayUTC_ISig_6 6000;
BA_REL_ "GenSigTimeoutTime" BU_SG_REL_ FCIOM SG_ 1364 DayUTC_ISig_6 1500;
BA_REL_ "GenSigFirstTimeoutTime" BU_SG_REL_ TPM SG_ 1364 DayUTC_ISig_6 6000;
BA_REL_ "GenSigTimeoutTime" BU_SG_REL_ TPM SG_ 1364 DayUTC_ISig_6 1500;
BA_REL_ "GenSigFirstTimeoutTime" BU_SG_REL_ CCIOM SG_ 1364 DayUTC_ISig_6 6000;
BA_REL_ "GenSigTimeoutTime" BU_SG_REL_ CCIOM SG_ 1364 DayUTC_ISig_6 1500;
BA_REL_ "GenSigFirstTimeoutTime" BU_SG_REL_ FAS SG_ 1364 HoursUTC_ISig_6 6000;
BA_REL_ "GenSigTimeoutTime" BU_SG_REL_ FAS SG_ 1364 HoursUTC_ISig_6 1500;
BA_REL_ "GenSigFirstTimeoutTime" BU_SG_REL_ EAS SG_ 1364 HoursUTC_ISig_6 6000;
BA_REL_ "GenSigTimeoutTime" BU_SG_REL_ EAS SG_ 1364 HoursUTC_ISig_6 1500;
BA_REL_ "GenSigFirstTimeoutTime" BU_SG_REL_ TPM SG_ 1364 HoursUTC_ISig_6 6000;
BA_REL_ "GenSigTimeoutTime" BU_SG_REL_ TPM SG_ 1364 HoursUTC_ISig_6 1500;
BA_REL_ "GenSigFirstTimeoutTime" BU_SG_REL_ RCIOM SG_ 1364 HoursUTC_ISig_6 6000;
BA_REL_ "GenSigTimeoutTime" BU_SG_REL_ RCIOM SG_ 1364 HoursUTC_ISig_6 1500;
BA_REL_ "GenSigFirstTimeoutTime" BU_SG_REL_ BPMU SG_ 1364 HoursUTC_ISig_6 6000;
BA_REL_ "GenSigTimeoutTime" BU_SG_REL_ BPMU SG_ 1364 HoursUTC_ISig_6 1500;
BA_REL_ "GenSigFirstTimeoutTime" BU_SG_REL_ CCIOM SG_ 1364 HoursUTC_ISig_6 6000;
BA_REL_ "GenSigTimeoutTime" BU_SG_REL_ CCIOM SG_ 1364 HoursUTC_ISig_6 1500;
BA_REL_ "GenSigFirstTimeoutTime" BU_SG_REL_ APM SG_ 1364 HoursUTC_ISig_6 6000;
BA_REL_ "GenSigTimeoutTime" BU_SG_REL_ APM SG_ 1364 HoursUTC_ISig_6 1500;
BA_REL_ "GenSigFirstTimeoutTime" BU_SG_REL_ FCIOM SG_ 1364 HoursUTC_ISig_6 6000;
BA_REL_ "GenSigTimeoutTime" BU_SG_REL_ FCIOM SG_ 1364 HoursUTC_ISig_6 1500;
BA_REL_ "GenSigFirstTimeoutTime" BU_SG_REL_ FAS SG_ 1364 SecondsUTC_ISig_6 6000;
BA_REL_ "GenSigTimeoutTime" BU_SG_REL_ FAS SG_ 1364 SecondsUTC_ISig_6 1500;
BA_REL_ "GenSigFirstTimeoutTime" BU_SG_REL_ FCIOM SG_ 1364 SecondsUTC_ISig_6 6000;
BA_REL_ "GenSigTimeoutTime" BU_SG_REL_ FCIOM SG_ 1364 SecondsUTC_ISig_6 1500;
BA_REL_ "GenSigFirstTimeoutTime" BU_SG_REL_ APM SG_ 1364 SecondsUTC_ISig_6 6000;
BA_REL_ "GenSigTimeoutTime" BU_SG_REL_ APM SG_ 1364 SecondsUTC_ISig_6 1500;
BA_REL_ "GenSigFirstTimeoutTime" BU_SG_REL_ BPMU SG_ 1364 SecondsUTC_ISig_6 6000;
BA_REL_ "GenSigTimeoutTime" BU_SG_REL_ BPMU SG_ 1364 SecondsUTC_ISig_6 1500;
BA_REL_ "GenSigFirstTimeoutTime" BU_SG_REL_ CCIOM SG_ 1364 SecondsUTC_ISig_6 6000;
BA_REL_ "GenSigTimeoutTime" BU_SG_REL_ CCIOM SG_ 1364 SecondsUTC_ISig_6 1500;
BA_REL_ "GenSigFirstTimeoutTime" BU_SG_REL_ RCIOM SG_ 1364 SecondsUTC_ISig_6 6000;
BA_REL_ "GenSigTimeoutTime" BU_SG_REL_ RCIOM SG_ 1364 SecondsUTC_ISig_6 1500;
BA_REL_ "GenSigFirstTimeoutTime" BU_SG_REL_ EAS SG_ 1364 SecondsUTC_ISig_6 6000;
BA_REL_ "GenSigTimeoutTime" BU_SG_REL_ EAS SG_ 1364 SecondsUTC_ISig_6 1500;
BA_REL_ "GenSigFirstTimeoutTime" BU_SG_REL_ TPM SG_ 1364 SecondsUTC_ISig_6 6000;
BA_REL_ "GenSigTimeoutTime" BU_SG_REL_ TPM SG_ 1364 SecondsUTC_ISig_6 1500;
BA_REL_ "GenSigFirstTimeoutTime" BU_SG_REL_ FAS SG_ 1364 YearUTC_ISig_6 6000;
BA_REL_ "GenSigTimeoutTime" BU_SG_REL_ FAS SG_ 1364 YearUTC_ISig_6 1500;
BA_REL_ "GenSigFirstTimeoutTime" BU_SG_REL_ CCIOM SG_ 1364 YearUTC_ISig_6 6000;
BA_REL_ "GenSigTimeoutTime" BU_SG_REL_ CCIOM SG_ 1364 YearUTC_ISig_6 1500;
BA_REL_ "GenSigFirstTimeoutTime" BU_SG_REL_ APM SG_ 1364 YearUTC_ISig_6 6000;
BA_REL_ "GenSigTimeoutTime" BU_SG_REL_ APM SG_ 1364 YearUTC_ISig_6 1500;
BA_REL_ "GenSigFirstTimeoutTime" BU_SG_REL_ RCIOM SG_ 1364 YearUTC_ISig_6 6000;
BA_REL_ "GenSigTimeoutTime" BU_SG_REL_ RCIOM SG_ 1364 YearUTC_ISig_6 1500;
BA_REL_ "GenSigFirstTimeoutTime" BU_SG_REL_ EAS SG_ 1364 YearUTC_ISig_6 6000;
BA_REL_ "GenSigTimeoutTime" BU_SG_REL_ EAS SG_ 1364 YearUTC_ISig_6 1500;
BA_REL_ "GenSigFirstTimeoutTime" BU_SG_REL_ BPMU SG_ 1364 YearUTC_ISig_6 6000;
BA_REL_ "GenSigTimeoutTime" BU_SG_REL_ BPMU SG_ 1364 YearUTC_ISig_6 1500;
BA_REL_ "GenSigFirstTimeoutTime" BU_SG_REL_ TPM SG_ 1364 YearUTC_ISig_6 6000;
BA_REL_ "GenSigTimeoutTime" BU_SG_REL_ TPM SG_ 1364 YearUTC_ISig_6 1500;
BA_REL_ "GenSigFirstTimeoutTime" BU_SG_REL_ FCIOM SG_ 1364 YearUTC_ISig_6 6000;
BA_REL_ "GenSigTimeoutTime" BU_SG_REL_ FCIOM SG_ 1364 YearUTC_ISig_6 1500;
BA_REL_ "GenSigFirstTimeoutTime" BU_SG_REL_ EAS SG_ 1364 MinutesUTC_ISig_6 6000;
BA_REL_ "GenSigTimeoutTime" BU_SG_REL_ EAS SG_ 1364 MinutesUTC_ISig_6 1500;
BA_REL_ "GenSigFirstTimeoutTime" BU_SG_REL_ CCIOM SG_ 1364 MinutesUTC_ISig_6 6000;
BA_REL_ "GenSigTimeoutTime" BU_SG_REL_ CCIOM SG_ 1364 MinutesUTC_ISig_6 1500;
BA_REL_ "GenSigFirstTimeoutTime" BU_SG_REL_ TPM SG_ 1364 MinutesUTC_ISig_6 6000;
BA_REL_ "GenSigTimeoutTime" BU_SG_REL_ TPM SG_ 1364 MinutesUTC_ISig_6 1500;
BA_REL_ "GenSigFirstTimeoutTime" BU_SG_REL_ APM SG_ 1364 MinutesUTC_ISig_6 6000;
BA_REL_ "GenSigTimeoutTime" BU_SG_REL_ APM SG_ 1364 MinutesUTC_ISig_6 1500;
BA_REL_ "GenSigFirstTimeoutTime" BU_SG_REL_ RCIOM SG_ 1364 MinutesUTC_ISig_6 6000;
BA_REL_ "GenSigTimeoutTime" BU_SG_REL_ RCIOM SG_ 1364 MinutesUTC_ISig_6 1500;
BA_REL_ "GenSigFirstTimeoutTime" BU_SG_REL_ BPMU SG_ 1364 MinutesUTC_ISig_6 6000;
BA_REL_ "GenSigTimeoutTime" BU_SG_REL_ BPMU SG_ 1364 MinutesUTC_ISig_6 1500;
BA_REL_ "GenSigFirstTimeoutTime" BU_SG_REL_ FCIOM SG_ 1364 MinutesUTC_ISig_6 6000;
BA_REL_ "GenSigTimeoutTime" BU_SG_REL_ FCIOM SG_ 1364 MinutesUTC_ISig_6 1500;
BA_REL_ "GenSigFirstTimeoutTime" BU_SG_REL_ FAS SG_ 1364 MinutesUTC_ISig_6 6000;
BA_REL_ "GenSigTimeoutTime" BU_SG_REL_ FAS SG_ 1364 MinutesUTC_ISig_6 1500;
BA_REL_ "GenSigFirstTimeoutTime" BU_SG_REL_ RCIOM SG_ 1364 RoadInclination_ISig_6 6000;
BA_REL_ "GenSigTimeoutTime" BU_SG_REL_ RCIOM SG_ 1364 RoadInclination_ISig_6 1500;
BA_REL_ "GenSigFirstTimeoutTime" BU_SG_REL_ CCIOM SG_ 1364 MonthUTC_ISig_6 6000;
BA_REL_ "GenSigTimeoutTime" BU_SG_REL_ CCIOM SG_ 1364 MonthUTC_ISig_6 1500;
BA_REL_ "GenSigFirstTimeoutTime" BU_SG_REL_ EAS SG_ 1364 MonthUTC_ISig_6 6000;
BA_REL_ "GenSigTimeoutTime" BU_SG_REL_ EAS SG_ 1364 MonthUTC_ISig_6 1500;
BA_REL_ "GenSigFirstTimeoutTime" BU_SG_REL_ TPM SG_ 1364 MonthUTC_ISig_6 6000;
BA_REL_ "GenSigTimeoutTime" BU_SG_REL_ TPM SG_ 1364 MonthUTC_ISig_6 1500;
BA_REL_ "GenSigFirstTimeoutTime" BU_SG_REL_ FAS SG_ 1364 MonthUTC_ISig_6 6000;
BA_REL_ "GenSigTimeoutTime" BU_SG_REL_ FAS SG_ 1364 MonthUTC_ISig_6 1500;
BA_REL_ "GenSigFirstTimeoutTime" BU_SG_REL_ APM SG_ 1364 MonthUTC_ISig_6 6000;
BA_REL_ "GenSigTimeoutTime" BU_SG_REL_ APM SG_ 1364 MonthUTC_ISig_6 1500;
BA_REL_ "GenSigFirstTimeoutTime" BU_SG_REL_ FCIOM SG_ 1364 MonthUTC_ISig_6 6000;
BA_REL_ "GenSigTimeoutTime" BU_SG_REL_ FCIOM SG_ 1364 MonthUTC_ISig_6 1500;
BA_REL_ "GenSigFirstTimeoutTime" BU_SG_REL_ RCIOM SG_ 1364 MonthUTC_ISig_6 6000;
BA_REL_ "GenSigTimeoutTime" BU_SG_REL_ RCIOM SG_ 1364 MonthUTC_ISig_6 1500;
BA_REL_ "GenSigFirstTimeoutTime" BU_SG_REL_ BPMU SG_ 1364 MonthUTC_ISig_6 6000;
BA_REL_ "GenSigTimeoutTime" BU_SG_REL_ BPMU SG_ 1364 MonthUTC_ISig_6 1500;
BA_REL_ "GenSigFirstTimeoutTime" BU_SG_REL_ RCIOM SG_ 826 LampCheck_rqst_ISig_6 3000;
BA_REL_ "GenSigTimeoutTime" BU_SG_REL_ RCIOM SG_ 826 LampCheck_rqst_ISig_6 180;
BA_REL_ "GenSigFirstTimeoutTime" BU_SG_REL_ APM SG_ 826 PercentClutchSlip_ISig_6 3000;
BA_REL_ "GenSigTimeoutTime" BU_SG_REL_ APM SG_ 826 PercentClutchSlip_ISig_6 180;
BA_REL_ "GenSigFirstTimeoutTime" BU_SG_REL_ FCIOM SG_ 826 ChassisInstepLight_cmd 3000;
BA_REL_ "GenSigTimeoutTime" BU_SG_REL_ FCIOM SG_ 826 ChassisInstepLight_cmd 180;
BA_REL_ "GenSigFirstTimeoutTime" BU_SG_REL_ CCIOM SG_ 826 RangeInhibit 3000;
BA_REL_ "GenSigTimeoutTime" BU_SG_REL_ CCIOM SG_ 826 RangeInhibit 180;
BA_REL_ "GenSigFirstTimeoutTime" BU_SG_REL_ APM SG_ 826 ActualDrvlnRetdrPercentTorque_IS 3000;
BA_REL_ "GenSigTimeoutTime" BU_SG_REL_ APM SG_ 826 ActualDrvlnRetdrPercentTorque_IS 180;
BA_REL_ "GenSigFirstTimeoutTime" BU_SG_REL_ RCIOM SG_ 826 ActualDrvlnRetdrPercentTorque_IS 3000;
BA_REL_ "GenSigTimeoutTime" BU_SG_REL_ RCIOM SG_ 826 ActualDrvlnRetdrPercentTorque_IS 180;
BA_REL_ "GenSigFirstTimeoutTime" BU_SG_REL_ RCIOM SG_ 826 LiftAxle1DirectControl_ISig_6 3000;
BA_REL_ "GenSigTimeoutTime" BU_SG_REL_ RCIOM SG_ 826 LiftAxle1DirectControl_ISig_6 500;
BA_REL_ "GenSigFirstTimeoutTime" BU_SG_REL_ RCIOM SG_ 826 TrailerBrakeNoEbs_stat 3000;
BA_REL_ "GenSigTimeoutTime" BU_SG_REL_ RCIOM SG_ 826 TrailerBrakeNoEbs_stat 180;
BA_REL_ "GenSigFirstTimeoutTime" BU_SG_REL_ FCIOM SG_ 826 LEDAnimation_cmd 3000;
BA_REL_ "GenSigTimeoutTime" BU_SG_REL_ FCIOM SG_ 826 LEDAnimation_cmd 180;
BA_REL_ "GenSigFirstTimeoutTime" BU_SG_REL_ CCIOM SG_ 826 DoorsAjar_stat_ISig_6 3000;
BA_REL_ "GenSigTimeoutTime" BU_SG_REL_ CCIOM SG_ 826 DoorsAjar_stat_ISig_6 180;
BA_REL_ "GenSigFirstTimeoutTime" BU_SG_REL_ APM SG_ 826 DoorsAjar_stat_ISig_6 3000;
BA_REL_ "GenSigTimeoutTime" BU_SG_REL_ APM SG_ 826 DoorsAjar_stat_ISig_6 500;
BA_REL_ "GenSigFirstTimeoutTime" BU_SG_REL_ CCIOM SG_ 826 BBSlidable5thWheelCmd 3000;
BA_REL_ "GenSigTimeoutTime" BU_SG_REL_ CCIOM SG_ 826 BBSlidable5thWheelCmd 180;
BA_REL_ "GenSigFirstTimeoutTime" BU_SG_REL_ FCIOM SG_ 826 LampCheck_cmd_ISig_6 3000;
BA_REL_ "GenSigTimeoutTime" BU_SG_REL_ FCIOM SG_ 826 LampCheck_cmd_ISig_6 180;
BA_REL_ "GenSigFirstTimeoutTime" BU_SG_REL_ CCIOM SG_ 826 BlackOutandConvoyMode_rqst_ISig_ 3000;
BA_REL_ "GenSigTimeoutTime" BU_SG_REL_ CCIOM SG_ 826 BlackOutandConvoyMode_rqst_ISig_ 180;
BA_REL_ "GenSigFirstTimeoutTime" BU_SG_REL_ RCIOM SG_ 826 BlackOutandConvoyMode_rqst_ISig_ 3000;
BA_REL_ "GenSigTimeoutTime" BU_SG_REL_ RCIOM SG_ 826 BlackOutandConvoyMode_rqst_ISig_ 180;
BA_REL_ "GenSigFirstTimeoutTime" BU_SG_REL_ CCIOM SG_ 826 AreaInhibit 3000;
BA_REL_ "GenSigTimeoutTime" BU_SG_REL_ CCIOM SG_ 826 AreaInhibit 180;
BA_REL_ "GenSigFirstTimeoutTime" BU_SG_REL_ CCIOM SG_ 826 MaintBatteryReset 3000;
BA_REL_ "GenSigTimeoutTime" BU_SG_REL_ CCIOM SG_ 826 MaintBatteryReset 180;
BA_REL_ "GenSigFirstTimeoutTime" BU_SG_REL_ RCIOM SG_ 826 ECSStandByRequest_ISig_6 3000;
BA_REL_ "GenSigTimeoutTime" BU_SG_REL_ RCIOM SG_ 826 ECSStandByRequest_ISig_6 180;
BA_REL_ "GenSigFirstTimeoutTime" BU_SG_REL_ FCIOM SG_ 826 PloughLampModeStatus_ISig_6 3000;
BA_REL_ "GenSigTimeoutTime" BU_SG_REL_ FCIOM SG_ 826 PloughLampModeStatus_ISig_6 180;
BA_REL_ "GenSigFirstTimeoutTime" BU_SG_REL_ APM SG_ 826 VIN_rqst_ISig_6 3000;
BA_REL_ "GenSigTimeoutTime" BU_SG_REL_ APM SG_ 826 VIN_rqst_ISig_6 180;
BA_REL_ "GenSigFirstTimeoutTime" BU_SG_REL_ CCIOM SG_ 826 BBContUnlockCmd 3000;
BA_REL_ "GenSigTimeoutTime" BU_SG_REL_ CCIOM SG_ 826 BBContUnlockCmd 180;
BA_REL_ "GenSigFirstTimeoutTime" BU_SG_REL_ CCIOM SG_ 826 EngineActiveStatus_ISig_6 3000;
BA_REL_ "GenSigTimeoutTime" BU_SG_REL_ CCIOM SG_ 826 EngineActiveStatus_ISig_6 180;
BA_REL_ "GenSigFirstTimeoutTime" BU_SG_REL_ CCIOM SG_ 826 BatteryCapacity_ISig_6 3000;
BA_REL_ "GenSigTimeoutTime" BU_SG_REL_ CCIOM SG_ 826 BatteryCapacity_ISig_6 180;
BA_REL_ "GenSigFirstTimeoutTime" BU_SG_REL_ APM SG_ 1369 PoweredVehicleWeight_ISig_6 12000;
BA_REL_ "GenSigTimeoutTime" BU_SG_REL_ APM SG_ 1369 PoweredVehicleWeight_ISig_6 3000;
BA_REL_ "GenSigFirstTimeoutTime" BU_SG_REL_ TPM SG_ 1369 TotalVehicleDistanceHighRes_ISig 12000;
BA_REL_ "GenSigTimeoutTime" BU_SG_REL_ TPM SG_ 1369 TotalVehicleDistanceHighRes_ISig 3000;
BA_REL_ "GenSigFirstTimeoutTime" BU_SG_REL_ RCIOM SG_ 1369 TotalVehicleDistanceHighRes_ISig 12000;
BA_REL_ "GenSigTimeoutTime" BU_SG_REL_ RCIOM SG_ 1369 TotalVehicleDistanceHighRes_ISig 3000;
BA_REL_ "GenSigFirstTimeoutTime" BU_SG_REL_ APM SG_ 1369 TotalVehicleDistanceHighRes_ISig 12000;
BA_REL_ "GenSigTimeoutTime" BU_SG_REL_ APM SG_ 1369 TotalVehicleDistanceHighRes_ISig 3000;
BA_REL_ "GenSigFirstTimeoutTime" BU_SG_REL_ BPMU SG_ 1369 TotalVehicleDistanceHighRes_ISig 12000;
BA_REL_ "GenSigTimeoutTime" BU_SG_REL_ BPMU SG_ 1369 TotalVehicleDistanceHighRes_ISig 3000;
BA_REL_ "GenSigFirstTimeoutTime" BU_SG_REL_ EAS SG_ 1369 TotalVehicleDistanceHighRes_ISig 12000;
BA_REL_ "GenSigTimeoutTime" BU_SG_REL_ EAS SG_ 1369 TotalVehicleDistanceHighRes_ISig 3000;
BA_REL_ "GenSigFirstTimeoutTime" BU_SG_REL_ FAS SG_ 1369 TotalVehicleDistanceHighRes_ISig 12000;
BA_REL_ "GenSigTimeoutTime" BU_SG_REL_ FAS SG_ 1369 TotalVehicleDistanceHighRes_ISig 3000;
BA_REL_ "GenSigFirstTimeoutTime" BU_SG_REL_ FCIOM SG_ 1369 TotalVehicleDistanceHighRes_ISig 12000;
BA_REL_ "GenSigTimeoutTime" BU_SG_REL_ FCIOM SG_ 1369 TotalVehicleDistanceHighRes_ISig 3000;
BA_REL_ "GenSigFirstTimeoutTime" BU_SG_REL_ CCIOM SG_ 1369 TotalVehicleDistanceHighRes_ISig 12000;
BA_REL_ "GenSigTimeoutTime" BU_SG_REL_ CCIOM SG_ 1369 TotalVehicleDistanceHighRes_ISig 3000;
BA_REL_ "GenSigFirstTimeoutTime" BU_SG_REL_ APM SG_ 1369 GrossCombinationVehicleWeight_IS 12000;
BA_REL_ "GenSigTimeoutTime" BU_SG_REL_ APM SG_ 1369 GrossCombinationVehicleWeight_IS 3000;
BA_REL_ "GenSigFirstTimeoutTime" BU_SG_REL_ RCIOM SG_ 946 TransferCaseOrSplitboxPTOMode_IS 3000;
BA_REL_ "GenSigTimeoutTime" BU_SG_REL_ RCIOM SG_ 946 TransferCaseOrSplitboxPTOMode_IS 300;
BA_REL_ "GenSigFirstTimeoutTime" BU_SG_REL_ APM SG_ 946 EPBHillHolderMode_ISig_6 3000;
BA_REL_ "GenSigTimeoutTime" BU_SG_REL_ APM SG_ 946 EPBHillHolderMode_ISig_6 300;
BA_REL_ "GenSigFirstTimeoutTime" BU_SG_REL_ RCIOM SG_ 946 VehicleDistanceRollingCounter 3000;
BA_REL_ "GenSigTimeoutTime" BU_SG_REL_ RCIOM SG_ 946 VehicleDistanceRollingCounter 300;
BA_REL_ "GenSigFirstTimeoutTime" BU_SG_REL_ EBS SG_ 946 VehicleDistanceRollingCounter 3000;
BA_REL_ "GenSigTimeoutTime" BU_SG_REL_ EBS SG_ 946 VehicleDistanceRollingCounter 300;
BA_REL_ "GenSigFirstTimeoutTime" BU_SG_REL_ RCIOM SG_ 946 Pto4Status_ISig_6 3000;
BA_REL_ "GenSigTimeoutTime" BU_SG_REL_ RCIOM SG_ 946 Pto4Status_ISig_6 300;
BA_REL_ "GenSigFirstTimeoutTime" BU_SG_REL_ CCIOM SG_ 946 CartridgeChangedDrvrReset_rqst 3000;
BA_REL_ "GenSigTimeoutTime" BU_SG_REL_ CCIOM SG_ 946 CartridgeChangedDrvrReset_rqst 300;
BA_REL_ "GenSigFirstTimeoutTime" BU_SG_REL_ APM SG_ 946 CartridgeChangedDrvrReset_rqst 3000;
BA_REL_ "GenSigTimeoutTime" BU_SG_REL_ APM SG_ 946 CartridgeChangedDrvrReset_rqst 300;
BA_REL_ "GenSigFirstTimeoutTime" BU_SG_REL_ RCIOM SG_ 946 Pto2Status_ISig_6 3000;
BA_REL_ "GenSigTimeoutTime" BU_SG_REL_ RCIOM SG_ 946 Pto2Status_ISig_6 300;
BA_REL_ "GenSigFirstTimeoutTime" BU_SG_REL_ APM SG_ 946 AcceleratorPedalQuality_ISig_6 3000;
BA_REL_ "GenSigTimeoutTime" BU_SG_REL_ APM SG_ 946 AcceleratorPedalQuality_ISig_6 300;
BA_REL_ "GenSigFirstTimeoutTime" BU_SG_REL_ CCIOM SG_ 946 Pto2DrivingRequest 3000;
BA_REL_ "GenSigTimeoutTime" BU_SG_REL_ CCIOM SG_ 946 Pto2DrivingRequest 300;
BA_REL_ "GenSigFirstTimeoutTime" BU_SG_REL_ RCIOM SG_ 946 Pto3Status_ISig_6 3000;
BA_REL_ "GenSigTimeoutTime" BU_SG_REL_ RCIOM SG_ 946 Pto3Status_ISig_6 300;
BA_REL_ "GenSigFirstTimeoutTime" BU_SG_REL_ CCIOM SG_ 946 ReducedLoadMode_stat_ISig_6 3000;
BA_REL_ "GenSigTimeoutTime" BU_SG_REL_ CCIOM SG_ 946 ReducedLoadMode_stat_ISig_6 300;
BA_REL_ "GenSigFirstTimeoutTime" BU_SG_REL_ RCIOM SG_ 946 RearAxleDiffLockActvnDrvrReq_ISi 3000;
BA_REL_ "GenSigTimeoutTime" BU_SG_REL_ RCIOM SG_ 946 RearAxleDiffLockActvnDrvrReq_ISi 500;
BA_REL_ "GenSigFirstTimeoutTime" BU_SG_REL_ RCIOM SG_ 946 RrInterAxlDiffLockActvnFuncReq 3000;
BA_REL_ "GenSigTimeoutTime" BU_SG_REL_ RCIOM SG_ 946 RrInterAxlDiffLockActvnFuncReq 300;
BA_REL_ "GenSigFirstTimeoutTime" BU_SG_REL_ CCIOM SG_ 946 Pto1DrivingRequest 3000;
BA_REL_ "GenSigTimeoutTime" BU_SG_REL_ CCIOM SG_ 946 Pto1DrivingRequest 300;
BA_REL_ "GenSigFirstTimeoutTime" BU_SG_REL_ APM SG_ 946 EngineStopRequest_ISig_6 3000;
BA_REL_ "GenSigTimeoutTime" BU_SG_REL_ APM SG_ 946 EngineStopRequest_ISig_6 300;
BA_REL_ "GenSigFirstTimeoutTime" BU_SG_REL_ APM SG_ 946 AcceleratorPedalStatus_ISig_6 3000;
BA_REL_ "GenSigTimeoutTime" BU_SG_REL_ APM SG_ 946 AcceleratorPedalStatus_ISig_6 300;
BA_REL_ "GenSigFirstTimeoutTime" BU_SG_REL_ APM SG_ 946 XBRActiveControlMode_ISig_6 3000;
BA_REL_ "GenSigTimeoutTime" BU_SG_REL_ APM SG_ 946 XBRActiveControlMode_ISig_6 300;
BA_REL_ "GenSigFirstTimeoutTime" BU_SG_REL_ RCIOM SG_ 946 RearAxleDiffLockActvnFuncReq_ISi 3000;
BA_REL_ "GenSigTimeoutTime" BU_SG_REL_ RCIOM SG_ 946 RearAxleDiffLockActvnFuncReq_ISi 500;
BA_REL_ "GenSigFirstTimeoutTime" BU_SG_REL_ RCIOM SG_ 946 RrInterAxlDiffLockActvnDrvrReq_I 3000;
BA_REL_ "GenSigTimeoutTime" BU_SG_REL_ RCIOM SG_ 946 RrInterAxlDiffLockActvnDrvrReq_I 500;
BA_REL_ "GenSigFirstTimeoutTime" BU_SG_REL_ APM SG_ 946 KeyPosition_ISig_6 3000;
BA_REL_ "GenSigTimeoutTime" BU_SG_REL_ APM SG_ 946 KeyPosition_ISig_6 300;
BA_REL_ "GenSigFirstTimeoutTime" BU_SG_REL_ RCIOM SG_ 946 Pto1Status_ISig_6 3000;
BA_REL_ "GenSigTimeoutTime" BU_SG_REL_ RCIOM SG_ 946 Pto1Status_ISig_6 300;
BA_REL_ "GenSigFirstTimeoutTime" BU_SG_REL_ RCIOM SG_ 945 ActualEnginePercentTorque_ISig_6 3000;
BA_REL_ "GenSigTimeoutTime" BU_SG_REL_ RCIOM SG_ 945 ActualEnginePercentTorque_ISig_6 500;
BA_REL_ "GenSigFirstTimeoutTime" BU_SG_REL_ APM SG_ 945 ActualEnginePercentTorque_ISig_6 3000;
BA_REL_ "GenSigTimeoutTime" BU_SG_REL_ APM SG_ 945 ActualEnginePercentTorque_ISig_6 500;
BA_REL_ "GenSigFirstTimeoutTime" BU_SG_REL_ FAS SG_ 945 ActualEnginePercentTorque_ISig_6 3000;
BA_REL_ "GenSigTimeoutTime" BU_SG_REL_ FAS SG_ 945 ActualEnginePercentTorque_ISig_6 500;
BA_REL_ "GenSigFirstTimeoutTime" BU_SG_REL_ CCIOM SG_ 945 ActualEnginePercentTorque_ISig_6 3000;
BA_REL_ "GenSigTimeoutTime" BU_SG_REL_ CCIOM SG_ 945 ActualEnginePercentTorque_ISig_6 300;
BA_REL_ "GenSigFirstTimeoutTime" BU_SG_REL_ CCIOM SG_ 945 EcoRollActiveStatus_ISig_6 3000;
BA_REL_ "GenSigTimeoutTime" BU_SG_REL_ CCIOM SG_ 945 EcoRollActiveStatus_ISig_6 300;
BA_REL_ "GenSigFirstTimeoutTime" BU_SG_REL_ CCIOM SG_ 945 WheelBasedVehicleSpeed_ISig_6 3000;
BA_REL_ "GenSigTimeoutTime" BU_SG_REL_ CCIOM SG_ 945 WheelBasedVehicleSpeed_ISig_6 300;
BA_REL_ "GenSigFirstTimeoutTime" BU_SG_REL_ FAS SG_ 945 WheelBasedVehicleSpeed_ISig_6 3000;
BA_REL_ "GenSigTimeoutTime" BU_SG_REL_ FAS SG_ 945 WheelBasedVehicleSpeed_ISig_6 300;
BA_REL_ "GenSigFirstTimeoutTime" BU_SG_REL_ TPM SG_ 945 WheelBasedVehicleSpeed_ISig_6 3000;
BA_REL_ "GenSigTimeoutTime" BU_SG_REL_ TPM SG_ 945 WheelBasedVehicleSpeed_ISig_6 300;
BA_REL_ "GenSigFirstTimeoutTime" BU_SG_REL_ EAS SG_ 945 WheelBasedVehicleSpeed_ISig_6 3000;
BA_REL_ "GenSigTimeoutTime" BU_SG_REL_ EAS SG_ 945 WheelBasedVehicleSpeed_ISig_6 300;
BA_REL_ "GenSigFirstTimeoutTime" BU_SG_REL_ RCIOM SG_ 945 WheelBasedVehicleSpeed_ISig_6 3000;
BA_REL_ "GenSigTimeoutTime" BU_SG_REL_ RCIOM SG_ 945 WheelBasedVehicleSpeed_ISig_6 300;
BA_REL_ "GenSigFirstTimeoutTime" BU_SG_REL_ APM SG_ 945 WheelBasedVehicleSpeed_ISig_6 3000;
BA_REL_ "GenSigTimeoutTime" BU_SG_REL_ APM SG_ 945 WheelBasedVehicleSpeed_ISig_6 300;
BA_REL_ "GenSigFirstTimeoutTime" BU_SG_REL_ APM SG_ 945 NominalFrictionPercentTorque_ISi 3000;
BA_REL_ "GenSigTimeoutTime" BU_SG_REL_ APM SG_ 945 NominalFrictionPercentTorque_ISi 500;
BA_REL_ "GenSigFirstTimeoutTime" BU_SG_REL_ RCIOM SG_ 945 ActualEngineRetarderPercentTrq_I 3000;
BA_REL_ "GenSigTimeoutTime" BU_SG_REL_ RCIOM SG_ 945 ActualEngineRetarderPercentTrq_I 300;
BA_REL_ "GenSigFirstTimeoutTime" BU_SG_REL_ FAS SG_ 945 EngineReferenceTorque_ISig_6 65000;
BA_REL_ "GenSigTimeoutTime" BU_SG_REL_ FAS SG_ 945 EngineReferenceTorque_ISig_6 30000;
BA_REL_ "GenSigFirstTimeoutTime" BU_SG_REL_ EAS SG_ 945 RearAxleSteeringFunctionDsbl_ISi 3000;
BA_REL_ "GenSigTimeoutTime" BU_SG_REL_ EAS SG_ 945 RearAxleSteeringFunctionDsbl_ISi 300;
VAL_ 1363 FasUsrDefinedStorage_rqst_ISig_6 3 "FasUsrDefinedStorage_NotAvailable" 2 "FasUsrDefinedStorage_Error" 1 "FasUsrDefinedStorage_StoreUserDefinedSetting" 0 "FasUsrDefinedStorage_DoNotStoreUserDefinedSetting" ;
VAL_ 1363 DriverMemory_rqst_ISig_6 31 "DriverMemory_rqst_Error" 30 "DriverMemory_rqst_NotAvailable" 29 "DriverMemory_rqst_Spare_07" 28 "DriverMemory_rqst_Spare_06" 27 "DriverMemory_rqst_Spare_05" 26 "DriverMemory_rqst_Spare_04" 25 "DriverMemory_rqst_Spare_03" 24 "DriverMemory_rqst_Spare_02" 23 "DriverMemory_rqst_Spare_01" 22 "DriverMemory_rqst_Spare" 21 "DriverMemory_rqst_ResetAllMemThenUseDefDriverMem" 20 "DriverMemory_rqst_ResetAndThenUseDriverMemory10" 19 "DriverMemory_rqst_ResetAndThenUseDriverMemory9" 18 "DriverMemory_rqst_ResetAndThenUseDriverMemory8" 17 "DriverMemory_rqst_ResetAndThenUseDriverMemory7" 16 "DriverMemory_rqst_ResetAndThenUseDriverMemory6" 15 "DriverMemory_rqst_ResetAndThenUseDriverMemory5" 14 "DriverMemory_rqst_ResetAndThenUseDriverMemory4" 13 "DriverMemory_rqst_ResetAndThenUseDriverMemory3" 12 "DriverMemory_rqst_ResetAndThenUseDriverMemory2" 11 "DriverMemory_rqst_ResetAndThenUseDriverMemory1" 10 "DriverMemory_rqst_UseDriverMemory10" 9 "DriverMemory_rqst_UseDriverMemory9" 8 "DriverMemory_rqst_UseDriverMemory8" 7 "DriverMemory_rqst_UseDriverMemory7" 6 "DriverMemory_rqst_UseDriverMemory6" 5 "DriverMemory_rqst_UseDriverMemory5" 4 "DriverMemory_rqst_UseDriverMemory4" 3 "DriverMemory_rqst_UseDriverMemory3" 2 "DriverMemory_rqst_UseDriverMemory2" 1 "DriverMemory_rqst_UseDriverMemory1" 0 "DriverMemory_rqst_UseDefaultDriverMemory" ;
VAL_ 1363 PredeliveryModeIndication_cmd_IS 3 "DeactivateActivate_NotAvailable" 2 "DeactivateActivate_Error" 1 "DeactivateActivate_Activate" 0 "DeactivateActivate_Deactivate" ;
VAL_ 1363 FasPersonalSettingsButton_rqst_I 7 "FasPersSettingsButton_NotAvailable" 6 "FasPersSettingsButton_Error" 5 "FasPersSettingsButton_Spare" 4 "FasPersSettingsButton_UserDefinedButton" 3 "FasPersSettingsButton_PresetButtonHeavy" 2 "FasPersSettingsButton_PresetButtonFirm" 1 "FasPersSettingsButton_PresetButtonLight" 0 "FasPersSettingsButton_PresetButtonDefault" ;
VAL_ 1363 FasDriver_rqst_ISig_6 15 "FasDriver_NotAvailable" 14 "FasDriver_Error" 13 "FasDriver_Spare3" 12 "FasDriver_Spare2" 11 "FasDriver_Spare1" 10 "FasDriver_Driver10" 9 "FasDriver_Driver9" 8 "FasDriver_Driver8" 7 "FasDriver_Driver7" 6 "FasDriver_Driver6" 5 "FasDriver_Driver5" 4 "FasDriver_Driver4" 3 "FasDriver_Driver3" 2 "FasDriver_Driver2" 1 "FasDriver_Driver1" 0 "FasDriver_DefaultDriver" ;
VAL_ 536 FASHapticFeedbackRequest_ISig_6 15 "FASHapticFeedbackRequest_NotAvailable" 14 "FASHapticFeedbackRequest_Error" 13 "FASHapticFeedbackRequest_Spare3" 12 "FASHapticFeedbackRequest_Spare2" 11 "FASHapticFeedbackRequest_Spare1" 10 "FASHapticFeedbackRequest_PredefinedFreqAndAmpl10" 9 "FASHapticFeedbackRequest_PredefinedFreqAndAmpl9" 8 "FASHapticFeedbackRequest_PredefinedFreqAndAmpl8" 7 "FASHapticFeedbackRequest_PredefinedFreqAndAmpl7" 6 "FASHapticFeedbackRequest_PredefinedFreqAndAmpl6" 5 "FASHapticFeedbackRequest_PredefinedFreqAndAmpl5" 4 "FASHapticFeedbackRequest_PredefinedFreqAndAmpl4" 3 "FASHapticFeedbackRequest_PredefinedFreqAndAmpl3" 2 "FASHapticFeedbackRequest_PredefinedFreqAndAmpl2" 1 "FASHapticFeedbackRequest_PredefinedFreqAndAmpl1" 0 "FASHapticFeedbackRequest_NoHapticFeedback" ;
VAL_ 535 DirectionIndicatorLightsStatus 15 "DirectionIndicatorLightsStatus_NotAvailable" 14 "DirectionIndicatorLightsStatus_Error" 13 "DirectionIndicatorLightsStatus_Spare7" 12 "DirectionIndicatorLightsStatus_Spare6" 11 "DirectionIndicatorLightsStatus_Spare5" 10 "DirectionIndicatorLightsStatus_Spare4" 9 "DirectionIndicatorLightsStatus_Spare3" 8 "DirectionIndicatorLightsStatus_Spare2" 7 "DirectionIndicatorLightsStatus_Spare1" 6 "DirectionIndicatorLightsStatus_ActiveOtherIndication" 5 "DirectionIndicatorLightsStatus_ActiveHazard" 4 "DirectionIndicatorLightsStatus_ActiveRightAndHazard" 3 "DirectionIndicatorLightsStatus_ActiveLeftAndHazard" 2 "DirectionIndicatorLightsStatus_ActiveRight" 1 "DirectionIndicatorLightsStatus_ActiveLeft" 0 "DirectionIndicatorLightsStatus_NotActive" ;
VAL_ 535 ExhManif_AirInjActive_ISig_6 3 "InhibitedStatus_NotAvailable" 2 "InhibitedStatus_Error" 1 "InhibitedStatus_Inhibited" 0 "InhibitedStatus_NotInhibited" ;
VAL_ 535 ExtendedTrailerBrakeValveReq 3 "DeactivateActivateSpare_NotAvailable" 2 "DeactivateActivateSpare_Spare" 1 "DeactivateActivateSpare_Activate" 0 "DeactivateActivateSpare_Deactivate" ;
VAL_ 1381 StartBatteryReset_rqst 3 "Request_NotAvailable" 2 "Request_Error" 1 "Request_RequestActive" 0 "Request_NotRequested" ;
VAL_ 1381 StartBatteryCapacity 15 "StartBatteryCapacity_NotAvailable" 14 "StartBatteryCapacity_Error" 13 "StartBatteryCapacity_NoselectionMade" 12 "StartBatteryCapacity_Other" 11 "StartBatteryCapacity_Capacity11" 10 "StartBatteryCapacity_Capacity10" 9 "StartBatteryCapacity_Capacity9" 8 "StartBatteryCapacity_Capacity8" 7 "StartBatteryCapacity_Capacity7" 6 "StartBatteryCapacity_Capacity6" 5 "StartBatteryCapacity_Capacity5" 4 "StartBatteryCapacity_Capacity4" 3 "StartBatteryCapacity_Capacity3" 2 "StartBatteryCapacity_Capacity2" 1 "StartBatteryCapacity_Capacity1" 0 "StartBatteryCapacity_Capacity0" ;
VAL_ 519 AdaptiveMainBeamLeft_cmd_ISig_6 7 "AdaptiveMainBeam_cmd_NotAvailable" 6 "AdaptiveMainBeam_cmd_Error" 5 "AdaptiveMainBeam_cmd_Spare3" 4 "AdaptiveMainBeam_cmd_Spare2" 3 "AdaptiveMainBeam_cmd_Spare1" 2 "AdaptiveMainBeam_cmd_GlareFreeAllowed" 1 "AdaptiveMainBeam_cmd_MainBeamAllowed" 0 "AdaptiveMainBeam_cmd_MainBeamNotAllowed" ;
VAL_ 519 AdaptiveMainBeamRight_cmd_ISig_6 7 "AdaptiveMainBeam_cmd_NotAvailable" 6 "AdaptiveMainBeam_cmd_Error" 5 "AdaptiveMainBeam_cmd_Spare3" 4 "AdaptiveMainBeam_cmd_Spare2" 3 "AdaptiveMainBeam_cmd_Spare1" 2 "AdaptiveMainBeam_cmd_GlareFreeAllowed" 1 "AdaptiveMainBeam_cmd_MainBeamAllowed" 0 "AdaptiveMainBeam_cmd_MainBeamNotAllowed" ;
VAL_ 1370 TPMSetAxleTireConfig_Axle2_ISig_ 7 "TPMAxleConfig_NotAvailable" 6 "TPMAxleConfig_Error" 5 "TPMAxleConfig_Spare" 4 "TPMAxleConfig_RearAxleWith4Tires" 3 "TPMAxleConfig_RearAxleWith2Tires" 2 "TPMAxleConfig_FrontAxleWith4Tires" 1 "TPMAxleConfig_FrontAxleWith2Tires" 0 "TPMAxleConfig_NotPresent" ;
VAL_ 1370 TPMSetPresThresCfg_AxleNr_ISig_6 7 "TPMAxleNr_NotAvailable" 6 "TPMAxleNr_Error" 5 "TPMAxleNr_Axle5" 4 "TPMAxleNr_Axle4" 3 "TPMAxleNr_Axle3" 2 "TPMAxleNr_Axle2" 1 "TPMAxleNr_Axle1" 0 "TPMAxleNr_NoRequest" ;
VAL_ 1370 TPMSetPresThresCfg_VehiclePos_IS 7 "TPMVehiclePos_NotAvailable" 6 "TPMVehiclePos_Error" 5 "TPMVehiclePos_Trailer5Vehicle" 4 "TPMVehiclePos_Trailer4Vehicle" 3 "TPMVehiclePos_Trailer3Vehicle" 2 "TPMVehiclePos_Trailer2Vehicle" 1 "TPMVehiclePos_Trailer1Vehicle" 0 "TPMVehiclePos_TruckVehicle" ;
VAL_ 1370 TPMSetAxleTireConfig_Axle4_ISig_ 7 "TPMAxleConfig_NotAvailable" 6 "TPMAxleConfig_Error" 5 "TPMAxleConfig_Spare" 4 "TPMAxleConfig_RearAxleWith4Tires" 3 "TPMAxleConfig_RearAxleWith2Tires" 2 "TPMAxleConfig_FrontAxleWith4Tires" 1 "TPMAxleConfig_FrontAxleWith2Tires" 0 "TPMAxleConfig_NotPresent" ;
VAL_ 1370 TPMSetAxleTireConfig_Axle1_ISig_ 7 "TPMAxleConfig_NotAvailable" 6 "TPMAxleConfig_Error" 5 "TPMAxleConfig_Spare" 4 "TPMAxleConfig_RearAxleWith4Tires" 3 "TPMAxleConfig_RearAxleWith2Tires" 2 "TPMAxleConfig_FrontAxleWith4Tires" 1 "TPMAxleConfig_FrontAxleWith2Tires" 0 "TPMAxleConfig_NotPresent" ;
VAL_ 1370 TPMSetAxleTireConfig_Axle5_ISig_ 7 "TPMAxleConfig_NotAvailable" 6 "TPMAxleConfig_Error" 5 "TPMAxleConfig_Spare" 4 "TPMAxleConfig_RearAxleWith4Tires" 3 "TPMAxleConfig_RearAxleWith2Tires" 2 "TPMAxleConfig_FrontAxleWith4Tires" 1 "TPMAxleConfig_FrontAxleWith2Tires" 0 "TPMAxleConfig_NotPresent" ;
VAL_ 1370 TPMSetAxleTireConfig_VehiclePos_ 7 "TPMVehiclePos_NotAvailable" 6 "TPMVehiclePos_Error" 5 "TPMVehiclePos_Trailer5Vehicle" 4 "TPMVehiclePos_Trailer4Vehicle" 3 "TPMVehiclePos_Trailer3Vehicle" 2 "TPMVehiclePos_Trailer2Vehicle" 1 "TPMVehiclePos_Trailer1Vehicle" 0 "TPMVehiclePos_TruckVehicle" ;
VAL_ 1370 TPMSetAxleTireConfig_Axle3_ISig_ 7 "TPMAxleConfig_NotAvailable" 6 "TPMAxleConfig_Error" 5 "TPMAxleConfig_Spare" 4 "TPMAxleConfig_RearAxleWith4Tires" 3 "TPMAxleConfig_RearAxleWith2Tires" 2 "TPMAxleConfig_FrontAxleWith4Tires" 1 "TPMAxleConfig_FrontAxleWith2Tires" 0 "TPMAxleConfig_NotPresent" ;
VAL_ 1373 TPMMateTrailerReq_ISig_6 3 "Request_NotAvailable" 2 "Request_Error" 1 "Request_RequestActive" 0 "Request_NotRequested" ;
VAL_ 1373 TPMPosOfWMReq_VehiclePos_ISig_6 7 "TPMVehiclePos_NotAvailable" 6 "TPMVehiclePos_Error" 5 "TPMVehiclePos_Trailer5Vehicle" 4 "TPMVehiclePos_Trailer4Vehicle" 3 "TPMVehiclePos_Trailer3Vehicle" 2 "TPMVehiclePos_Trailer2Vehicle" 1 "TPMVehiclePos_Trailer1Vehicle" 0 "TPMVehiclePos_TruckVehicle" ;
VAL_ 1373 TPMSetAxleRefPres_VehiclePos_ISi 7 "TPMVehiclePos_NotAvailable" 6 "TPMVehiclePos_Error" 5 "TPMVehiclePos_Trailer5Vehicle" 4 "TPMVehiclePos_Trailer4Vehicle" 3 "TPMVehiclePos_Trailer3Vehicle" 2 "TPMVehiclePos_Trailer2Vehicle" 1 "TPMVehiclePos_Trailer1Vehicle" 0 "TPMVehiclePos_TruckVehicle" ;
VAL_ 1373 TPMUnmateTrailerReq_ISig_6 3 "Request_NotAvailable" 2 "Request_Error" 1 "Request_RequestActive" 0 "Request_NotRequested" ;
VAL_ 1249 TransferCasePTOEngaged_ISig_6 3 "NotEngagedEngaged_NotAvailable" 2 "NotEngagedEngaged_Error" 1 "NotEngagedEngaged_Engaged" 0 "NotEngagedEngaged_NotEngaged" ;
VAL_ 1249 ABSFullyOperational_ISig_6 3 "FullyOperational_NotAvailable" 2 "FullyOperational_Reserved" 1 "FullyOperational_FullyOperational" 0 "FullyOperational_NotFullyOperational" ;
VAL_ 1249 ExtECSRequestPressureUpdate 3 "Request_NotAvailable" 2 "Request_Error" 1 "Request_RequestActive" 0 "Request_NotRequested" ;
VAL_ 1249 HeadLampFanControl_rqst 3 "InactiveActive_NotAvailable" 2 "InactiveActive_Error" 1 "InactiveActive_Active" 0 "InactiveActive_Inactive" ;
VAL_ 1249 ContTrailerBrake_Request 7 "ContTrailerBrake_rqst_NotAvailable" 6 "ContTrailerBrake_rqst_Error" 5 "ContTrailerBrake_rqst_Spare_01" 4 "ContTrailerBrake_rqst_Spare" 3 "ContTrailerBrake_rqst_Decrease" 2 "ContTrailerBrake_rqst_Increase" 1 "ContTrailerBrake_rqst_Activate" 0 "ContTrailerBrake_rqst_Deactivate" ;
VAL_ 1249 ACC_SGO_Status_ISig_6 15 "ACC_SGO_Status_NotAvailable" 14 "ACC_SGO_Status_Error" 13 "ACC_SGO_Status_Spare7" 12 "ACC_SGO_Status_Spare6" 11 "ACC_SGO_Status_Spare5" 10 "ACC_SGO_Status_Spare4" 9 "ACC_SGO_Status_Spare3" 8 "ACC_SGO_Status_Spare2" 7 "ACC_SGO_Status_Spare1" 6 "ACC_SGO_Status_ACC_SGO_Active_TakeOffRequest" 5 "ACC_SGO_Status_ACC_SGO_Active_Hold" 4 "ACC_SGO_Status_ACC_SGO_Active_Stationary" 3 "ACC_SGO_Status_ACC_SGO_Stopping" 2 "ACC_SGO_Status_ACC_SGO_Active_Driving" 1 "ACC_SGO_Status_ACC_SGO_Inactive" 0 "ACC_SGO_Status_ACC_SGO_OFF" ;
VAL_ 1249 ClutchSwitch2Stat 3 "ClutchSwitch_NotAvailable" 2 "ClutchSwitch_Error" 1 "ClutchSwitch_ClutchPedalDepressed" 0 "ClutchSwitch_ClutchPedalReleased" ;
VAL_ 1249 FrAxle2WheelDriveRequest 3 "DisengageEngage_NotAvailable" 2 "DisengageEngage_Error" 1 "DisengageEngage_Engage" 0 "DisengageEngage_Disengage" ;
VAL_ 1249 SideMarkersLights_cmd 7 "SideMarkersLights_cmd_NotAvailable" 6 "SideMarkersLights_cmd_Error" 5 "SideMarkersLights_cmd_Spare2" 4 "SideMarkersLights_cmd_Spare1" 3 "SideMarkersLights_cmd_LeftandRightSideMarkersActive" 2 "SideMarkersLights_cmd_RightSideMarkersActive" 1 "SideMarkersLights_cmd_LeftSideMarkersActive" 0 "SideMarkersLights_cmd_Inactive" ;
VAL_ 1249 LivBatteryChargingStat_rqst 3 "NotRequested_NotAvailable" 2 "NotRequested_Error" 1 "NotRequested_Requested" 0 "NotRequested_NotRequested" ;
VAL_ 1338 TransmEngineCrankEnable2_ISig_6 3 "DisableEnable_NotAvailable" 2 "DisableEnable_Error" 1 "DisableEnable_Enable" 0 "DisableEnable_Disable" ;
VAL_ 1338 TransmEngineCrankEnable_ISig_6 3 "DisableEnable_NotAvailable" 2 "DisableEnable_Error" 1 "DisableEnable_Enable" 0 "DisableEnable_Disable" ;
VAL_ 944 LoadDistributionRequested_ISig_6 15 "LoadDistributionRequested_NotAvailable" 14 "LoadDistributionRequested_Error" 13 "LoadDistributionRequested_Reserved5" 12 "LoadDistributionRequested_Reserved4" 11 "LoadDistributionRequested_Reserved3" 10 "LoadDistributionRequested_Reserved2" 9 "LoadDistributionRequested_Reserved1" 8 "LoadDistributionRequested_DelpressLoadDistribution" 7 "LoadDistributionRequested_VariableLoadDistribution" 6 "LoadDistributionRequested_AlternativeLoadDistribution" 5 "LoadDistributionRequested_MaximumTraction2" 4 "LoadDistributionRequested_MaximumTraction1" 3 "LoadDistributionRequested_OptimizedTraction" 2 "LoadDistributionRequested_NormalLoadDistribution" 1 "LoadDistributionRequested_DefaultLoadDistribution" 0 "LoadDistributionRequested_NoAction" ;
VAL_ 944 ShortStopHeater_cmd_ISig_6 3 "Request_NotAvailable" 2 "Request_Error" 1 "Request_RequestActive" 0 "Request_NotRequested" ;
VAL_ 944 PBReleaseInhibit_rqst 3 "Request_NotAvailable" 2 "Request_Error" 1 "Request_RequestActive" 0 "Request_NotRequested" ;
VAL_ 944 SWEngineStop_rqst_ISig_6 7 "SWEngineStop_rqst_NotAvailable" 6 "SWEngineStop_rqst_Error" 5 "SWEngineStop_rqst_Spare_04" 4 "SWEngineStop_rqst_Spare_03" 3 "SWEngineStop_rqst_Spare_02" 2 "SWEngineStop_rqst_Spare_01" 1 "SWEngineStop_rqst_EngineStopRequested" 0 "SWEngineStop_rqst_EngineStopNotRequested" ;
VAL_ 390 CityHorn_cmd_ISig_6 3 "OffOn_NotAvailable" 2 "OffOn_Error" 1 "OffOn_On" 0 "OffOn_Off" ;
VAL_ 390 LevelRequest_RollRequest_ISig_6 7 "RollRequest_NotAvailable" 6 "RollRequest_Error" 5 "RollRequest_Reserved" 4 "RollRequest_CounterClockwiseShort" 3 "RollRequest_ClockwiseShort" 2 "RollRequest_CounterClockwise" 1 "RollRequest_Clockwise" 0 "RollRequest_Idle" ;
VAL_ 390 ClutchSwitch_ISig_6 3 "ClutchSwitch_NotAvailable" 2 "ClutchSwitch_Error" 1 "ClutchSwitch_ClutchPedalDepressed" 0 "ClutchSwitch_ClutchPedalReleased" ;
VAL_ 390 AuxiliaryHorn_cmd_ISig_6 3 "OffOn_NotAvailable" 2 "OffOn_Error" 1 "OffOn_On" 0 "OffOn_Off" ;
VAL_ 390 LevelRequest_RearAxle_ISig_6 7 "LevelChangeRequest_NotAvailable" 6 "LevelChangeRequest_ErrorIndicator" 5 "LevelChangeRequest_NotDefined" 4 "LevelChangeRequest_VehicleBodyDownMinimumMovementLowering" 3 "LevelChangeRequest_VehicleBodyUpMinimumMovementLifting" 2 "LevelChangeRequest_VehicleBodyDownLowering" 1 "LevelChangeRequest_VehicleBodyUpLifting" 0 "LevelChangeRequest_TakeNoAction" ;
VAL_ 390 BrakeSwitch_ISig_6 3 "BrakeSwitch_NotAvailable" 2 "BrakeSwitch_Error" 1 "BrakeSwitch_BrakePedalDepressed" 0 "BrakeSwitch_BrakePedalReleased" ;
VAL_ 390 FPBRChangeReq_ISig_6 3 "FPBRChangeReq_NotAvailable" 2 "FPBRChangeReq_Error" 1 "FPBRChangeReq_ChangeFPBRFunction" 0 "FPBRChangeReq_TakeNoAction" ;
VAL_ 390 LevelRequest_FrontAxle_ISig_6 7 "LevelChangeRequest_NotAvailable" 6 "LevelChangeRequest_ErrorIndicator" 5 "LevelChangeRequest_NotDefined" 4 "LevelChangeRequest_VehicleBodyDownMinimumMovementLowering" 3 "LevelChangeRequest_VehicleBodyUpMinimumMovementLifting" 2 "LevelChangeRequest_VehicleBodyDownLowering" 1 "LevelChangeRequest_VehicleBodyUpLifting" 0 "LevelChangeRequest_TakeNoAction" ;
VAL_ 389 FrontWheelDriveRequest 3 "DisengageEngage_NotAvailable" 2 "DisengageEngage_Error" 1 "DisengageEngage_Engage" 0 "DisengageEngage_Disengage" ;
VAL_ 389 KneelingChangeRequest_ISig_6 3 "KneelingChangeRequest_NotAvailable" 2 "KneelingChangeRequest_Error" 1 "KneelingChangeRequest_ChangeKneelFunction" 0 "KneelingChangeRequest_TakeNoAction" ;
VAL_ 826 LampCheck_rqst_ISig_6 3 "LampCheck_NotAvailable" 2 "LampCheck_Error" 1 "LampCheck_PerformLampCheck" 0 "LampCheck_NoAction" ;
VAL_ 826 ChassisInstepLight_cmd 3 "OffOn_NotAvailable" 2 "OffOn_Error" 1 "OffOn_On" 0 "OffOn_Off" ;
VAL_ 826 RangeInhibit 3 "Inhibit_NotAvailable" 2 "Inhibit_Error" 1 "Inhibit_InhibitActive" 0 "Inhibit_NoInhibit" ;
VAL_ 826 LiftAxle1DirectControl_ISig_6 7 "LiftAxleLiftPositionRequest_NotAvailable" 6 "LiftAxleLiftPositionRequest_Error" 5 "LiftAxleLiftPositionRequest_Reserved_02" 4 "LiftAxleLiftPositionRequest_Reserved_01" 3 "LiftAxleLiftPositionRequest_Reserved" 2 "LiftAxleLiftPositionRequest_Up" 1 "LiftAxleLiftPositionRequest_Down" 0 "LiftAxleLiftPositionRequest_Idle" ;
VAL_ 826 TrailerBrakeNoEbs_stat 3 "InactiveActive_NotAvailable" 2 "InactiveActive_Error" 1 "InactiveActive_Active" 0 "InactiveActive_Inactive" ;
VAL_ 826 LEDAnimation_cmd 7 "LEDAnimation_cmd_NotAvailable" 6 "LEDAnimation_cmd_Error" 2 "LEDAnimation_cmd_UnlockAnimation" 1 "LEDAnimation_cmd_LockAnimation" 0 "LEDAnimation_cmd_NoAction" ;
VAL_ 826 DoorsAjar_stat_ISig_6 7 "DoorsAjar_stat_NotAvailable" 6 "DoorsAjar_stat_Error" 5 "DoorsAjar_stat_Spare" 4 "DoorsAjar_stat_BothDoorsAreOpen" 3 "DoorsAjar_stat_PassengerDoorIsOpen" 2 "DoorsAjar_stat_DriverDoorIsOpen" 1 "DoorsAjar_stat_BothDoorsAreClosed" 0 "DoorsAjar_stat_Idle" ;
VAL_ 826 BBSlidable5thWheelCmd 3 "NotDriven_Driven_NotAvailable" 2 "NotDriven_Driven_Error" 1 "NotDriven_Driven_Driven" 0 "NotDriven_Driven_NotDriven" ;
VAL_ 826 LampCheck_cmd_ISig_6 3 "LampCheck_NotAvailable" 2 "LampCheck_Error" 1 "LampCheck_PerformLampCheck" 0 "LampCheck_NoAction" ;
VAL_ 826 BlackOutandConvoyMode_rqst_ISig_ 7 "BlackOutandConvoyMode_rqst_NotAvailable" 6 "BlackOutandConvoyMode_rqst_Error" 5 "BlackOutandConvoyMode_rqst_SpareValue_02" 4 "BlackOutandConvoyMode_rqst_SpareValue_01" 3 "BlackOutandConvoyMode_rqst_SpareValue" 2 "BlackOutandConvoyMode_rqst_ConvoyMode" 1 "BlackOutandConvoyMode_rqst_BlackOutMode" 0 "BlackOutandConvoyMode_rqst_NormalMode" ;
VAL_ 826 AreaInhibit 3 "Inhibit_NotAvailable" 2 "Inhibit_Error" 1 "Inhibit_InhibitActive" 0 "Inhibit_NoInhibit" ;
VAL_ 826 MaintBatteryReset 3 "Request_NotAvailable" 2 "Request_Error" 1 "Request_RequestActive" 0 "Request_NotRequested" ;
VAL_ 826 ECSStandByRequest_ISig_6 7 "ECSStandByRequest_NotAvailable" 6 "ECSStandByRequest_Error" 5 "ECSStandByRequest_Reserved_01" 4 "ECSStandByRequest_Reserved" 3 "ECSStandByRequest_StandbyRequestedWRC" 2 "ECSStandByRequest_StandbyRequestedRCECS" 1 "ECSStandByRequest_Initiate" 0 "ECSStandByRequest_NoRequest" ;
VAL_ 826 PloughLampModeStatus_ISig_6 3 "InactiveActive_NotAvailable" 2 "InactiveActive_Error" 1 "InactiveActive_Active" 0 "InactiveActive_Inactive" ;
VAL_ 826 BBContUnlockCmd 3 "NotDriven_Driven_NotAvailable" 2 "NotDriven_Driven_Error" 1 "NotDriven_Driven_Driven" 0 "NotDriven_Driven_NotDriven" ;
VAL_ 826 EngineActiveStatus_ISig_6 15 "EngineActiveStatus_NotAvailable" 14 "EngineActiveStatus_Error" 13 "EngineActiveStatus_Spare_10" 12 "EngineActiveStatus_Spare_09" 11 "EngineActiveStatus_Spare_08" 10 "EngineActiveStatus_Spare_07" 9 "EngineActiveStatus_Spare_06" 8 "EngineActiveStatus_Spare_05" 7 "EngineActiveStatus_Spare_04" 6 "EngineActiveStatus_Spare_03" 5 "EngineActiveStatus_Spare_02" 4 "EngineActiveStatus_Spare_01" 3 "EngineActiveStatus_Spare" 2 "EngineActiveStatus_ElectricPropulsionSystemRunning" 1 "EngineActiveStatus_InternalCombustionEngineRunning" 0 "EngineActiveStatus_DrivelineNotActive" ;
VAL_ 826 BatteryCapacity_ISig_6 15 "BatteryType_NotAvailable" 14 "BatteryType_Error" 13 "BatteryType_NoSelectionMade" 12 "BatteryType_OtherBatteryType" 11 "BatteryType_BatteryType11" 10 "BatteryType_BatteryType10" 9 "BatteryType_BatteryType9" 8 "BatteryType_BatteryType8" 7 "BatteryType_BatteryType7" 6 "BatteryType_BatteryType6" 5 "BatteryType_BatteryType5" 4 "BatteryType_BatteryType4" 3 "BatteryType_BatteryType3" 2 "BatteryType_BatteryType2" 1 "BatteryType_BatteryType1" 0 "BatteryType_BatteryType0" ;
VAL_ 946 TransferCaseOrSplitboxPTOMode_IS 3 "InactiveActive_NotAvailable" 2 "InactiveActive_Error" 1 "InactiveActive_Active" 0 "InactiveActive_Inactive" ;
VAL_ 946 EPBHillHolderMode_ISig_6 7 "EPBHillHolderMode_NotAvailable" 6 "EPBHillHolderMode_Reserved" 5 "EPBHillHolderMode_NotDefined_02" 4 "EPBHillHolderMode_NotDefined_01" 3 "EPBHillHolderMode_NotDefined" 2 "EPBHillHolderMode_ActiveWillChngToInactiveInShortTime" 1 "EPBHillHolderMode_Active" 0 "EPBHillHolderMode_Inactive" ;
VAL_ 946 Pto4Status_ISig_6 3 "InactiveActive_NotAvailable" 2 "InactiveActive_Error" 1 "InactiveActive_Active" 0 "InactiveActive_Inactive" ;
VAL_ 946 CartridgeChangedDrvrReset_rqst 3 "DisableEnable_NotAvailable" 2 "DisableEnable_Error" 1 "DisableEnable_Enable" 0 "DisableEnable_Disable" ;
VAL_ 946 Pto2Status_ISig_6 3 "InactiveActive_NotAvailable" 2 "InactiveActive_Error" 1 "InactiveActive_Active" 0 "InactiveActive_Inactive" ;
VAL_ 946 AcceleratorPedalQuality_ISig_6 3 "PrimaryAcceleratorPedalQuality_NotAvailable" 2 "PrimaryAcceleratorPedalQuality_ErrorMode" 1 "PrimaryAcceleratorPedalQuality_DowngradedMode" 0 "PrimaryAcceleratorPedalQuality_NormalMode" ;
VAL_ 946 Pto2DrivingRequest 3 "OffOn_NotAvailable" 2 "OffOn_Error" 1 "OffOn_On" 0 "OffOn_Off" ;
VAL_ 946 Pto3Status_ISig_6 3 "InactiveActive_NotAvailable" 2 "InactiveActive_Error" 1 "InactiveActive_Active" 0 "InactiveActive_Inactive" ;
VAL_ 946 ReducedLoadMode_stat_ISig_6 3 "ReducedLoadMode_stat_NotAvailable" 2 "ReducedLoadMode_stat_Error" 1 "ReducedLoadMode_stat_ReducedLoadMode" 0 "ReducedLoadMode_stat_NormalMode" ;
VAL_ 946 RearAxleDiffLockActvnDrvrReq_ISi 3 "DisengageEngage_NotAvailable" 2 "DisengageEngage_Error" 1 "DisengageEngage_Engage" 0 "DisengageEngage_Disengage" ;
VAL_ 946 RrInterAxlDiffLockActvnFuncReq 3 "DisengagedEngaged_NotAvailable" 2 "DisengagedEngaged_Error" 1 "DisengagedEngaged_Engaged" 0 "DisengagedEngaged_Disengaged" ;
VAL_ 946 Pto1DrivingRequest 3 "OffOn_NotAvailable" 2 "OffOn_Error" 1 "OffOn_On" 0 "OffOn_Off" ;
VAL_ 946 EngineStopRequest_ISig_6 3 "Request_NotAvailable" 2 "Request_Error" 1 "Request_RequestActive" 0 "Request_NotRequested" ;
VAL_ 946 AcceleratorPedalStatus_ISig_6 7 "AcceleratorPedalStatus_NotAvailable" 6 "AcceleratorPedalStatus_Error" 5 "AcceleratorPedalStatus_Spare3" 4 "AcceleratorPedalStatus_Spare2" 3 "AcceleratorPedalStatus_Spare1" 2 "AcceleratorPedalStatus_PrimAndSecPedalInhibited" 1 "AcceleratorPedalStatus_SecPedActPrimPedNotAct" 0 "AcceleratorPedalStatus_SecPedNotActPrimPedAct" ;
VAL_ 946 XBRActiveControlMode_ISig_6 15 "XBRActiveControlMode_NotAvailable" 3 "XBRActiveControlMode_MaximumModeOfXBRAccelControlExecuted" 2 "XBRActiveControlMode_AdditionModeoXBRAccelControlExecuted" 1 "XBRActiveControlMode_DriversBrakeDemandExecNoExtBrakeDemand" 0 "XBRActiveControlMode_NoBrakeDemandBeingExecutedDefaultMode" ;
VAL_ 946 RearAxleDiffLockActvnFuncReq_ISi 3 "RearAxleDiffLockActvnFuncReq_TakeNoAction" 2 "RearAxleDiffLockActvnFuncReq_Reserved" 1 "RearAxleDiffLockActvnFuncReq_DisengageDifferentialLock" 0 "RearAxleDiffLockActvnFuncReq_EngageDifferentialLock" ;
VAL_ 946 RrInterAxlDiffLockActvnDrvrReq_I 3 "DisengageEngage_NotAvailable" 2 "DisengageEngage_Error" 1 "DisengageEngage_Engage" 0 "DisengageEngage_Disengage" ;
VAL_ 946 KeyPosition_ISig_6 7 "KeyPosition_NotAvailable" 6 "KeyPosition_ErrorIndicator" 5 "KeyPosition_IgnitionKeyInCrankPosition" 4 "KeyPosition_IgnitionKeyInPreheatPosition" 3 "KeyPosition_IgnitionKeyIn15PositionNormalDrivingPosition" 2 "KeyPosition_IgnitionKeyInAccessoryPosition" 1 "KeyPosition_IgnitionKeyInOffPosition" 0 "KeyPosition_KeyOut" ;
VAL_ 946 Pto1Status_ISig_6 3 "InactiveActive_NotAvailable" 2 "InactiveActive_Error" 1 "InactiveActive_Active" 0 "InactiveActive_Inactive" ;
VAL_ 945 EcoRollActiveStatus_ISig_6 3 "InactiveActive_NotAvailable" 2 "InactiveActive_Error" 1 "InactiveActive_Active" 0 "InactiveActive_Inactive" ;
VAL_ 945 RearAxleSteeringFunctionDsbl_ISi 3 "RearAxleSteeringFunctionDsbl_NotAvailable" 2 "RearAxleSteeringFunctionDsbl_Error" 1 "RearAxleSteeringFunctionDsbl_DisableRequest" 0 "RearAxleSteeringFunctionDsbl_NoDisableRequest" ;
SIG_GROUP_ 519 GlareFreeArea02_sg_ISig_6 1 : GlareFreeArea02_LeftAngle_ISig_6 GlareFreeArea02_Distance_ISig_6 GlareFreeArea02_RightAngle_ISig_;
SIG_GROUP_ 518 GlareFreeArea03_sg_ISig_6 1 : GlareFreeArea03_RightAngle_ISig_ GlareFreeArea03_LeftAngle_ISig_6 GlareFreeArea03_Distance_ISig_6;
SIG_GROUP_ 518 GlareFreeArea01_sg_ISig_6 1 : GlareFreeArea01_Distance_ISig_6 GlareFreeArea01_LeftAngle_ISig_6 GlareFreeArea01_RightAngle_ISig_;
SIG_GROUP_ 1370 TPMSetPresThresCfg_sg_ISig_6 1 : TPMSetPresThresCfg_AxleNr_ISig_6 TPMSetPresThresCfg_VehiclePos_IS TPMSetPresThresCfg_ExtOverPres_I TPMSetPresThresCfg_ExtUnderPres_ TPMSetPresThresCfg_UnderPres_ISi TPMSetPresThresCfg_OverPres_ISig;
SIG_GROUP_ 1370 TPMSetAxleTireConfig_sg_ISig_6 1 : TPMSetAxleTireConfig_Axle2_ISig_ TPMSetAxleTireConfig_Axle4_ISig_ TPMSetAxleTireConfig_Axle1_ISig_ TPMSetAxleTireConfig_Axle5_ISig_ TPMSetAxleTireConfig_VehiclePos_ TPMSetAxleTireConfig_Axle3_ISig_;
SIG_GROUP_ 1373 TPMPosOfWMReq_sg_ISig_6 1 : TPMPosOfWMReq_VehiclePos_ISig_6 TPMPosOfWMReq_TireId_ISig_6;
SIG_GROUP_ 1373 TPMSetAxleRefPres_sg_ISig_6 1 : TPMSetAxleRefPres_Axle2_ISig_6 TPMSetAxleRefPres_Axle1_ISig_6 TPMSetAxleRefPres_Axle3_ISig_6 TPMSetAxleRefPres_Axle4_ISig_6 TPMSetAxleRefPres_VehiclePos_ISi TPMSetAxleRefPres_Axle5_ISig_6;
SIG_GROUP_ 1249 ContTrailerBrake_sg 1 : ContTrailerBrake_MsgCounter ContTrailerBrake_Request ContTrailerBrake_MsgChecksum;
SIG_GROUP_ 390 LevelRequest_sg_ISig_6 1 : LevelRequest_RollRequest_ISig_6 LevelRequest_RearAxle_ISig_6 LevelRequest_FrontAxle_ISig_6;
